AUTOSAR XML (schema 4-3-0)
package /CAN1/ISignalGroup
  18 x i signal group:
    CAN1_SG_ABM1: i-signal=[CAN1_ABM_Passenger_ODS_Sta, CAN1_ABM_RearPassengerCTR_ODS_Sta, CAN1_ABM_RearPassengerLH_ODS_Sta, CAN1_ABM_RearPassengerRH_ODS_Sta, CAN1_AirBagFailCmd, CAN1_Checksum_ABM1, CAN1_CrashOutputSts, CAN1_DriverSeatBeltCmd, CAN1_LifeCount_ABM1, CAN1_PABSwitchCmd, CAN1_PsngrSeatBeltCmd, CAN1_RCenterSeatBeltCmd, CAN1_RDriverSeatBeltCmd, CAN1_RPsngrSeatBeltCmd, CAN1_TLHPsngrSeatBeltCmd, CAN1_TRHPsngrSeatBeltCmd], system-signal-group=CAN1_SG_ABM1
    CAN1_SG_EPB1: i-signal=[CAN1_DOA_Sta, CAN1_EPB1_CS, CAN1_EPB1_RC, CAN1_EPBCarWashMode, CAN1_EPBErrSta, CAN1_EPBExtApplyAvail, CAN1_EPBExtReleaseAvail, CAN1_EPBMsg, CAN1_EPBRLampSta, CAN1_EPBSta, CAN1_EPBStaL, CAN1_EPBStaR, CAN1_TakeOverReq], system-signal-group=CAN1_SG_EPB1
    CAN1_SG_EPS1: i-signal=[CAN1_DriIntend, CAN1_EPS_AOI_Control, CAN1_EPS_AOI_Dis_R, CAN1_EPS_CS, CAN1_EPS_DMSMode_Sta, CAN1_EPS_ESABoostOut_Trq, CAN1_EPS_ESAInpBoost_Sta, CAN1_EPS_LDW_Activation, CAN1_EPS_LDW_Unavailable, CAN1_EPS_Pwr_Consumpt, CAN1_EPS_Pwr_Consumpt_V, CAN1_EPS_Pwr_Limit, CAN1_EPS_Pwr_Limit_V, CAN1_EPS_RC, CAN1_EPS_TOI_Activation, CAN1_EPS_TOI_Dis_R, CAN1_EPS_TOI_Fault, CAN1_EPS_TOI_Unavailable, CAN1_EPS_Temp, CAN1_EPS_Temp_V, CAN1_EPS_VOL, CAN1_EPS_VOL_V, CAN1_EpasFailed, CAN1_SAS_Angle, CAN1_SAS_CAL, CAN1_SAS_Speed, CAN1_SAS_Speed_Valid, CAN1_SAS_V, CAN1_Steering_Torque, CAN1_Steering_Torque_V], system-signal-group=CAN1_SG_EPS1
    CAN1_SG_ESC1: i-signal=[CAN1_ABS_Active, CAN1_ABS_Failed, CAN1_ABS_WnlmpSta, CAN1_AVH_Active, CAN1_AVH_Failed, CAN1_Amber_WnlmpSta, CAN1_BTCS_Active, CAN1_EBD_Active, CAN1_EBD_Failed, CAN1_ESC1_CS, CAN1_ESC1_RC, CAN1_ESC_Active, CAN1_ESC_BeepReq, CAN1_ESC_EstVehSpd, CAN1_ESC_EstVehSpd_V, CAN1_ESC_Failed, CAN1_ESC_OFF_Status, CAN1_ESC_Off_lmpSta, CAN1_ESC_TSA_Active, CAN1_ESC_WnlmpSta, CAN1_ESS_Active, CAN1_Fr_PTCS_Active, CAN1_FrntAxlTrqReq_Drv, CAN1_GRADE, CAN1_HBB_Active, CAN1_HBB_Failed, CAN1_HDD_Active, CAN1_HDD_Failed, CAN1_HSA_Active, CAN1_HSA_Failed, CAN1_LF_PulseCount, CAN1_LF_PulseCount_V, CAN1_LF_RawWhlSpeed, CAN1_LF_RawWhlSpeed_V, CAN1_LF_WhlRotDir, CAN1_LR_PulseCount, CAN1_LR_PulseCount_V, CAN1_LR_RawWhlSpeed, CAN1_LR_RawWhlSpeed_V, CAN1_LR_WhlRotDir, CAN1_PBA_Active, CAN1_PBA_Failed, CAN1_RF_PulseCount, CAN1_RF_PulseCount_V, CAN1_RF_RawWhlSpeed, CAN1_RF_RawWhlSpeed_V, CAN1_RF_WhlRotDir, CAN1_RR_PulseCount, CAN1_RR_PulseCount_V, CAN1_RR_RawWhlSpeed, CAN1_RR_RawWhlSpeed_V, CAN1_RR_WhlRotDir, CAN1_RearAxlTrqReq_Drv, CAN1_Red_WnlmpSta, CAN1_Rr_PTCS_Active, CAN1_SystemVoltage, CAN1_TCS_Active, CAN1_TCS_Failed, CAN1_VehSpeed], system-signal-group=CAN1_SG_ESC1
    CAN1_SG_ESC5: i-signal=[CAN1_ACCAvail, CAN1_AEBAvail, CAN1_ActBrkLamp_Sta, CAN1_BrkDiscTempSta, CAN1_BrkPedalPos, CAN1_BrkPedalPos_Sta, CAN1_BrkSw_Sta, CAN1_BrkSw_V, CAN1_DecErrSta, CAN1_ESC5_CS, CAN1_ESC5_RC, CAN1_ESC_ADAS_Sta, CAN1_ESC_APS_Sta, CAN1_ESC_DriverBrkOverride, CAN1_ESC_Standstill, CAN1_Fr_RBC_Active, CAN1_FrntAxlTrqReq_Brk, CAN1_LatAccel, CAN1_LatAccel_V, CAN1_LongAccel, CAN1_LongAccel_V, CAN1_MCPressure, CAN1_MCPressure_V, CAN1_Meter_Ind_VehSpeed, CAN1_RDC_Active, CAN1_RearAxlTrqReq_Brk, CAN1_Rr_RBC_Active, CAN1_YawRate, CAN1_YawRate_V], system-signal-group=CAN1_SG_ESC5
    CAN1_SG_FD1_APS2: i-signal=[CAN1_APS_D_FLL, CAN1_APS_D_FLR, CAN1_APS_D_RLL, CAN1_APS_D_RLR, CAN1_APS_ExitCondition, CAN1_APS_HW_Ver, CAN1_APS_Progress_PCT, CAN1_APS_RQ_Display, CAN1_APS_SW_Ver, CAN1_PAS_A_FCL, CAN1_PAS_A_FCR, CAN1_PAS_A_FML, CAN1_PAS_A_FMR, CAN1_PAS_A_RCL, CAN1_PAS_A_RCR, CAN1_PAS_A_RML, CAN1_PAS_A_RMR, CAN1_PAS_Chime, CAN1_PAS_D_FCL, CAN1_PAS_D_FCR, CAN1_PAS_D_FML, CAN1_PAS_D_FMR, CAN1_PAS_D_RCL, CAN1_PAS_D_RCR, CAN1_PAS_D_RML, CAN1_PAS_D_RMR, CAN1_PAS_Mod_Operation, CAN1_PAS_SNSR_Layout, CAN1_PAS_Sta_F_Sys, CAN1_USS_Sta_FCL, CAN1_USS_Sta_FCR, CAN1_USS_Sta_FLL, CAN1_USS_Sta_FLR, CAN1_USS_Sta_FML, CAN1_USS_Sta_FMR, CAN1_USS_Sta_RCL, CAN1_USS_Sta_RCR, CAN1_USS_Sta_RLL, CAN1_USS_Sta_RLR, CAN1_USS_Sta_RML, CAN1_USS_Sta_RMR], system-signal-group=CAN1_SG_FD1_APS2
    CAN1_SG_FD1_APS3: i-signal=[CAN1_APS3_LifeCount, CAN1_APS3_checksum, CAN1_APSOpenPTG, CAN1_APS_DecReq, CAN1_APS_DecReq_A, CAN1_APS_Req, CAN1_APS_Sta_System, CAN1_CAAS_Sta, CAN1_FDC_APS_Active_Sta, CAN1_FDC_APS_CaasActive_Sta, CAN1_FDC_APS_CaasCtrlAvail_Sta, CAN1_FDC_APS_CaasVMCReqA_Cmd, CAN1_FDC_APS_CtrlAvail_Sta, CAN1_FDC_APS_ShftPosnReq_Cmd, CAN1_FDC_APS_SpeedReq_Cmd, CAN1_FDC_APS_VMCReqA_Cmd, CAN1_FDC_RAPS_BCMLamp_Cmd, CAN1_FDC_RAPS_BCMLockReq_Cmd, CAN1_FDC_RAPS_ErrLv1_Flg, CAN1_FDC_RAPS_PwrReqAvail_Sta, CAN1_FDC_RAPS_PwrReq_Cmd, CAN1_FDC_VCU_RAPSErrLv2_Flg, CAN1_FDC_VCU_RAPSErrLv3_Flg, CAN1_FDC_VMC_APS_Angle_Target, CAN1_FDC_VMC_APS_Rq_EPS_Ctrl, CAN1_FDC_VMC_APS_V_Rq_EPS_Ctrl, CAN1_SPTGDet, CAN1_SPTG_Sta], system-signal-group=CAN1_SG_FD1_APS3
    CAN1_SG_FD1_BCM1: i-signal=[CAN1_AllDoorSW, CAN1_AntiTheftSeatFold, CAN1_AntitheftSta, CAN1_BCM_Buzzer_Req, CAN1_BCM_DoorLock_Sta, CAN1_BrakeLamp, CAN1_CTDCtrl, CAN1_CTDLockSW, CAN1_CTDUnlockSW, CAN1_CrashDetd, CAN1_Dimmer, CAN1_DimmerEN, CAN1_DoorLockIND, CAN1_DrDoorSW, CAN1_Fr_ChargingDoorCtrl, CAN1_Fr_FogLamp, CAN1_Fr_Wiper_H, CAN1_Fr_Wiper_L, CAN1_H_Beam, CAN1_HazardSW, CAN1_HoodSW, CAN1_HornCtrl, CAN1_LBSD, CAN1_LDRL, CAN1_LTurnLP, CAN1_L_APM_WdwEnable, CAN1_L_Beam, CAN1_LockSetting, CAN1_MirrorCtrl, CAN1_MirrorDefog, CAN1_PosLamp, CAN1_PsDoorSW, CAN1_RBSD, CAN1_RDRL, CAN1_RLDoorSW, CAN1_RRDoorSW, CAN1_RTurnLP, CAN1_ReverseLamp, CAN1_RoomLampH, CAN1_RoomLampL, CAN1_Rr_ChargingDoorCtrl, CAN1_Rr_Defog, CAN1_Rr_FogLamp, CAN1_Rr_Wiper, CAN1_TailgateHDSW, CAN1_TailgateRemote, CAN1_Tailgate_SW, CAN1_TrunkRel, CAN1_WasherCtrl, CAN1_WiperFixMode], system-signal-group=CAN1_SG_FD1_BCM1
    CAN1_SG_FD1_THCM1: i-signal=[CAN1_BatteryMode, CAN1_CCU_ACLampSts, CAN1_CCU_ACMaxLampSts, CAN1_CCU_AutoLampSts, CAN1_CCU_AutoMidLampSts, CAN1_CCU_Dispaly_Request, CAN1_CCU_EcoSts, CAN1_CCU_FrtOnOffLampSts, CAN1_CCU_HEATMaxLampSts, CAN1_CCU_RrOnOffLampSts, CAN1_CCU_SyncLampSts, CAN1_CabinMode, CAN1_EDriveMode, CAN1_FD_AGS_Cmd, CAN1_FD_RecyAuto_Cmd, CAN1_Fr_Coolantflow, CAN1_Fr_Coolanttemp, CAN1_HPThermalRecoveryReq, CAN1_Rr_Coolantflow, CAN1_Rr_Coolanttemp, CAN1_sigAirIntenZon1St, CAN1_sigAirIntenZon3St, CAN1_sigAmbAirT, CAN1_sigCbnAirT, CAN1_sigCbnPTCPwrAct, CAN1_sigCbnSolarLeft, CAN1_sigCbnSolarRight, CAN1_sigClmtCmprPwrAct, CAN1_sigClntTHvBattOut, CAN1_sigDfrstSt, CAN1_sigHvacSt, CAN1_sigRecircSt, CAN1_sigSetTempZon1St, CAN1_sigSetTempZon2St, CAN1_sigSetTempZon3St, CAN1_sigWindDirZon1St, CAN1_sigWindDirZon3St], system-signal-group=CAN1_SG_FD1_THCM1
    CAN1_SG_FD1_VCU1: i-signal=[CAN1_CC_Crl_Sta, CAN1_Eng_AGSCloseSta, CAN1_Eng_ActvDmpDisabSta, CAN1_Eng_CoastDwSta, CAN1_Eng_PwrLockSta, CAN1_HVPwrSta, CAN1_LVPwrSta, CAN1_MSA_Crl_Sta, CAN1_P_Button_Sta, CAN1_PrkReq, CAN1_PrkReqValid, CAN1_PwrSta, CAN1_ShiftGearPosn, CAN1_VehMalfunLevel, CAN1_XWDMode], system-signal-group=CAN1_SG_FD1_VCU1
    CAN1_SG_FD1_VCU2: i-signal=[CAN1_ACC_CtrlAvail, CAN1_AccPedal_Override, CAN1_ActAPSPosn, CAN1_CS_VCU2_CAN1, CAN1_DriverTq, CAN1_Fr_DriverTq, CAN1_RC_VCU2_CAN1, CAN1_Rr_DriverTq, CAN1_VehActPwr], system-signal-group=CAN1_SG_FD1_VCU2
    CAN1_SG_FD1_VCU3: i-signal=[CAN1_CS_VCU3_CAN1, CAN1_EquivAccPedalSWSta, CAN1_Fr_EDUAvailBrkRgnTq, CAN1_Fr_EDUAvailBrkRgnTqValid, CAN1_Fr_EDURealARgnTq, CAN1_Fr_EDURealDrvOrBRgnTq, CAN1_Fr_EDUSpd, CAN1_Fr_EDUSpdValid, CAN1_Fr_RgnDecrSta, CAN1_Fr_RgnPermSta, CAN1_PTCS_PermSta, CAN1_RC_VCU3_CAN1, CAN1_RgnAbnorSta, CAN1_Rr_EDUAvailBrkRgnTq, CAN1_Rr_EDUAvailBrkRgnTqValid, CAN1_Rr_EDURealARgnTq, CAN1_Rr_EDURealDrvOrBRgnTq, CAN1_Rr_EDUSpd, CAN1_Rr_EDUSpdValid, CAN1_Rr_RgnDecrSta, CAN1_Rr_RgnPermSta], system-signal-group=CAN1_SG_FD1_VCU3
    CAN1_SG_FD1_VMC1: i-signal=[CAN1_AccCalcuPID, CAN1_CCMSA_SpdWar, CAN1_DISCReqAcc, CAN1_DISC_ButtSta, CAN1_DISC_DISCTargetSpd, CAN1_DISC_DISCTurn, CAN1_DISC_Sta, CAN1_FeatArbitrFinal, CAN1_FeatArbitrSta, CAN1_FeatReqSpd, CAN1_FeatSetSpdFinal_raw32, CAN1_FrontRearSlipRatioCtrl, CAN1_JerkPCT, CAN1_LatAccCtrl, CAN1_LateralCtrl, CAN1_LimitPCT, CAN1_MeterIndSpeed_raw32, CAN1_RearWhlSlipRatioCtrl, CAN1_SPD2ACCAct, CAN1_SafetyCtrl, CAN1_SingleWhlSlipRatioCtrl, CAN1_TimeGapCalcu, CAN1_VMC_ACCCtrlAvail, CAN1_VMC_AEBCtrlAvail, CAN1_VMC_CCCtrlAvail, CAN1_VMC_MSACtrlAvail, CAN1_VMC_VCU_ACC_CtrlAvail, CAN1_VMC_VCU_APSCtrlAvail_flg, CAN1_VMC_VCU_AccPedal_Override, CAN1_VMC_VCU_CC_Crl_Sta, CAN1_VMC_VCU_MSA_Crl_Sta, CAN1_VehicleSpeed_kph, CAN1_VehicleSpeed_mph], system-signal-group=CAN1_SG_FD1_VMC1
    CAN1_SG_FD1_VMC2: i-signal=[CAN1_FDC_VMC_RWS_Actv_Sta, CAN1_FDC_VMC_RWS_Dfctv_Sta, CAN1_FDC_VMC_RWS_PositionReq_Cmd, CAN1_FDC_VMC_SteerFaultReq_Cmd], system-signal-group=CAN1_SG_FD1_VMC2
    CAN1_SG_GW1_CE100_0: i-signal=[CAN1_BMS_READY, CAN1_Fr_TMSpd, CAN1_Rr_TMSpd], system-signal-group=CAN1_SG_GW1_CE100_0
    CAN1_SG_GW1_CE200_0: i-signal=[CAN1_ESC_SW_Cmd, CAN1_Roll_Eng_Mode, CAN1_Roll_Mode_SW_Cmd, CAN1_TCS_SW_Cmd], system-signal-group=CAN1_SG_GW1_CE200_0
    CAN1_SG_VMC_FCM1: i-signal=[CAN1_FDC_VMC_AngCtrlTqWtGn, CAN1_FDC_VMC_DMSMode_Cmd, CAN1_FDC_VMC_DrInpTqBstAct, CAN1_FDC_VMC_DrInpTqBstGn, CAN1_FDC_VMC_MaxAngCtrlOutTqLim, CAN1_VMC_ACC_ComfortBandLower, CAN1_VMC_ACC_ComfortBandUpper, CAN1_VMC_ACC_JerkLowerLInit, CAN1_VMC_ACC_JerkUpperLInit, CAN1_VMC_ACC_RequiredAccel, CAN1_VMC_ACC_VehHoldReq, CAN1_VMC_ADAS_ACC_Sta, CAN1_VMC_ADAS_AEBReq, CAN1_VMC_ADAS_AEB_Sta, CAN1_VMC_ADAS_DBSReq, CAN1_VMC_ADAS_FaultSta, CAN1_VMC_AEB_VehHoldReq, CAN1_VMC_FCM1_Checksum, CAN1_VMC_FCM1_LifeCount, CAN1_VMC_FCM_LDW_Fault, CAN1_VMC_FCM_LDW_Request, CAN1_VMC_FCM_LKA_StrToqReq, CAN1_VMC_FCM_LKA_TOIAct, CAN1_VMC_FCM_LKA_TOIFault], system-signal-group=CAN1_SG_VMC_FCM1
    CAN1_SG_eBST1: i-signal=[CAN1_LowBrakeFluid_Sta, CAN1_eBST_AmberWnlmpSta, CAN1_eBST_BeepReq, CAN1_eBST_RedWnlmpSta], system-signal-group=CAN1_SG_eBST1
package /CAN1/Cluster
  can cluster CAN1: baudrate=500, can-fd-baudrate=2000
    can physical channel CAN1: comm-connectors=ConnCAN1
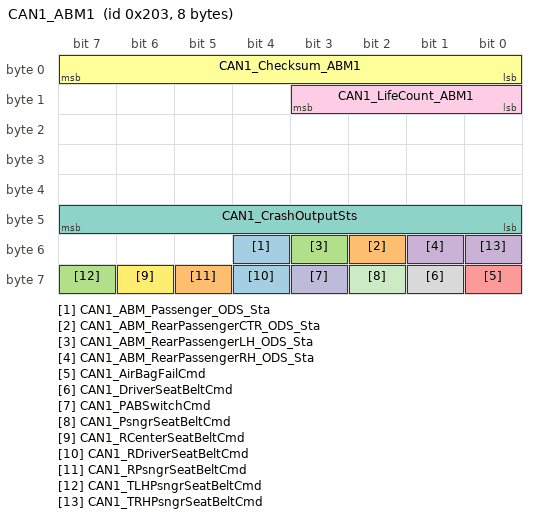
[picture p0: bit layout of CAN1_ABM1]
      frame CAN1_ABM1: id 0x203, frame-length=8, can-addressing-mode=STANDARD, can-fd-frame-support=true, can-frame-rx-behavior=CAN-FD, can-frame-tx-behavior=CAN-FD
        pdu CAN1_ABM1: length=8, minimum-delay=0.0, transmission-mode-true-timing={cyclic-timing=time-period=0.5, event-controlled-timing={number-of-repetitions=0, repetition-period=0}}, unused-bit-pattern=0
          mapping CAN1_SG_ABM1: i-signal-group=CAN1_SG_ABM1, start-position=0, transfer-property=TRIGGERED-ON-CHANGE
          signal CAN1_ABM_Passenger_ODS_Sta: start 52, 1 bit, big-endian, i-signal-type=PRIMITIVE, init-value=constant-reference=Init_CAN1_ABM_Passenger_ODS_Sta, base-type=uint8, implementation-data-type=uint8, transfer-property=TRIGGERED-ON-CHANGE
          signal CAN1_ABM_RearPassengerCTR_ODS_Sta: start 50, 1 bit, big-endian, i-signal-type=PRIMITIVE, init-value=constant-reference=Init_CAN1_ABM_RearPassengerCTR_ODS_Sta, base-type=uint8, implementation-data-type=uint8, transfer-property=TRIGGERED-ON-CHANGE
          signal CAN1_ABM_RearPassengerLH_ODS_Sta: start 51, 1 bit, big-endian, i-signal-type=PRIMITIVE, init-value=constant-reference=Init_CAN1_ABM_RearPassengerLH_ODS_Sta, base-type=uint8, implementation-data-type=uint8, transfer-property=TRIGGERED-ON-CHANGE
          signal CAN1_ABM_RearPassengerRH_ODS_Sta: start 49, 1 bit, big-endian, i-signal-type=PRIMITIVE, init-value=constant-reference=Init_CAN1_ABM_RearPassengerRH_ODS_Sta, base-type=uint8, implementation-data-type=uint8, transfer-property=TRIGGERED-ON-CHANGE
          signal CAN1_AirBagFailCmd: start 56, 1 bit, big-endian, i-signal-type=PRIMITIVE, init-value=constant-reference=Init_CAN1_AirBagFailCmd, base-type=uint8, implementation-data-type=uint8, transfer-property=TRIGGERED-ON-CHANGE
          signal CAN1_Checksum_ABM1: start 7, 8 bit, big-endian, i-signal-type=PRIMITIVE, init-value=constant-reference=Init_CAN1_Checksum_ABM1, base-type=uint8, implementation-data-type=uint8, transfer-property=TRIGGERED-ON-CHANGE
          signal CAN1_CrashOutputSts: start 47, 8 bit, big-endian, i-signal-type=PRIMITIVE, init-value=constant-reference=Init_CAN1_CrashOutputSts, base-type=uint8, implementation-data-type=uint8, transfer-property=TRIGGERED-ON-CHANGE
          signal CAN1_DriverSeatBeltCmd: start 57, 1 bit, big-endian, i-signal-type=PRIMITIVE, init-value=constant-reference=Init_CAN1_DriverSeatBeltCmd, base-type=uint8, implementation-data-type=uint8, transfer-property=TRIGGERED-ON-CHANGE
          signal CAN1_LifeCount_ABM1: start 11, 4 bit, big-endian, i-signal-type=PRIMITIVE, init-value=constant-reference=Init_CAN1_LifeCount_ABM1, base-type=uint8, implementation-data-type=uint8, transfer-property=TRIGGERED-ON-CHANGE
          signal CAN1_PABSwitchCmd: start 59, 1 bit, big-endian, i-signal-type=PRIMITIVE, init-value=constant-reference=Init_CAN1_PABSwitchCmd, base-type=uint8, implementation-data-type=uint8, transfer-property=TRIGGERED-ON-CHANGE
          signal CAN1_PsngrSeatBeltCmd: start 58, 1 bit, big-endian, i-signal-type=PRIMITIVE, init-value=constant-reference=Init_CAN1_PsngrSeatBeltCmd, base-type=uint8, implementation-data-type=uint8, transfer-property=TRIGGERED-ON-CHANGE
          signal CAN1_RCenterSeatBeltCmd: start 62, 1 bit, big-endian, i-signal-type=PRIMITIVE, init-value=constant-reference=Init_CAN1_RCenterSeatBeltCmd, base-type=uint8, implementation-data-type=uint8, transfer-property=TRIGGERED-ON-CHANGE
          signal CAN1_RDriverSeatBeltCmd: start 60, 1 bit, big-endian, i-signal-type=PRIMITIVE, init-value=constant-reference=Init_CAN1_RDriverSeatBeltCmd, base-type=uint8, implementation-data-type=uint8, transfer-property=TRIGGERED-ON-CHANGE
          signal CAN1_RPsngrSeatBeltCmd: start 61, 1 bit, big-endian, i-signal-type=PRIMITIVE, init-value=constant-reference=Init_CAN1_RPsngrSeatBeltCmd, base-type=uint8, implementation-data-type=uint8, transfer-property=TRIGGERED-ON-CHANGE
          signal CAN1_TLHPsngrSeatBeltCmd: start 63, 1 bit, big-endian, i-signal-type=PRIMITIVE, init-value=constant-reference=Init_CAN1_TLHPsngrSeatBeltCmd, base-type=uint8, implementation-data-type=uint8, transfer-property=TRIGGERED-ON-CHANGE
          signal CAN1_TRHPsngrSeatBeltCmd: start 48, 1 bit, big-endian, i-signal-type=PRIMITIVE, init-value=constant-reference=Init_CAN1_TRHPsngrSeatBeltCmd, base-type=uint8, implementation-data-type=uint8, transfer-property=TRIGGERED-ON-CHANGE
      frame CAN1_DiagFuncReqFT: id 0x7D0, frame-length=8, can-addressing-mode=STANDARD, can-fd-frame-support=false, can-frame-rx-behavior=CAN-20, can-frame-tx-behavior=CAN-20
        n pdu CAN1_DiagFuncReqFT: length=8
      frame CAN1_DiagFuncReqOBD: id 0x7DF, frame-length=8, can-addressing-mode=STANDARD, can-fd-frame-support=true, can-frame-rx-behavior=CAN-FD, can-frame-tx-behavior=CAN-FD
        n pdu CAN1_DiagFuncReqOBD: length=8
      frame CAN1_DiagPhysReqToABM: id 0x6B1, frame-length=8, can-addressing-mode=STANDARD, can-fd-frame-support=true, can-frame-rx-behavior=CAN-FD, can-frame-tx-behavior=CAN-FD
        n pdu CAN1_DiagPhysReqToABM: length=8
      frame CAN1_DiagPhysReqToEPS: id 0x6A1, frame-length=8, can-addressing-mode=STANDARD, can-fd-frame-support=true, can-frame-rx-behavior=CAN-FD, can-frame-tx-behavior=CAN-FD
        n pdu CAN1_DiagPhysReqToEPS: length=8
      frame CAN1_DiagPhysReqToESC: id 0x681, frame-length=8, can-addressing-mode=STANDARD, can-fd-frame-support=false, can-frame-rx-behavior=CAN-20, can-frame-tx-behavior=CAN-20
        n pdu CAN1_DiagPhysReqToESC: length=8
      frame CAN1_DiagPhysReqToOCS: id 0x6A2, frame-length=64, can-addressing-mode=STANDARD, can-fd-frame-support=true, can-frame-rx-behavior=CAN-FD, can-frame-tx-behavior=CAN-FD
        n pdu CAN1_DiagPhysReqToOCS: length=8
      frame CAN1_DiagPhysReqToScrap: id 0x7F1, frame-length=8, can-addressing-mode=STANDARD, can-fd-frame-support=true, can-frame-rx-behavior=CAN-FD, can-frame-tx-behavior=CAN-FD
        n pdu CAN1_DiagPhysReqToScrap: length=8
      frame CAN1_DiagPhysReqToeBST: id 0x691, frame-length=8, can-addressing-mode=STANDARD, can-fd-frame-support=false, can-frame-rx-behavior=CAN-20, can-frame-tx-behavior=CAN-20
        n pdu CAN1_DiagPhysReqToeBST: length=8
      frame CAN1_DiagRespFromABM: id 0x631, frame-length=8, can-addressing-mode=STANDARD, can-fd-frame-support=true, can-frame-rx-behavior=CAN-FD, can-frame-tx-behavior=CAN-FD
        n pdu CAN1_DiagRespFromABM: length=8
      frame CAN1_DiagRespFromEPS: id 0x621, frame-length=8, can-addressing-mode=STANDARD, can-fd-frame-support=true, can-frame-rx-behavior=CAN-FD, can-frame-tx-behavior=CAN-FD
        n pdu CAN1_DiagRespFromEPS: length=8
      frame CAN1_DiagRespFromESC: id 0x601, frame-length=8, can-addressing-mode=STANDARD, can-fd-frame-support=false, can-frame-rx-behavior=CAN-20, can-frame-tx-behavior=CAN-20
        n pdu CAN1_DiagRespFromESC: length=8
      frame CAN1_DiagRespFromOCS: id 0x622, frame-length=64, can-addressing-mode=STANDARD, can-fd-frame-support=true, can-frame-rx-behavior=CAN-FD, can-frame-tx-behavior=CAN-FD
        n pdu CAN1_DiagRespFromOCS: length=8
      frame CAN1_DiagRespFromScrap: id 0x7F9, frame-length=8, can-addressing-mode=STANDARD, can-fd-frame-support=true, can-frame-rx-behavior=CAN-FD, can-frame-tx-behavior=CAN-FD
        n pdu CAN1_DiagRespFromScrap: length=8
      frame CAN1_DiagRespFromeBST: id 0x611, frame-length=8, can-addressing-mode=STANDARD, can-fd-frame-support=false, can-frame-rx-behavior=CAN-20, can-frame-tx-behavior=CAN-20
        n pdu CAN1_DiagRespFromeBST: length=8
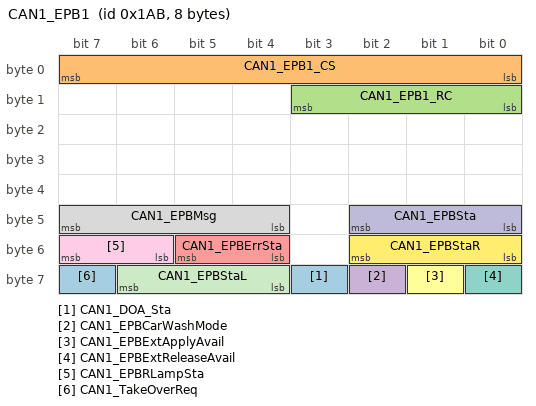
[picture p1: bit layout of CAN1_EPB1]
      frame CAN1_EPB1: id 0x1AB, frame-length=8, can-addressing-mode=STANDARD, can-fd-frame-support=true, can-frame-rx-behavior=CAN-FD, can-frame-tx-behavior=CAN-FD
        pdu CAN1_EPB1: length=8, minimum-delay=0.0, transmission-mode-true-timing=cyclic-timing=time-period=0.04, unused-bit-pattern=0
          mapping CAN1_SG_EPB1: i-signal-group=CAN1_SG_EPB1, start-position=0, transfer-property=PENDING
          signal CAN1_DOA_Sta: start 59, 1 bit, big-endian, i-signal-type=PRIMITIVE, init-value=constant-reference=Init_CAN1_DOA_Sta, base-type=uint8, implementation-data-type=uint8, transfer-property=PENDING
          signal CAN1_EPB1_CS: start 7, 8 bit, big-endian, i-signal-type=PRIMITIVE, init-value=constant-reference=Init_CAN1_EPB1_CS, base-type=uint8, implementation-data-type=uint8, transfer-property=PENDING
          signal CAN1_EPB1_RC: start 11, 4 bit, big-endian, i-signal-type=PRIMITIVE, init-value=constant-reference=Init_CAN1_EPB1_RC, base-type=uint8, implementation-data-type=uint8, transfer-property=PENDING
          signal CAN1_EPBCarWashMode: start 58, 1 bit, big-endian, i-signal-type=PRIMITIVE, init-value=constant-reference=Init_CAN1_EPBCarWashMode, base-type=uint8, implementation-data-type=uint8, transfer-property=PENDING
          signal CAN1_EPBErrSta: start 53, 2 bit, big-endian, i-signal-type=PRIMITIVE, init-value=constant-reference=Init_CAN1_EPBErrSta, base-type=uint8, implementation-data-type=uint8, transfer-property=PENDING
          signal CAN1_EPBExtApplyAvail: start 57, 1 bit, big-endian, i-signal-type=PRIMITIVE, init-value=constant-reference=Init_CAN1_EPBExtApplyAvail, base-type=uint8, implementation-data-type=uint8, transfer-property=PENDING
          signal CAN1_EPBExtReleaseAvail: start 56, 1 bit, big-endian, i-signal-type=PRIMITIVE, init-value=constant-reference=Init_CAN1_EPBExtReleaseAvail, base-type=uint8, implementation-data-type=uint8, transfer-property=PENDING
          signal CAN1_EPBMsg: start 47, 4 bit, big-endian, i-signal-type=PRIMITIVE, init-value=constant-reference=Init_CAN1_EPBMsg, base-type=uint8, implementation-data-type=uint8, transfer-property=PENDING
          signal CAN1_EPBRLampSta: start 55, 2 bit, big-endian, i-signal-type=PRIMITIVE, init-value=constant-reference=Init_CAN1_EPBRLampSta, base-type=uint8, implementation-data-type=uint8, transfer-property=PENDING
          signal CAN1_EPBSta: start 42, 3 bit, big-endian, i-signal-type=PRIMITIVE, init-value=constant-reference=Init_CAN1_EPBSta, base-type=uint8, implementation-data-type=uint8, transfer-property=PENDING
          signal CAN1_EPBStaL: start 62, 3 bit, big-endian, i-signal-type=PRIMITIVE, init-value=constant-reference=Init_CAN1_EPBStaL, base-type=uint8, implementation-data-type=uint8, transfer-property=PENDING
          signal CAN1_EPBStaR: start 50, 3 bit, big-endian, i-signal-type=PRIMITIVE, init-value=constant-reference=Init_CAN1_EPBStaR, base-type=uint8, implementation-data-type=uint8, transfer-property=PENDING
          signal CAN1_TakeOverReq: start 63, 1 bit, big-endian, i-signal-type=PRIMITIVE, init-value=constant-reference=Init_CAN1_TakeOverReq, base-type=uint8, implementation-data-type=uint8, transfer-property=PENDING
      frame CAN1_EPS1: id 0x187, frame-length=16, can-addressing-mode=STANDARD, can-fd-frame-support=true, can-frame-rx-behavior=CAN-FD, can-frame-tx-behavior=CAN-FD
        pdu CAN1_EPS1: length=16, minimum-delay=0.0, transmission-mode-true-timing=cyclic-timing=time-period=0.01, unused-bit-pattern=0
          mapping CAN1_SG_EPS1: i-signal-group=CAN1_SG_EPS1, start-position=0, transfer-property=PENDING
          signal CAN1_DriIntend: start 18, 2 bit, big-endian, i-signal-type=PRIMITIVE, init-value=constant-reference=Init_CAN1_DriIntend, base-type=uint8, implementation-data-type=uint8, transfer-property=PENDING
          signal CAN1_EPS_AOI_Control: start 20, 2 bit, big-endian, i-signal-type=PRIMITIVE, init-value=constant-reference=Init_CAN1_EPS_AOI_Control, base-type=uint8, implementation-data-type=uint8, transfer-property=PENDING
          signal CAN1_EPS_AOI_Dis_R: start 28, 4 bit, big-endian, i-signal-type=PRIMITIVE, init-value=constant-reference=Init_CAN1_EPS_AOI_Dis_R, base-type=uint8, implementation-data-type=uint8, transfer-property=PENDING
          signal CAN1_EPS_CS: start 7, 8 bit, big-endian, i-signal-type=PRIMITIVE, init-value=constant-reference=Init_CAN1_EPS_CS, base-type=uint8, implementation-data-type=uint8, transfer-property=PENDING
          signal CAN1_EPS_DMSMode_Sta: start 123, 4 bit, big-endian, i-signal-type=PRIMITIVE, init-value=constant-reference=Init_CAN1_EPS_DMSMode_Sta, base-type=uint8, implementation-data-type=uint8, transfer-property=PENDING
          signal CAN1_EPS_ESABoostOut_Trq: start 111, 6 bit, big-endian, i-signal-type=PRIMITIVE, init-value=constant-reference=Init_CAN1_EPS_ESABoostOut_Trq, base-type=uint8, implementation-data-type=uint8, transfer-property=PENDING
          signal CAN1_EPS_ESAInpBoost_Sta: start 105, 1 bit, big-endian, i-signal-type=PRIMITIVE, init-value=constant-reference=Init_CAN1_EPS_ESAInpBoost_Sta, base-type=uint8, implementation-data-type=uint8, transfer-property=PENDING
          signal CAN1_EPS_LDW_Activation: start 90, 2 bit, big-endian, i-signal-type=PRIMITIVE, init-value=constant-reference=Init_CAN1_EPS_LDW_Activation, base-type=uint8, implementation-data-type=uint8, transfer-property=PENDING
          signal CAN1_EPS_LDW_Unavailable: start 91, 1 bit, big-endian, i-signal-type=PRIMITIVE, init-value=constant-reference=Init_CAN1_EPS_LDW_Unavailable, base-type=uint8, implementation-data-type=uint8, transfer-property=PENDING
          signal CAN1_EPS_Pwr_Consumpt: start 104, 9 bit, big-endian, i-signal-type=PRIMITIVE, init-value=constant-reference=Init_CAN1_EPS_Pwr_Consumpt, base-type=uint16, implementation-data-type=uint16, transfer-property=PENDING
          signal CAN1_EPS_Pwr_Consumpt_V: start 61, 1 bit, big-endian, i-signal-type=PRIMITIVE, init-value=constant-reference=Init_CAN1_EPS_Pwr_Consumpt_V, base-type=uint8, implementation-data-type=uint8, transfer-property=PENDING
          signal CAN1_EPS_Pwr_Limit: start 88, 9 bit, big-endian, i-signal-type=PRIMITIVE, init-value=constant-reference=Init_CAN1_EPS_Pwr_Limit, base-type=uint16, implementation-data-type=uint16, transfer-property=PENDING
          signal CAN1_EPS_Pwr_Limit_V: start 59, 1 bit, big-endian, i-signal-type=PRIMITIVE, init-value=constant-reference=Init_CAN1_EPS_Pwr_Limit_V, base-type=uint8, implementation-data-type=uint8, transfer-property=PENDING
          signal CAN1_EPS_RC: start 11, 4 bit, big-endian, i-signal-type=PRIMITIVE, init-value=constant-reference=Init_CAN1_EPS_RC, base-type=uint8, implementation-data-type=uint8, transfer-property=PENDING
          signal CAN1_EPS_TOI_Activation: start 21, 1 bit, big-endian, i-signal-type=PRIMITIVE, init-value=constant-reference=Init_CAN1_EPS_TOI_Activation, base-type=uint8, implementation-data-type=uint8, transfer-property=PENDING
          signal CAN1_EPS_TOI_Dis_R: start 16, 4 bit, big-endian, i-signal-type=PRIMITIVE, init-value=constant-reference=Init_CAN1_EPS_TOI_Dis_R, base-type=uint8, implementation-data-type=uint8, transfer-property=PENDING
          signal CAN1_EPS_TOI_Fault: start 23, 1 bit, big-endian, i-signal-type=PRIMITIVE, init-value=constant-reference=Init_CAN1_EPS_TOI_Fault, base-type=uint8, implementation-data-type=uint8, transfer-property=PENDING
          signal CAN1_EPS_TOI_Unavailable: start 22, 1 bit, big-endian, i-signal-type=PRIMITIVE, init-value=constant-reference=Init_CAN1_EPS_TOI_Unavailable, base-type=uint8, implementation-data-type=uint8, transfer-property=PENDING
          signal CAN1_EPS_Temp: start 87, 8 bit, big-endian, i-signal-type=PRIMITIVE, init-value=constant-reference=Init_CAN1_EPS_Temp, base-type=uint8, implementation-data-type=uint8, transfer-property=PENDING
          signal CAN1_EPS_Temp_V: start 93, 1 bit, big-endian, i-signal-type=PRIMITIVE, init-value=constant-reference=Init_CAN1_EPS_Temp_V, base-type=uint8, implementation-data-type=uint8, transfer-property=PENDING
          signal CAN1_EPS_VOL: start 79, 8 bit, big-endian, i-signal-type=PRIMITIVE, init-value=constant-reference=Init_CAN1_EPS_VOL, base-type=uint8, implementation-data-type=uint8, transfer-property=PENDING
          signal CAN1_EPS_VOL_V: start 92, 1 bit, big-endian, i-signal-type=PRIMITIVE, init-value=constant-reference=Init_CAN1_EPS_VOL_V, base-type=uint8, implementation-data-type=uint8, transfer-property=PENDING
          signal CAN1_EpasFailed: start 95, 2 bit, big-endian, i-signal-type=PRIMITIVE, init-value=constant-reference=Init_CAN1_EpasFailed, base-type=uint8, implementation-data-type=uint8, transfer-property=PENDING
          signal CAN1_SAS_Angle: start 47, 16 bit, big-endian, i-signal-type=PRIMITIVE, init-value=constant-reference=Init_CAN1_SAS_Angle, base-type=uint16, implementation-data-type=uint16, transfer-property=PENDING
          signal CAN1_SAS_CAL: start 63, 1 bit, big-endian, i-signal-type=PRIMITIVE, init-value=constant-reference=Init_CAN1_SAS_CAL, base-type=uint8, implementation-data-type=uint8, transfer-property=PENDING
          signal CAN1_SAS_Speed: start 39, 8 bit, big-endian, i-signal-type=PRIMITIVE, init-value=constant-reference=Init_CAN1_SAS_Speed, base-type=uint8, implementation-data-type=uint8, transfer-property=PENDING
          signal CAN1_SAS_Speed_Valid: start 62, 1 bit, big-endian, i-signal-type=PRIMITIVE, init-value=constant-reference=Init_CAN1_SAS_Speed_Valid, base-type=uint8, implementation-data-type=uint8, transfer-property=PENDING
          signal CAN1_SAS_V: start 24, 1 bit, big-endian, i-signal-type=PRIMITIVE, init-value=constant-reference=Init_CAN1_SAS_V, base-type=uint8, implementation-data-type=uint8, transfer-property=PENDING
          signal CAN1_Steering_Torque: start 58, 11 bit, big-endian, i-signal-type=PRIMITIVE, init-value=constant-reference=Init_CAN1_Steering_Torque, base-type=uint16, implementation-data-type=uint16, transfer-property=PENDING
          signal CAN1_Steering_Torque_V: start 60, 1 bit, big-endian, i-signal-type=PRIMITIVE, init-value=constant-reference=Init_CAN1_Steering_Torque_V, base-type=uint8, implementation-data-type=uint8, transfer-property=PENDING
      frame CAN1_ESC1: id 0x152, frame-length=32, can-addressing-mode=STANDARD, can-fd-frame-support=true, can-frame-rx-behavior=CAN-FD, can-frame-tx-behavior=CAN-FD
        pdu CAN1_ESC1: length=32, minimum-delay=0.0, transmission-mode-true-timing=cyclic-timing=time-period=0.01, unused-bit-pattern=0
          mapping CAN1_SG_ESC1: i-signal-group=CAN1_SG_ESC1, start-position=0, transfer-property=PENDING
          signal CAN1_ABS_Active: start 187, 1 bit, big-endian, i-signal-type=PRIMITIVE, init-value=constant-reference=Init_CAN1_ABS_Active, base-type=uint8, implementation-data-type=uint8, transfer-property=PENDING
          signal CAN1_ABS_Failed: start 183, 1 bit, big-endian, i-signal-type=PRIMITIVE, init-value=constant-reference=Init_CAN1_ABS_Failed, base-type=uint8, implementation-data-type=uint8, transfer-property=PENDING
          signal CAN1_ABS_WnlmpSta: start 206, 1 bit, big-endian, i-signal-type=PRIMITIVE, init-value=constant-reference=Init_CAN1_ABS_WnlmpSta, base-type=uint8, implementation-data-type=uint8, transfer-property=PENDING
          signal CAN1_AVH_Active: start 177, 1 bit, big-endian, i-signal-type=PRIMITIVE, init-value=constant-reference=Init_CAN1_AVH_Active, base-type=uint8, implementation-data-type=uint8, transfer-property=PENDING
          signal CAN1_AVH_Failed: start 173, 1 bit, big-endian, i-signal-type=PRIMITIVE, init-value=constant-reference=Init_CAN1_AVH_Failed, base-type=uint8, implementation-data-type=uint8, transfer-property=PENDING
          signal CAN1_Amber_WnlmpSta: start 178, 1 bit, big-endian, i-signal-type=PRIMITIVE, init-value=constant-reference=Init_CAN1_Amber_WnlmpSta, base-type=uint8, implementation-data-type=uint8, transfer-property=PENDING
          signal CAN1_BTCS_Active: start 179, 1 bit, big-endian, i-signal-type=PRIMITIVE, init-value=constant-reference=Init_CAN1_BTCS_Active, base-type=uint8, implementation-data-type=uint8, transfer-property=PENDING
          signal CAN1_EBD_Active: start 186, 1 bit, big-endian, i-signal-type=PRIMITIVE, init-value=constant-reference=Init_CAN1_EBD_Active, base-type=uint8, implementation-data-type=uint8, transfer-property=PENDING
          signal CAN1_EBD_Failed: start 182, 1 bit, big-endian, i-signal-type=PRIMITIVE, init-value=constant-reference=Init_CAN1_EBD_Failed, base-type=uint8, implementation-data-type=uint8, transfer-property=PENDING
          signal CAN1_ESC1_CS: start 7, 8 bit, big-endian, i-signal-type=PRIMITIVE, init-value=constant-reference=Init_CAN1_ESC1_CS, base-type=uint8, implementation-data-type=uint8, transfer-property=PENDING
          signal CAN1_ESC1_RC: start 11, 4 bit, big-endian, i-signal-type=PRIMITIVE, init-value=constant-reference=Init_CAN1_ESC1_RC, base-type=uint8, implementation-data-type=uint8, transfer-property=PENDING
          signal CAN1_ESC_Active: start 189, 1 bit, big-endian, i-signal-type=PRIMITIVE, init-value=constant-reference=Init_CAN1_ESC_Active, base-type=uint8, implementation-data-type=uint8, transfer-property=PENDING
          signal CAN1_ESC_BeepReq: start 150, 1 bit, big-endian, i-signal-type=PRIMITIVE, init-value=constant-reference=Init_CAN1_ESC_BeepReq, base-type=uint8, implementation-data-type=uint8, transfer-property=PENDING
          signal CAN1_ESC_EstVehSpd: start 203, 12 bit, big-endian, i-signal-type=PRIMITIVE, init-value=constant-reference=Init_CAN1_ESC_EstVehSpd, base-type=uint16, implementation-data-type=uint16, transfer-property=PENDING
          signal CAN1_ESC_EstVehSpd_V: start 204, 1 bit, big-endian, i-signal-type=PRIMITIVE, init-value=constant-reference=Init_CAN1_ESC_EstVehSpd_V, base-type=uint8, implementation-data-type=uint8, transfer-property=PENDING
          signal CAN1_ESC_Failed: start 169, 1 bit, big-endian, i-signal-type=PRIMITIVE, init-value=constant-reference=Init_CAN1_ESC_Failed, base-type=uint8, implementation-data-type=uint8, transfer-property=PENDING
          signal CAN1_ESC_OFF_Status: start 149, 2 bit, big-endian, i-signal-type=PRIMITIVE, init-value=constant-reference=Init_CAN1_ESC_OFF_Status, base-type=uint8, implementation-data-type=uint8, transfer-property=PENDING
          signal CAN1_ESC_Off_lmpSta: start 207, 1 bit, big-endian, i-signal-type=PRIMITIVE, init-value=constant-reference=Init_CAN1_ESC_Off_lmpSta, base-type=uint8, implementation-data-type=uint8, transfer-property=PENDING
          signal CAN1_ESC_TSA_Active: start 223, 1 bit, big-endian, i-signal-type=PRIMITIVE, init-value=constant-reference=Init_CAN1_ESC_TSA_Active, base-type=uint8, implementation-data-type=uint8, transfer-property=PENDING
          signal CAN1_ESC_WnlmpSta: start 185, 2 bit, big-endian, i-signal-type=PRIMITIVE, init-value=constant-reference=Init_CAN1_ESC_WnlmpSta, base-type=uint8, implementation-data-type=uint8, transfer-property=PENDING
          signal CAN1_ESS_Active: start 180, 1 bit, big-endian, i-signal-type=PRIMITIVE, init-value=constant-reference=Init_CAN1_ESS_Active, base-type=uint8, implementation-data-type=uint8, transfer-property=PENDING
          signal CAN1_Fr_PTCS_Active: start 27, 1 bit, big-endian, i-signal-type=PRIMITIVE, init-value=constant-reference=Init_CAN1_Fr_PTCS_Active, base-type=uint8, implementation-data-type=uint8, transfer-property=PENDING
          signal CAN1_FrntAxlTrqReq_Drv: start 39, 16 bit, big-endian, i-signal-type=PRIMITIVE, init-value=constant-reference=Init_CAN1_FrntAxlTrqReq_Drv, base-type=uint16, implementation-data-type=uint16, transfer-property=PENDING
          signal CAN1_GRADE: start 199, 8 bit, big-endian, i-signal-type=PRIMITIVE, init-value=constant-reference=Init_CAN1_GRADE, base-type=uint8, implementation-data-type=uint8, transfer-property=PENDING
          signal CAN1_HBB_Active: start 190, 1 bit, big-endian, i-signal-type=PRIMITIVE, init-value=constant-reference=Init_CAN1_HBB_Active, base-type=uint8, implementation-data-type=uint8, transfer-property=PENDING
          signal CAN1_HBB_Failed: start 170, 1 bit, big-endian, i-signal-type=PRIMITIVE, init-value=constant-reference=Init_CAN1_HBB_Failed, base-type=uint8, implementation-data-type=uint8, transfer-property=PENDING
          signal CAN1_HDD_Active: start 181, 1 bit, big-endian, i-signal-type=PRIMITIVE, init-value=constant-reference=Init_CAN1_HDD_Active, base-type=uint8, implementation-data-type=uint8, transfer-property=PENDING
          signal CAN1_HDD_Failed: start 174, 1 bit, big-endian, i-signal-type=PRIMITIVE, init-value=constant-reference=Init_CAN1_HDD_Failed, base-type=uint8, implementation-data-type=uint8, transfer-property=PENDING
          signal CAN1_HSA_Active: start 176, 1 bit, big-endian, i-signal-type=PRIMITIVE, init-value=constant-reference=Init_CAN1_HSA_Active, base-type=uint8, implementation-data-type=uint8, transfer-property=PENDING
          signal CAN1_HSA_Failed: start 172, 1 bit, big-endian, i-signal-type=PRIMITIVE, init-value=constant-reference=Init_CAN1_HSA_Failed, base-type=uint8, implementation-data-type=uint8, transfer-property=PENDING
          signal CAN1_LF_PulseCount: start 95, 8 bit, big-endian, i-signal-type=PRIMITIVE, init-value=constant-reference=Init_CAN1_LF_PulseCount, base-type=uint8, implementation-data-type=uint8, transfer-property=PENDING
          signal CAN1_LF_PulseCount_V: start 82, 1 bit, big-endian, i-signal-type=PRIMITIVE, init-value=constant-reference=Init_CAN1_LF_PulseCount_V, base-type=uint8, implementation-data-type=uint8, transfer-property=PENDING
          signal CAN1_LF_RawWhlSpeed: start 103, 12 bit, big-endian, i-signal-type=PRIMITIVE, init-value=constant-reference=Init_CAN1_LF_RawWhlSpeed, base-type=uint16, implementation-data-type=uint16, transfer-property=PENDING
          signal CAN1_LF_RawWhlSpeed_V: start 106, 1 bit, big-endian, i-signal-type=PRIMITIVE, init-value=constant-reference=Init_CAN1_LF_RawWhlSpeed_V, base-type=uint8, implementation-data-type=uint8, transfer-property=PENDING
          signal CAN1_LF_WhlRotDir: start 81, 2 bit, big-endian, i-signal-type=PRIMITIVE, init-value=constant-reference=Init_CAN1_LF_WhlRotDir, base-type=uint8, implementation-data-type=uint8, transfer-property=PENDING
          signal CAN1_LR_PulseCount: start 143, 8 bit, big-endian, i-signal-type=PRIMITIVE, init-value=constant-reference=Init_CAN1_LR_PulseCount, base-type=uint8, implementation-data-type=uint8, transfer-property=PENDING
          signal CAN1_LR_PulseCount_V: start 127, 1 bit, big-endian, i-signal-type=PRIMITIVE, init-value=constant-reference=Init_CAN1_LR_PulseCount_V, base-type=uint8, implementation-data-type=uint8, transfer-property=PENDING
          signal CAN1_LR_RawWhlSpeed: start 147, 12 bit, big-endian, i-signal-type=PRIMITIVE, init-value=constant-reference=Init_CAN1_LR_RawWhlSpeed, base-type=uint16, implementation-data-type=uint16, transfer-property=PENDING
          signal CAN1_LR_RawWhlSpeed_V: start 151, 1 bit, big-endian, i-signal-type=PRIMITIVE, init-value=constant-reference=Init_CAN1_LR_RawWhlSpeed_V, base-type=uint8, implementation-data-type=uint8, transfer-property=PENDING
          signal CAN1_LR_WhlRotDir: start 125, 2 bit, big-endian, i-signal-type=PRIMITIVE, init-value=constant-reference=Init_CAN1_LR_WhlRotDir, base-type=uint8, implementation-data-type=uint8, transfer-property=PENDING
          signal CAN1_PBA_Active: start 191, 1 bit, big-endian, i-signal-type=PRIMITIVE, init-value=constant-reference=Init_CAN1_PBA_Active, base-type=uint8, implementation-data-type=uint8, transfer-property=PENDING
          signal CAN1_PBA_Failed: start 171, 1 bit, big-endian, i-signal-type=PRIMITIVE, init-value=constant-reference=Init_CAN1_PBA_Failed, base-type=uint8, implementation-data-type=uint8, transfer-property=PENDING
          signal CAN1_RF_PulseCount: start 71, 8 bit, big-endian, i-signal-type=PRIMITIVE, init-value=constant-reference=Init_CAN1_RF_PulseCount, base-type=uint8, implementation-data-type=uint8, transfer-property=PENDING
          signal CAN1_RF_PulseCount_V: start 26, 1 bit, big-endian, i-signal-type=PRIMITIVE, init-value=constant-reference=Init_CAN1_RF_PulseCount_V, base-type=uint8, implementation-data-type=uint8, transfer-property=PENDING
          signal CAN1_RF_RawWhlSpeed: start 79, 12 bit, big-endian, i-signal-type=PRIMITIVE, init-value=constant-reference=Init_CAN1_RF_RawWhlSpeed, base-type=uint16, implementation-data-type=uint16, transfer-property=PENDING
          signal CAN1_RF_RawWhlSpeed_V: start 83, 1 bit, big-endian, i-signal-type=PRIMITIVE, init-value=constant-reference=Init_CAN1_RF_RawWhlSpeed_V, base-type=uint8, implementation-data-type=uint8, transfer-property=PENDING
          signal CAN1_RF_WhlRotDir: start 25, 2 bit, big-endian, i-signal-type=PRIMITIVE, init-value=constant-reference=Init_CAN1_RF_WhlRotDir, base-type=uint8, implementation-data-type=uint8, transfer-property=PENDING
          signal CAN1_RR_PulseCount: start 119, 8 bit, big-endian, i-signal-type=PRIMITIVE, init-value=constant-reference=Init_CAN1_RR_PulseCount, base-type=uint8, implementation-data-type=uint8, transfer-property=PENDING
          signal CAN1_RR_PulseCount_V: start 107, 1 bit, big-endian, i-signal-type=PRIMITIVE, init-value=constant-reference=Init_CAN1_RR_PulseCount_V, base-type=uint8, implementation-data-type=uint8, transfer-property=PENDING
          signal CAN1_RR_RawWhlSpeed: start 123, 12 bit, big-endian, i-signal-type=PRIMITIVE, init-value=constant-reference=Init_CAN1_RR_RawWhlSpeed, base-type=uint16, implementation-data-type=uint16, transfer-property=PENDING
          signal CAN1_RR_RawWhlSpeed_V: start 126, 1 bit, big-endian, i-signal-type=PRIMITIVE, init-value=constant-reference=Init_CAN1_RR_RawWhlSpeed_V, base-type=uint8, implementation-data-type=uint8, transfer-property=PENDING
          signal CAN1_RR_WhlRotDir: start 105, 2 bit, big-endian, i-signal-type=PRIMITIVE, init-value=constant-reference=Init_CAN1_RR_WhlRotDir, base-type=uint8, implementation-data-type=uint8, transfer-property=PENDING
          signal CAN1_RearAxlTrqReq_Drv: start 55, 16 bit, big-endian, i-signal-type=PRIMITIVE, init-value=constant-reference=Init_CAN1_RearAxlTrqReq_Drv, base-type=uint16, implementation-data-type=uint16, transfer-property=PENDING
          signal CAN1_Red_WnlmpSta: start 205, 1 bit, big-endian, i-signal-type=PRIMITIVE, init-value=constant-reference=Init_CAN1_Red_WnlmpSta, base-type=uint8, implementation-data-type=uint8, transfer-property=PENDING
          signal CAN1_Rr_PTCS_Active: start 175, 1 bit, big-endian, i-signal-type=PRIMITIVE, init-value=constant-reference=Init_CAN1_Rr_PTCS_Active, base-type=uint8, implementation-data-type=uint8, transfer-property=PENDING
          signal CAN1_SystemVoltage: start 167, 8 bit, big-endian, i-signal-type=PRIMITIVE, init-value=constant-reference=Init_CAN1_SystemVoltage, base-type=uint8, implementation-data-type=uint8, transfer-property=PENDING
          signal CAN1_TCS_Active: start 188, 1 bit, big-endian, i-signal-type=PRIMITIVE, init-value=constant-reference=Init_CAN1_TCS_Active, base-type=uint8, implementation-data-type=uint8, transfer-property=PENDING
          signal CAN1_TCS_Failed: start 168, 1 bit, big-endian, i-signal-type=PRIMITIVE, init-value=constant-reference=Init_CAN1_TCS_Failed, base-type=uint8, implementation-data-type=uint8, transfer-property=PENDING
          signal CAN1_VehSpeed: start 23, 12 bit, big-endian, i-signal-type=PRIMITIVE, init-value=constant-reference=Init_CAN1_VehSpeed, base-type=uint16, implementation-data-type=uint16, transfer-property=PENDING
      frame CAN1_ESC5: id 0x1A5, frame-length=20, can-addressing-mode=STANDARD, can-fd-frame-support=true, can-frame-rx-behavior=CAN-FD, can-frame-tx-behavior=CAN-FD
        pdu CAN1_ESC5: length=20, minimum-delay=0.0, transmission-mode-true-timing=cyclic-timing=time-period=0.01, unused-bit-pattern=0
          mapping CAN1_SG_ESC5: i-signal-group=CAN1_SG_ESC5, start-position=0, transfer-property=PENDING
          signal CAN1_ACCAvail: start 17, 1 bit, big-endian, i-signal-type=PRIMITIVE, init-value=constant-reference=Init_CAN1_ACCAvail, base-type=uint8, implementation-data-type=uint8, transfer-property=PENDING
          signal CAN1_AEBAvail: start 75, 1 bit, big-endian, i-signal-type=PRIMITIVE, init-value=constant-reference=Init_CAN1_AEBAvail, base-type=uint8, implementation-data-type=uint8, transfer-property=PENDING
          signal CAN1_ActBrkLamp_Sta: start 74, 1 bit, big-endian, i-signal-type=PRIMITIVE, init-value=constant-reference=Init_CAN1_ActBrkLamp_Sta, base-type=uint8, implementation-data-type=uint8, transfer-property=PENDING
          signal CAN1_BrkDiscTempSta: start 16, 1 bit, big-endian, i-signal-type=PRIMITIVE, init-value=constant-reference=Init_CAN1_BrkDiscTempSta, base-type=uint8, implementation-data-type=uint8, transfer-property=PENDING
          signal CAN1_BrkPedalPos: start 103, 8 bit, big-endian, i-signal-type=PRIMITIVE, init-value=constant-reference=Init_CAN1_BrkPedalPos, base-type=uint8, implementation-data-type=uint8, transfer-property=PENDING
          signal CAN1_BrkPedalPos_Sta: start 76, 1 bit, big-endian, i-signal-type=PRIMITIVE, init-value=constant-reference=Init_CAN1_BrkPedalPos_Sta, base-type=uint8, implementation-data-type=uint8, transfer-property=PENDING
          signal CAN1_BrkSw_Sta: start 22, 1 bit, big-endian, i-signal-type=PRIMITIVE, init-value=constant-reference=Init_CAN1_BrkSw_Sta, base-type=uint8, implementation-data-type=uint8, transfer-property=PENDING
          signal CAN1_BrkSw_V: start 23, 1 bit, big-endian, i-signal-type=PRIMITIVE, init-value=constant-reference=Init_CAN1_BrkSw_V, base-type=uint8, implementation-data-type=uint8, transfer-property=PENDING
          signal CAN1_DecErrSta: start 73, 1 bit, big-endian, i-signal-type=PRIMITIVE, init-value=constant-reference=Init_CAN1_DecErrSta, base-type=uint8, implementation-data-type=uint8, transfer-property=PENDING
          signal CAN1_ESC5_CS: start 7, 8 bit, big-endian, i-signal-type=PRIMITIVE, init-value=constant-reference=Init_CAN1_ESC5_CS, base-type=uint8, implementation-data-type=uint8, transfer-property=PENDING
          signal CAN1_ESC5_RC: start 11, 4 bit, big-endian, i-signal-type=PRIMITIVE, init-value=constant-reference=Init_CAN1_ESC5_RC, base-type=uint8, implementation-data-type=uint8, transfer-property=PENDING
          signal CAN1_ESC_ADAS_Sta: start 30, 3 bit, big-endian, i-signal-type=PRIMITIVE, init-value=constant-reference=Init_CAN1_ESC_ADAS_Sta, base-type=uint8, implementation-data-type=uint8, transfer-property=PENDING
          signal CAN1_ESC_APS_Sta: start 79, 3 bit, big-endian, i-signal-type=PRIMITIVE, init-value=constant-reference=Init_CAN1_ESC_APS_Sta, base-type=uint8, implementation-data-type=uint8, transfer-property=PENDING
          signal CAN1_ESC_DriverBrkOverride: start 31, 1 bit, big-endian, i-signal-type=PRIMITIVE, init-value=constant-reference=Init_CAN1_ESC_DriverBrkOverride, base-type=uint8, implementation-data-type=uint8, transfer-property=PENDING
          signal CAN1_ESC_Standstill: start 72, 1 bit, big-endian, i-signal-type=PRIMITIVE, init-value=constant-reference=Init_CAN1_ESC_Standstill, base-type=uint8, implementation-data-type=uint8, transfer-property=PENDING
          signal CAN1_Fr_RBC_Active: start 88, 1 bit, big-endian, i-signal-type=PRIMITIVE, init-value=constant-reference=Init_CAN1_Fr_RBC_Active, base-type=uint8, implementation-data-type=uint8, transfer-property=PENDING
          signal CAN1_FrntAxlTrqReq_Brk: start 127, 16 bit, big-endian, i-signal-type=PRIMITIVE, init-value=constant-reference=Init_CAN1_FrntAxlTrqReq_Brk, base-type=uint16, implementation-data-type=uint16, transfer-property=PENDING
          signal CAN1_LatAccel: start 55, 8 bit, big-endian, i-signal-type=PRIMITIVE, init-value=constant-reference=Init_CAN1_LatAccel, base-type=uint8, implementation-data-type=uint8, transfer-property=PENDING
          signal CAN1_LatAccel_V: start 19, 1 bit, big-endian, i-signal-type=PRIMITIVE, init-value=constant-reference=Init_CAN1_LatAccel_V, base-type=uint8, implementation-data-type=uint8, transfer-property=PENDING
          signal CAN1_LongAccel: start 47, 8 bit, big-endian, i-signal-type=PRIMITIVE, init-value=constant-reference=Init_CAN1_LongAccel, base-type=uint8, implementation-data-type=uint8, transfer-property=PENDING
          signal CAN1_LongAccel_V: start 20, 1 bit, big-endian, i-signal-type=PRIMITIVE, init-value=constant-reference=Init_CAN1_LongAccel_V, base-type=uint8, implementation-data-type=uint8, transfer-property=PENDING
          signal CAN1_MCPressure: start 27, 12 bit, big-endian, i-signal-type=PRIMITIVE, init-value=constant-reference=Init_CAN1_MCPressure, base-type=uint16, implementation-data-type=uint16, transfer-property=PENDING
          signal CAN1_MCPressure_V: start 21, 1 bit, big-endian, i-signal-type=PRIMITIVE, init-value=constant-reference=Init_CAN1_MCPressure_V, base-type=uint8, implementation-data-type=uint8, transfer-property=PENDING
          signal CAN1_Meter_Ind_VehSpeed: start 87, 12 bit, big-endian, i-signal-type=PRIMITIVE, init-value=constant-reference=Init_CAN1_Meter_Ind_VehSpeed, base-type=uint16, implementation-data-type=uint16, transfer-property=PENDING
          signal CAN1_RDC_Active: start 91, 2 bit, big-endian, i-signal-type=PRIMITIVE, init-value=constant-reference=Init_CAN1_RDC_Active, base-type=uint8, implementation-data-type=uint8, transfer-property=PENDING
          signal CAN1_RearAxlTrqReq_Brk: start 111, 16 bit, big-endian, i-signal-type=PRIMITIVE, init-value=constant-reference=Init_CAN1_RearAxlTrqReq_Brk, base-type=uint16, implementation-data-type=uint16, transfer-property=PENDING
          signal CAN1_Rr_RBC_Active: start 89, 1 bit, big-endian, i-signal-type=PRIMITIVE, init-value=constant-reference=Init_CAN1_Rr_RBC_Active, base-type=uint8, implementation-data-type=uint8, transfer-property=PENDING
          signal CAN1_YawRate: start 63, 16 bit, big-endian, i-signal-type=PRIMITIVE, init-value=constant-reference=Init_CAN1_YawRate, base-type=uint16, implementation-data-type=uint16, transfer-property=PENDING
          signal CAN1_YawRate_V: start 18, 1 bit, big-endian, i-signal-type=PRIMITIVE, init-value=constant-reference=Init_CAN1_YawRate_V, base-type=uint8, implementation-data-type=uint8, transfer-property=PENDING
      frame CAN1_FD1_APS2: id 0x210, frame-length=32, can-addressing-mode=STANDARD, can-fd-frame-support=true, can-frame-rx-behavior=CAN-FD, can-frame-tx-behavior=CAN-FD
        pdu CAN1_FD1_APS2: length=32, minimum-delay=0.0, transmission-mode-true-timing=cyclic-timing=time-period=0.02, unused-bit-pattern=0
          mapping CAN1_SG_FD1_APS2: i-signal-group=CAN1_SG_FD1_APS2, start-position=0, transfer-property=PENDING
          signal CAN1_APS_D_FLL: start 49, 10 bit, big-endian, i-signal-type=PRIMITIVE, init-value=constant-reference=Init_CAN1_APS_D_FLL, base-type=uint16, implementation-data-type=uint16, transfer-property=PENDING
          signal CAN1_APS_D_FLR: start 65, 10 bit, big-endian, i-signal-type=PRIMITIVE, init-value=constant-reference=Init_CAN1_APS_D_FLR, base-type=uint16, implementation-data-type=uint16, transfer-property=PENDING
          signal CAN1_APS_D_RLL: start 81, 10 bit, big-endian, i-signal-type=PRIMITIVE, init-value=constant-reference=Init_CAN1_APS_D_RLL, base-type=uint16, implementation-data-type=uint16, transfer-property=PENDING
          signal CAN1_APS_D_RLR: start 97, 10 bit, big-endian, i-signal-type=PRIMITIVE, init-value=constant-reference=Init_CAN1_APS_D_RLR, base-type=uint16, implementation-data-type=uint16, transfer-property=PENDING
          signal CAN1_APS_ExitCondition: start 151, 8 bit, big-endian, i-signal-type=PRIMITIVE, init-value=constant-reference=Init_CAN1_APS_ExitCondition, base-type=uint8, implementation-data-type=uint8, transfer-property=PENDING
          signal CAN1_APS_HW_Ver: start 159, 8 bit, big-endian, i-signal-type=PRIMITIVE, init-value=constant-reference=Init_CAN1_APS_HW_Ver, base-type=uint8, implementation-data-type=uint8, transfer-property=PENDING
          signal CAN1_APS_Progress_PCT: start 215, 8 bit, big-endian, i-signal-type=PRIMITIVE, init-value=constant-reference=Init_CAN1_APS_Progress_PCT, base-type=uint8, implementation-data-type=uint8, transfer-property=PENDING
          signal CAN1_APS_RQ_Display: start 207, 8 bit, big-endian, i-signal-type=PRIMITIVE, init-value=constant-reference=Init_CAN1_APS_RQ_Display, base-type=uint8, implementation-data-type=uint8, transfer-property=PENDING
          signal CAN1_APS_SW_Ver: start 167, 8 bit, big-endian, i-signal-type=PRIMITIVE, init-value=constant-reference=Init_CAN1_APS_SW_Ver, base-type=uint8, implementation-data-type=uint8, transfer-property=PENDING
          signal CAN1_PAS_A_FCL: start 219, 4 bit, big-endian, i-signal-type=PRIMITIVE, init-value=constant-reference=Init_CAN1_PAS_A_FCL, base-type=uint8, implementation-data-type=uint8, transfer-property=PENDING
          signal CAN1_PAS_A_FCR: start 23, 4 bit, big-endian, i-signal-type=PRIMITIVE, init-value=constant-reference=Init_CAN1_PAS_A_FCR, base-type=uint8, implementation-data-type=uint8, transfer-property=PENDING
          signal CAN1_PAS_A_FML: start 19, 4 bit, big-endian, i-signal-type=PRIMITIVE, init-value=constant-reference=Init_CAN1_PAS_A_FML, base-type=uint8, implementation-data-type=uint8, transfer-property=PENDING
          signal CAN1_PAS_A_FMR: start 31, 4 bit, big-endian, i-signal-type=PRIMITIVE, init-value=constant-reference=Init_CAN1_PAS_A_FMR, base-type=uint8, implementation-data-type=uint8, transfer-property=PENDING
          signal CAN1_PAS_A_RCL: start 27, 4 bit, big-endian, i-signal-type=PRIMITIVE, init-value=constant-reference=Init_CAN1_PAS_A_RCL, base-type=uint8, implementation-data-type=uint8, transfer-property=PENDING
          signal CAN1_PAS_A_RCR: start 39, 4 bit, big-endian, i-signal-type=PRIMITIVE, init-value=constant-reference=Init_CAN1_PAS_A_RCR, base-type=uint8, implementation-data-type=uint8, transfer-property=PENDING
          signal CAN1_PAS_A_RML: start 35, 4 bit, big-endian, i-signal-type=PRIMITIVE, init-value=constant-reference=Init_CAN1_PAS_A_RML, base-type=uint8, implementation-data-type=uint8, transfer-property=PENDING
          signal CAN1_PAS_A_RMR: start 47, 4 bit, big-endian, i-signal-type=PRIMITIVE, init-value=constant-reference=Init_CAN1_PAS_A_RMR, base-type=uint8, implementation-data-type=uint8, transfer-property=PENDING
          signal CAN1_PAS_Chime: start 223, 4 bit, big-endian, i-signal-type=PRIMITIVE, init-value=constant-reference=Init_CAN1_PAS_Chime, base-type=uint8, implementation-data-type=uint8, transfer-property=PENDING
          signal CAN1_PAS_D_FCL: start 119, 8 bit, big-endian, i-signal-type=PRIMITIVE, init-value=constant-reference=Init_CAN1_PAS_D_FCL, base-type=uint8, implementation-data-type=uint8, transfer-property=PENDING
          signal CAN1_PAS_D_FCR: start 127, 8 bit, big-endian, i-signal-type=PRIMITIVE, init-value=constant-reference=Init_CAN1_PAS_D_FCR, base-type=uint8, implementation-data-type=uint8, transfer-property=PENDING
          signal CAN1_PAS_D_FML: start 135, 8 bit, big-endian, i-signal-type=PRIMITIVE, init-value=constant-reference=Init_CAN1_PAS_D_FML, base-type=uint8, implementation-data-type=uint8, transfer-property=PENDING
          signal CAN1_PAS_D_FMR: start 143, 8 bit, big-endian, i-signal-type=PRIMITIVE, init-value=constant-reference=Init_CAN1_PAS_D_FMR, base-type=uint8, implementation-data-type=uint8, transfer-property=PENDING
          signal CAN1_PAS_D_RCL: start 175, 8 bit, big-endian, i-signal-type=PRIMITIVE, init-value=constant-reference=Init_CAN1_PAS_D_RCL, base-type=uint8, implementation-data-type=uint8, transfer-property=PENDING
          signal CAN1_PAS_D_RCR: start 183, 8 bit, big-endian, i-signal-type=PRIMITIVE, init-value=constant-reference=Init_CAN1_PAS_D_RCR, base-type=uint8, implementation-data-type=uint8, transfer-property=PENDING
          signal CAN1_PAS_D_RML: start 191, 8 bit, big-endian, i-signal-type=PRIMITIVE, init-value=constant-reference=Init_CAN1_PAS_D_RML, base-type=uint8, implementation-data-type=uint8, transfer-property=PENDING
          signal CAN1_PAS_D_RMR: start 199, 8 bit, big-endian, i-signal-type=PRIMITIVE, init-value=constant-reference=Init_CAN1_PAS_D_RMR, base-type=uint8, implementation-data-type=uint8, transfer-property=PENDING
          signal CAN1_PAS_Mod_Operation: start 11, 2 bit, big-endian, i-signal-type=PRIMITIVE, init-value=constant-reference=Init_CAN1_PAS_Mod_Operation, base-type=uint8, implementation-data-type=uint8, transfer-property=PENDING
          signal CAN1_PAS_SNSR_Layout: start 43, 4 bit, big-endian, i-signal-type=PRIMITIVE, init-value=constant-reference=Init_CAN1_PAS_SNSR_Layout, base-type=uint8, implementation-data-type=uint8, transfer-property=PENDING
          signal CAN1_PAS_Sta_F_Sys: start 9, 1 bit, big-endian, i-signal-type=PRIMITIVE, init-value=constant-reference=Init_CAN1_PAS_Sta_F_Sys, base-type=uint8, implementation-data-type=uint8, transfer-property=PENDING
          signal CAN1_USS_Sta_FCL: start 7, 1 bit, big-endian, i-signal-type=PRIMITIVE, init-value=constant-reference=Init_CAN1_USS_Sta_FCL, base-type=uint8, implementation-data-type=uint8, transfer-property=PENDING
          signal CAN1_USS_Sta_FCR: start 6, 1 bit, big-endian, i-signal-type=PRIMITIVE, init-value=constant-reference=Init_CAN1_USS_Sta_FCR, base-type=uint8, implementation-data-type=uint8, transfer-property=PENDING
          signal CAN1_USS_Sta_FLL: start 5, 1 bit, big-endian, i-signal-type=PRIMITIVE, init-value=constant-reference=Init_CAN1_USS_Sta_FLL, base-type=uint8, implementation-data-type=uint8, transfer-property=PENDING
          signal CAN1_USS_Sta_FLR: start 4, 1 bit, big-endian, i-signal-type=PRIMITIVE, init-value=constant-reference=Init_CAN1_USS_Sta_FLR, base-type=uint8, implementation-data-type=uint8, transfer-property=PENDING
          signal CAN1_USS_Sta_FML: start 3, 1 bit, big-endian, i-signal-type=PRIMITIVE, init-value=constant-reference=Init_CAN1_USS_Sta_FML, base-type=uint8, implementation-data-type=uint8, transfer-property=PENDING
          signal CAN1_USS_Sta_FMR: start 2, 1 bit, big-endian, i-signal-type=PRIMITIVE, init-value=constant-reference=Init_CAN1_USS_Sta_FMR, base-type=uint8, implementation-data-type=uint8, transfer-property=PENDING
          signal CAN1_USS_Sta_RCL: start 1, 1 bit, big-endian, i-signal-type=PRIMITIVE, init-value=constant-reference=Init_CAN1_USS_Sta_RCL, base-type=uint8, implementation-data-type=uint8, transfer-property=PENDING
          signal CAN1_USS_Sta_RCR: start 0, 1 bit, big-endian, i-signal-type=PRIMITIVE, init-value=constant-reference=Init_CAN1_USS_Sta_RCR, base-type=uint8, implementation-data-type=uint8, transfer-property=PENDING
          signal CAN1_USS_Sta_RLL: start 15, 1 bit, big-endian, i-signal-type=PRIMITIVE, init-value=constant-reference=Init_CAN1_USS_Sta_RLL, base-type=uint8, implementation-data-type=uint8, transfer-property=PENDING
          signal CAN1_USS_Sta_RLR: start 14, 1 bit, big-endian, i-signal-type=PRIMITIVE, init-value=constant-reference=Init_CAN1_USS_Sta_RLR, base-type=uint8, implementation-data-type=uint8, transfer-property=PENDING
          signal CAN1_USS_Sta_RML: start 13, 1 bit, big-endian, i-signal-type=PRIMITIVE, init-value=constant-reference=Init_CAN1_USS_Sta_RML, base-type=uint8, implementation-data-type=uint8, transfer-property=PENDING
          signal CAN1_USS_Sta_RMR: start 12, 1 bit, big-endian, i-signal-type=PRIMITIVE, init-value=constant-reference=Init_CAN1_USS_Sta_RMR, base-type=uint8, implementation-data-type=uint8, transfer-property=PENDING
      frame CAN1_FD1_APS3: id 0x238, frame-length=16, can-addressing-mode=STANDARD, can-fd-frame-support=true, can-frame-rx-behavior=CAN-FD, can-frame-tx-behavior=CAN-FD
        pdu CAN1_FD1_APS3: length=16, minimum-delay=0.0, transmission-mode-true-timing=cyclic-timing=time-period=0.01, unused-bit-pattern=0
          mapping CAN1_SG_FD1_APS3: i-signal-group=CAN1_SG_FD1_APS3, start-position=0, transfer-property=PENDING
          signal CAN1_APS3_LifeCount: start 11, 4 bit, big-endian, i-signal-type=PRIMITIVE, init-value=constant-reference=Init_CAN1_APS3_LifeCount, base-type=uint8, implementation-data-type=uint8, transfer-property=PENDING
          signal CAN1_APS3_checksum: start 7, 8 bit, big-endian, i-signal-type=PRIMITIVE, init-value=constant-reference=Init_CAN1_APS3_checksum, base-type=uint8, implementation-data-type=uint8, transfer-property=PENDING
          signal CAN1_APSOpenPTG: start 16, 1 bit, big-endian, i-signal-type=PRIMITIVE, init-value=constant-reference=Init_CAN1_APSOpenPTG, base-type=uint8, implementation-data-type=uint8, transfer-property=PENDING
          signal CAN1_APS_DecReq: start 31, 8 bit, big-endian, i-signal-type=PRIMITIVE, init-value=constant-reference=Init_CAN1_APS_DecReq, base-type=uint8, implementation-data-type=uint8, transfer-property=PENDING
          signal CAN1_APS_DecReq_A: start 23, 1 bit, big-endian, i-signal-type=PRIMITIVE, init-value=constant-reference=Init_CAN1_APS_DecReq_A, base-type=uint8, implementation-data-type=uint8, transfer-property=PENDING
          signal CAN1_APS_Req: start 22, 3 bit, big-endian, i-signal-type=PRIMITIVE, init-value=constant-reference=Init_CAN1_APS_Req, base-type=uint8, implementation-data-type=uint8, transfer-property=PENDING
          signal CAN1_APS_Sta_System: start 50, 3 bit, big-endian, i-signal-type=PRIMITIVE, init-value=constant-reference=Init_CAN1_APS_Sta_System, base-type=uint8, implementation-data-type=uint8, transfer-property=PENDING
          signal CAN1_CAAS_Sta: start 19, 3 bit, big-endian, i-signal-type=PRIMITIVE, init-value=constant-reference=Init_CAN1_CAAS_Sta, base-type=uint8, implementation-data-type=uint8, transfer-property=PENDING
          signal CAN1_FDC_APS_Active_Sta: start 76, 1 bit, big-endian, i-signal-type=PRIMITIVE, init-value=constant-reference=Init_CAN1_FDC_APS_Active_Sta, base-type=uint8, implementation-data-type=uint8, transfer-property=PENDING
          signal CAN1_FDC_APS_CaasActive_Sta: start 57, 1 bit, big-endian, i-signal-type=PRIMITIVE, init-value=constant-reference=Init_CAN1_FDC_APS_CaasActive_Sta, base-type=uint8, implementation-data-type=uint8, transfer-property=PENDING
          signal CAN1_FDC_APS_CaasCtrlAvail_Sta: start 59, 1 bit, big-endian, i-signal-type=PRIMITIVE, init-value=constant-reference=Init_CAN1_FDC_APS_CaasCtrlAvail_Sta, base-type=uint8, implementation-data-type=uint8, transfer-property=PENDING
          signal CAN1_FDC_APS_CaasVMCReqA_Cmd: start 58, 1 bit, big-endian, i-signal-type=PRIMITIVE, init-value=constant-reference=Init_CAN1_FDC_APS_CaasVMCReqA_Cmd, base-type=uint8, implementation-data-type=uint8, transfer-property=PENDING
          signal CAN1_FDC_APS_CtrlAvail_Sta: start 63, 1 bit, big-endian, i-signal-type=PRIMITIVE, init-value=constant-reference=Init_CAN1_FDC_APS_CtrlAvail_Sta, base-type=uint8, implementation-data-type=uint8, transfer-property=PENDING
          signal CAN1_FDC_APS_ShftPosnReq_Cmd: start 62, 3 bit, big-endian, i-signal-type=PRIMITIVE, init-value=constant-reference=Init_CAN1_FDC_APS_ShftPosnReq_Cmd, base-type=uint8, implementation-data-type=uint8, transfer-property=PENDING
          signal CAN1_FDC_APS_SpeedReq_Cmd: start 75, 12 bit, big-endian, i-signal-type=PRIMITIVE, init-value=constant-reference=Init_CAN1_FDC_APS_SpeedReq_Cmd, base-type=uint16, implementation-data-type=uint16, transfer-property=PENDING
          signal CAN1_FDC_APS_VMCReqA_Cmd: start 77, 1 bit, big-endian, i-signal-type=PRIMITIVE, init-value=constant-reference=Init_CAN1_FDC_APS_VMCReqA_Cmd, base-type=uint8, implementation-data-type=uint8, transfer-property=PENDING
          signal CAN1_FDC_RAPS_BCMLamp_Cmd: start 66, 3 bit, big-endian, i-signal-type=PRIMITIVE, init-value=constant-reference=Init_CAN1_FDC_RAPS_BCMLamp_Cmd, base-type=uint8, implementation-data-type=uint8, transfer-property=PENDING
          signal CAN1_FDC_RAPS_BCMLockReq_Cmd: start 67, 1 bit, big-endian, i-signal-type=PRIMITIVE, init-value=constant-reference=Init_CAN1_FDC_RAPS_BCMLockReq_Cmd, base-type=uint8, implementation-data-type=uint8, transfer-property=PENDING
          signal CAN1_FDC_RAPS_ErrLv1_Flg: start 78, 1 bit, big-endian, i-signal-type=PRIMITIVE, init-value=constant-reference=Init_CAN1_FDC_RAPS_ErrLv1_Flg, base-type=uint8, implementation-data-type=uint8, transfer-property=PENDING
          signal CAN1_FDC_RAPS_PwrReqAvail_Sta: start 71, 1 bit, big-endian, i-signal-type=PRIMITIVE, init-value=constant-reference=Init_CAN1_FDC_RAPS_PwrReqAvail_Sta, base-type=uint8, implementation-data-type=uint8, transfer-property=PENDING
          signal CAN1_FDC_RAPS_PwrReq_Cmd: start 70, 3 bit, big-endian, i-signal-type=PRIMITIVE, init-value=constant-reference=Init_CAN1_FDC_RAPS_PwrReq_Cmd, base-type=uint8, implementation-data-type=uint8, transfer-property=PENDING
          signal CAN1_FDC_VCU_RAPSErrLv2_Flg: start 79, 1 bit, big-endian, i-signal-type=PRIMITIVE, init-value=constant-reference=Init_CAN1_FDC_VCU_RAPSErrLv2_Flg, base-type=uint8, implementation-data-type=uint8, transfer-property=PENDING
          signal CAN1_FDC_VCU_RAPSErrLv3_Flg: start 95, 1 bit, big-endian, i-signal-type=PRIMITIVE, init-value=constant-reference=Init_CAN1_FDC_VCU_RAPSErrLv3_Flg, base-type=uint8, implementation-data-type=uint8, transfer-property=PENDING
          signal CAN1_FDC_VMC_APS_Angle_Target: start 39, 16 bit, big-endian, i-signal-type=PRIMITIVE, init-value=constant-reference=Init_CAN1_FDC_VMC_APS_Angle_Target, base-type=uint16, implementation-data-type=uint16, transfer-property=PENDING
          signal CAN1_FDC_VMC_APS_Rq_EPS_Ctrl: start 56, 1 bit, big-endian, i-signal-type=PRIMITIVE, init-value=constant-reference=Init_CAN1_FDC_VMC_APS_Rq_EPS_Ctrl, base-type=uint8, implementation-data-type=uint8, transfer-property=PENDING
          signal CAN1_FDC_VMC_APS_V_Rq_EPS_Ctrl: start 51, 1 bit, big-endian, i-signal-type=PRIMITIVE, init-value=constant-reference=Init_CAN1_FDC_VMC_APS_V_Rq_EPS_Ctrl, base-type=uint8, implementation-data-type=uint8, transfer-property=PENDING
          signal CAN1_SPTGDet: start 55, 1 bit, big-endian, i-signal-type=PRIMITIVE, init-value=constant-reference=Init_CAN1_SPTGDet, base-type=uint8, implementation-data-type=uint8, transfer-property=PENDING
          signal CAN1_SPTG_Sta: start 54, 3 bit, big-endian, i-signal-type=PRIMITIVE, init-value=constant-reference=Init_CAN1_SPTG_Sta, base-type=uint8, implementation-data-type=uint8, transfer-property=PENDING
      frame CAN1_FD1_BCM1: id 0x216, frame-length=16, can-addressing-mode=STANDARD, can-fd-frame-support=true, can-frame-rx-behavior=CAN-FD, can-frame-tx-behavior=CAN-FD
        pdu CAN1_FD1_BCM1: length=16, minimum-delay=0.0, transmission-mode-true-timing={cyclic-timing=time-period=0.2, event-controlled-timing={number-of-repetitions=0, repetition-period=0}}, unused-bit-pattern=0
          mapping CAN1_SG_FD1_BCM1: i-signal-group=CAN1_SG_FD1_BCM1, start-position=0, transfer-property=TRIGGERED-ON-CHANGE
          signal CAN1_AllDoorSW: start 124, 1 bit, big-endian, i-signal-type=PRIMITIVE, init-value=constant-reference=Init_CAN1_AllDoorSW, base-type=uint8, implementation-data-type=uint8, transfer-property=TRIGGERED-ON-CHANGE
          signal CAN1_AntiTheftSeatFold: start 84, 1 bit, big-endian, i-signal-type=PRIMITIVE, init-value=constant-reference=Init_CAN1_AntiTheftSeatFold, base-type=uint8, implementation-data-type=uint8, transfer-property=TRIGGERED-ON-CHANGE
          signal CAN1_AntitheftSta: start 83, 2 bit, big-endian, i-signal-type=PRIMITIVE, init-value=constant-reference=Init_CAN1_AntitheftSta, base-type=uint8, implementation-data-type=uint8, transfer-property=TRIGGERED-ON-CHANGE
          signal CAN1_BCM_Buzzer_Req: start 64, 1 bit, big-endian, i-signal-type=PRIMITIVE, init-value=constant-reference=Init_CAN1_BCM_Buzzer_Req, base-type=uint8, implementation-data-type=uint8, transfer-property=TRIGGERED-ON-CHANGE
          signal CAN1_BCM_DoorLock_Sta: start 70, 1 bit, big-endian, i-signal-type=PRIMITIVE, init-value=constant-reference=Init_CAN1_BCM_DoorLock_Sta, base-type=uint8, implementation-data-type=uint8, transfer-property=TRIGGERED-ON-CHANGE
          signal CAN1_BrakeLamp: start 90, 1 bit, big-endian, i-signal-type=PRIMITIVE, init-value=constant-reference=Init_CAN1_BrakeLamp, base-type=uint8, implementation-data-type=uint8, transfer-property=TRIGGERED-ON-CHANGE
          signal CAN1_CTDCtrl: start 113, 2 bit, big-endian, i-signal-type=PRIMITIVE, init-value=constant-reference=Init_CAN1_CTDCtrl, base-type=uint8, implementation-data-type=uint8, transfer-property=TRIGGERED-ON-CHANGE
          signal CAN1_CTDLockSW: start 118, 1 bit, big-endian, i-signal-type=PRIMITIVE, init-value=constant-reference=Init_CAN1_CTDLockSW, base-type=uint8, implementation-data-type=uint8, transfer-property=TRIGGERED-ON-CHANGE
          signal CAN1_CTDUnlockSW: start 119, 1 bit, big-endian, i-signal-type=PRIMITIVE, init-value=constant-reference=Init_CAN1_CTDUnlockSW, base-type=uint8, implementation-data-type=uint8, transfer-property=TRIGGERED-ON-CHANGE
          signal CAN1_CrashDetd: start 85, 1 bit, big-endian, i-signal-type=PRIMITIVE, init-value=constant-reference=Init_CAN1_CrashDetd, base-type=uint8, implementation-data-type=uint8, transfer-property=TRIGGERED-ON-CHANGE
          signal CAN1_Dimmer: start 78, 7 bit, big-endian, i-signal-type=PRIMITIVE, init-value=constant-reference=Init_CAN1_Dimmer, base-type=uint8, implementation-data-type=uint8, transfer-property=TRIGGERED-ON-CHANGE
          signal CAN1_DimmerEN: start 69, 1 bit, big-endian, i-signal-type=PRIMITIVE, init-value=constant-reference=Init_CAN1_DimmerEN, base-type=uint8, implementation-data-type=uint8, transfer-property=TRIGGERED-ON-CHANGE
          signal CAN1_DoorLockIND: start 125, 1 bit, big-endian, i-signal-type=PRIMITIVE, init-value=constant-reference=Init_CAN1_DoorLockIND, base-type=uint8, implementation-data-type=uint8, transfer-property=TRIGGERED-ON-CHANGE
          signal CAN1_DrDoorSW: start 120, 1 bit, big-endian, i-signal-type=PRIMITIVE, init-value=constant-reference=Init_CAN1_DrDoorSW, base-type=uint8, implementation-data-type=uint8, transfer-property=TRIGGERED-ON-CHANGE
          signal CAN1_Fr_ChargingDoorCtrl: start 115, 2 bit, big-endian, i-signal-type=PRIMITIVE, init-value=constant-reference=Init_CAN1_Fr_ChargingDoorCtrl, base-type=uint8, implementation-data-type=uint8, transfer-property=TRIGGERED-ON-CHANGE
          signal CAN1_Fr_FogLamp: start 93, 1 bit, big-endian, i-signal-type=PRIMITIVE, init-value=constant-reference=Init_CAN1_Fr_FogLamp, base-type=uint8, implementation-data-type=uint8, transfer-property=TRIGGERED-ON-CHANGE
          signal CAN1_Fr_Wiper_H: start 110, 1 bit, big-endian, i-signal-type=PRIMITIVE, init-value=constant-reference=Init_CAN1_Fr_Wiper_H, base-type=uint8, implementation-data-type=uint8, transfer-property=TRIGGERED-ON-CHANGE
          signal CAN1_Fr_Wiper_L: start 111, 1 bit, big-endian, i-signal-type=PRIMITIVE, init-value=constant-reference=Init_CAN1_Fr_Wiper_L, base-type=uint8, implementation-data-type=uint8, transfer-property=TRIGGERED-ON-CHANGE
          signal CAN1_H_Beam: start 101, 1 bit, big-endian, i-signal-type=PRIMITIVE, init-value=constant-reference=Init_CAN1_H_Beam, base-type=uint8, implementation-data-type=uint8, transfer-property=TRIGGERED-ON-CHANGE
          signal CAN1_HazardSW: start 95, 1 bit, big-endian, i-signal-type=PRIMITIVE, init-value=constant-reference=Init_CAN1_HazardSW, base-type=uint8, implementation-data-type=uint8, transfer-property=TRIGGERED-ON-CHANGE
          signal CAN1_HoodSW: start 126, 1 bit, big-endian, i-signal-type=PRIMITIVE, init-value=constant-reference=Init_CAN1_HoodSW, base-type=uint8, implementation-data-type=uint8, transfer-property=TRIGGERED-ON-CHANGE
          signal CAN1_HornCtrl: start 71, 1 bit, big-endian, i-signal-type=PRIMITIVE, init-value=constant-reference=Init_CAN1_HornCtrl, base-type=uint8, implementation-data-type=uint8, transfer-property=TRIGGERED-ON-CHANGE
          signal CAN1_LBSD: start 91, 1 bit, big-endian, i-signal-type=PRIMITIVE, init-value=constant-reference=Init_CAN1_LBSD, base-type=uint8, implementation-data-type=uint8, transfer-property=TRIGGERED-ON-CHANGE
          signal CAN1_LDRL: start 103, 1 bit, big-endian, i-signal-type=PRIMITIVE, init-value=constant-reference=Init_CAN1_LDRL, base-type=uint8, implementation-data-type=uint8, transfer-property=TRIGGERED-ON-CHANGE
          signal CAN1_LTurnLP: start 80, 1 bit, big-endian, i-signal-type=PRIMITIVE, init-value=constant-reference=Init_CAN1_LTurnLP, base-type=uint8, implementation-data-type=uint8, transfer-property=TRIGGERED-ON-CHANGE
          signal CAN1_L_APM_WdwEnable: start 87, 1 bit, big-endian, i-signal-type=PRIMITIVE, init-value=constant-reference=Init_CAN1_L_APM_WdwEnable, base-type=uint8, implementation-data-type=uint8, transfer-property=TRIGGERED-ON-CHANGE
          signal CAN1_L_Beam: start 100, 1 bit, big-endian, i-signal-type=PRIMITIVE, init-value=constant-reference=Init_CAN1_L_Beam, base-type=uint8, implementation-data-type=uint8, transfer-property=TRIGGERED-ON-CHANGE
          signal CAN1_LockSetting: start 79, 1 bit, big-endian, i-signal-type=PRIMITIVE, init-value=constant-reference=Init_CAN1_LockSetting, base-type=uint8, implementation-data-type=uint8, transfer-property=TRIGGERED-ON-CHANGE
          signal CAN1_MirrorCtrl: start 109, 2 bit, big-endian, i-signal-type=PRIMITIVE, init-value=constant-reference=Init_CAN1_MirrorCtrl, base-type=uint8, implementation-data-type=uint8, transfer-property=TRIGGERED-ON-CHANGE
          signal CAN1_MirrorDefog: start 104, 1 bit, big-endian, i-signal-type=PRIMITIVE, init-value=constant-reference=Init_CAN1_MirrorDefog, base-type=uint8, implementation-data-type=uint8, transfer-property=TRIGGERED-ON-CHANGE
          signal CAN1_PosLamp: start 102, 1 bit, big-endian, i-signal-type=PRIMITIVE, init-value=constant-reference=Init_CAN1_PosLamp, base-type=uint8, implementation-data-type=uint8, transfer-property=TRIGGERED-ON-CHANGE
          signal CAN1_PsDoorSW: start 121, 1 bit, big-endian, i-signal-type=PRIMITIVE, init-value=constant-reference=Init_CAN1_PsDoorSW, base-type=uint8, implementation-data-type=uint8, transfer-property=TRIGGERED-ON-CHANGE
          signal CAN1_RBSD: start 92, 1 bit, big-endian, i-signal-type=PRIMITIVE, init-value=constant-reference=Init_CAN1_RBSD, base-type=uint8, implementation-data-type=uint8, transfer-property=TRIGGERED-ON-CHANGE
          signal CAN1_RDRL: start 88, 1 bit, big-endian, i-signal-type=PRIMITIVE, init-value=constant-reference=Init_CAN1_RDRL, base-type=uint8, implementation-data-type=uint8, transfer-property=TRIGGERED-ON-CHANGE
          signal CAN1_RLDoorSW: start 122, 1 bit, big-endian, i-signal-type=PRIMITIVE, init-value=constant-reference=Init_CAN1_RLDoorSW, base-type=uint8, implementation-data-type=uint8, transfer-property=TRIGGERED-ON-CHANGE
          signal CAN1_RRDoorSW: start 123, 1 bit, big-endian, i-signal-type=PRIMITIVE, init-value=constant-reference=Init_CAN1_RRDoorSW, base-type=uint8, implementation-data-type=uint8, transfer-property=TRIGGERED-ON-CHANGE
          signal CAN1_RTurnLP: start 81, 1 bit, big-endian, i-signal-type=PRIMITIVE, init-value=constant-reference=Init_CAN1_RTurnLP, base-type=uint8, implementation-data-type=uint8, transfer-property=TRIGGERED-ON-CHANGE
          signal CAN1_ReverseLamp: start 89, 1 bit, big-endian, i-signal-type=PRIMITIVE, init-value=constant-reference=Init_CAN1_ReverseLamp, base-type=uint8, implementation-data-type=uint8, transfer-property=TRIGGERED-ON-CHANGE
          signal CAN1_RoomLampH: start 68, 1 bit, big-endian, i-signal-type=PRIMITIVE, init-value=constant-reference=Init_CAN1_RoomLampH, base-type=uint8, implementation-data-type=uint8, transfer-property=TRIGGERED-ON-CHANGE
          signal CAN1_RoomLampL: start 67, 1 bit, big-endian, i-signal-type=PRIMITIVE, init-value=constant-reference=Init_CAN1_RoomLampL, base-type=uint8, implementation-data-type=uint8, transfer-property=TRIGGERED-ON-CHANGE
          signal CAN1_Rr_ChargingDoorCtrl: start 117, 2 bit, big-endian, i-signal-type=PRIMITIVE, init-value=constant-reference=Init_CAN1_Rr_ChargingDoorCtrl, base-type=uint8, implementation-data-type=uint8, transfer-property=TRIGGERED-ON-CHANGE
          signal CAN1_Rr_Defog: start 105, 1 bit, big-endian, i-signal-type=PRIMITIVE, init-value=constant-reference=Init_CAN1_Rr_Defog, base-type=uint8, implementation-data-type=uint8, transfer-property=TRIGGERED-ON-CHANGE
          signal CAN1_Rr_FogLamp: start 94, 1 bit, big-endian, i-signal-type=PRIMITIVE, init-value=constant-reference=Init_CAN1_Rr_FogLamp, base-type=uint8, implementation-data-type=uint8, transfer-property=TRIGGERED-ON-CHANGE
          signal CAN1_Rr_Wiper: start 96, 1 bit, big-endian, i-signal-type=PRIMITIVE, init-value=constant-reference=Init_CAN1_Rr_Wiper, base-type=uint8, implementation-data-type=uint8, transfer-property=TRIGGERED-ON-CHANGE
          signal CAN1_TailgateHDSW: start 107, 1 bit, big-endian, i-signal-type=PRIMITIVE, init-value=constant-reference=Init_CAN1_TailgateHDSW, base-type=uint8, implementation-data-type=uint8, transfer-property=TRIGGERED-ON-CHANGE
          signal CAN1_TailgateRemote: start 66, 2 bit, big-endian, i-signal-type=PRIMITIVE, init-value=constant-reference=Init_CAN1_TailgateRemote, base-type=uint8, implementation-data-type=uint8, transfer-property=TRIGGERED-ON-CHANGE
          signal CAN1_Tailgate_SW: start 127, 1 bit, big-endian, i-signal-type=PRIMITIVE, init-value=constant-reference=Init_CAN1_Tailgate_SW, base-type=uint8, implementation-data-type=uint8, transfer-property=TRIGGERED-ON-CHANGE
          signal CAN1_TrunkRel: start 106, 1 bit, big-endian, i-signal-type=PRIMITIVE, init-value=constant-reference=Init_CAN1_TrunkRel, base-type=uint8, implementation-data-type=uint8, transfer-property=TRIGGERED-ON-CHANGE
          signal CAN1_WasherCtrl: start 99, 2 bit, big-endian, i-signal-type=PRIMITIVE, init-value=constant-reference=Init_CAN1_WasherCtrl, base-type=uint8, implementation-data-type=uint8, transfer-property=TRIGGERED-ON-CHANGE
          signal CAN1_WiperFixMode: start 97, 1 bit, big-endian, i-signal-type=PRIMITIVE, init-value=constant-reference=Init_CAN1_WiperFixMode, base-type=uint8, implementation-data-type=uint8, transfer-property=TRIGGERED-ON-CHANGE
      frame CAN1_FD1_THCM1: id 0x182, frame-length=20, can-addressing-mode=STANDARD, can-fd-frame-support=true, can-frame-rx-behavior=CAN-FD, can-frame-tx-behavior=CAN-FD
        pdu CAN1_FD1_THCM1: length=20, minimum-delay=0.0, transmission-mode-true-timing=cyclic-timing=time-period=0.1, unused-bit-pattern=0
          mapping CAN1_SG_FD1_THCM1: i-signal-group=CAN1_SG_FD1_THCM1, start-position=0, transfer-property=PENDING
          signal CAN1_BatteryMode: start 118, 3 bit, big-endian, i-signal-type=PRIMITIVE, init-value=constant-reference=Init_CAN1_BatteryMode, base-type=uint8, implementation-data-type=uint8, transfer-property=PENDING
          signal CAN1_CCU_ACLampSts: start 6, 1 bit, big-endian, i-signal-type=PRIMITIVE, init-value=constant-reference=Init_CAN1_CCU_ACLampSts, base-type=uint8, implementation-data-type=uint8, transfer-property=PENDING
          signal CAN1_CCU_ACMaxLampSts: start 1, 1 bit, big-endian, i-signal-type=PRIMITIVE, init-value=constant-reference=Init_CAN1_CCU_ACMaxLampSts, base-type=uint8, implementation-data-type=uint8, transfer-property=PENDING
          signal CAN1_CCU_AutoLampSts: start 2, 1 bit, big-endian, i-signal-type=PRIMITIVE, init-value=constant-reference=Init_CAN1_CCU_AutoLampSts, base-type=uint8, implementation-data-type=uint8, transfer-property=PENDING
          signal CAN1_CCU_AutoMidLampSts: start 3, 1 bit, big-endian, i-signal-type=PRIMITIVE, init-value=constant-reference=Init_CAN1_CCU_AutoMidLampSts, base-type=uint8, implementation-data-type=uint8, transfer-property=PENDING
          signal CAN1_CCU_Dispaly_Request: start 5, 1 bit, big-endian, i-signal-type=PRIMITIVE, init-value=constant-reference=Init_CAN1_CCU_Dispaly_Request, base-type=uint8, implementation-data-type=uint8, transfer-property=PENDING
          signal CAN1_CCU_EcoSts: start 4, 1 bit, big-endian, i-signal-type=PRIMITIVE, init-value=constant-reference=Init_CAN1_CCU_EcoSts, base-type=uint8, implementation-data-type=uint8, transfer-property=PENDING
          signal CAN1_CCU_FrtOnOffLampSts: start 19, 1 bit, big-endian, i-signal-type=PRIMITIVE, init-value=constant-reference=Init_CAN1_CCU_FrtOnOffLampSts, base-type=uint8, implementation-data-type=uint8, transfer-property=PENDING
          signal CAN1_CCU_HEATMaxLampSts: start 7, 1 bit, big-endian, i-signal-type=PRIMITIVE, init-value=constant-reference=Init_CAN1_CCU_HEATMaxLampSts, base-type=uint8, implementation-data-type=uint8, transfer-property=PENDING
          signal CAN1_CCU_RrOnOffLampSts: start 23, 1 bit, big-endian, i-signal-type=PRIMITIVE, init-value=constant-reference=Init_CAN1_CCU_RrOnOffLampSts, base-type=uint8, implementation-data-type=uint8, transfer-property=PENDING
          signal CAN1_CCU_SyncLampSts: start 39, 1 bit, big-endian, i-signal-type=PRIMITIVE, init-value=constant-reference=Init_CAN1_CCU_SyncLampSts, base-type=uint8, implementation-data-type=uint8, transfer-property=PENDING
          signal CAN1_CabinMode: start 115, 4 bit, big-endian, i-signal-type=PRIMITIVE, init-value=constant-reference=Init_CAN1_CabinMode, base-type=uint8, implementation-data-type=uint8, transfer-property=PENDING
          signal CAN1_EDriveMode: start 63, 2 bit, big-endian, i-signal-type=PRIMITIVE, init-value=constant-reference=Init_CAN1_EDriveMode, base-type=uint8, implementation-data-type=uint8, transfer-property=PENDING
          signal CAN1_FD_AGS_Cmd: start 143, 8 bit, big-endian, i-signal-type=PRIMITIVE, init-value=constant-reference=Init_CAN1_FD_AGS_Cmd, base-type=uint8, implementation-data-type=uint8, transfer-property=PENDING
          signal CAN1_FD_RecyAuto_Cmd: start 111, 3 bit, big-endian, i-signal-type=PRIMITIVE, init-value=constant-reference=Init_CAN1_FD_RecyAuto_Cmd, base-type=uint8, implementation-data-type=uint8, transfer-property=PENDING
          signal CAN1_Fr_Coolantflow: start 61, 6 bit, big-endian, i-signal-type=PRIMITIVE, init-value=constant-reference=Init_CAN1_Fr_Coolantflow, base-type=uint8, implementation-data-type=uint8, transfer-property=PENDING
          signal CAN1_Fr_Coolanttemp: start 0, 9 bit, big-endian, i-signal-type=PRIMITIVE, init-value=constant-reference=Init_CAN1_Fr_Coolanttemp, base-type=uint16, implementation-data-type=uint16, transfer-property=PENDING
          signal CAN1_HPThermalRecoveryReq: start 55, 2 bit, big-endian, i-signal-type=PRIMITIVE, init-value=constant-reference=Init_CAN1_HPThermalRecoveryReq, base-type=uint8, implementation-data-type=uint8, transfer-property=PENDING
          signal CAN1_Rr_Coolantflow: start 150, 6 bit, big-endian, i-signal-type=PRIMITIVE, init-value=constant-reference=Init_CAN1_Rr_Coolantflow, base-type=uint8, implementation-data-type=uint8, transfer-property=PENDING
          signal CAN1_Rr_Coolanttemp: start 144, 9 bit, big-endian, i-signal-type=PRIMITIVE, init-value=constant-reference=Init_CAN1_Rr_Coolanttemp, base-type=uint16, implementation-data-type=uint16, transfer-property=PENDING
          signal CAN1_sigAirIntenZon1St: start 31, 4 bit, big-endian, i-signal-type=PRIMITIVE, init-value=constant-reference=Init_CAN1_sigAirIntenZon1St, base-type=uint8, implementation-data-type=uint8, transfer-property=PENDING
          signal CAN1_sigAirIntenZon3St: start 27, 4 bit, big-endian, i-signal-type=PRIMITIVE, init-value=constant-reference=Init_CAN1_sigAirIntenZon3St, base-type=uint8, implementation-data-type=uint8, transfer-property=PENDING
          signal CAN1_sigAmbAirT: start 95, 8 bit, big-endian, i-signal-type=PRIMITIVE, init-value=constant-reference=Init_CAN1_sigAmbAirT, base-type=uint8, implementation-data-type=uint8, transfer-property=PENDING
          signal CAN1_sigCbnAirT: start 87, 8 bit, big-endian, i-signal-type=PRIMITIVE, init-value=constant-reference=Init_CAN1_sigCbnAirT, base-type=uint8, implementation-data-type=uint8, transfer-property=PENDING
          signal CAN1_sigCbnPTCPwrAct: start 79, 8 bit, big-endian, i-signal-type=PRIMITIVE, init-value=constant-reference=Init_CAN1_sigCbnPTCPwrAct, base-type=uint8, implementation-data-type=uint8, transfer-property=PENDING
          signal CAN1_sigCbnSolarLeft: start 127, 8 bit, big-endian, i-signal-type=PRIMITIVE, init-value=constant-reference=Init_CAN1_sigCbnSolarLeft, base-type=uint8, implementation-data-type=uint8, transfer-property=PENDING
          signal CAN1_sigCbnSolarRight: start 103, 8 bit, big-endian, i-signal-type=PRIMITIVE, init-value=constant-reference=Init_CAN1_sigCbnSolarRight, base-type=uint8, implementation-data-type=uint8, transfer-property=PENDING
          signal CAN1_sigClmtCmprPwrAct: start 71, 8 bit, big-endian, i-signal-type=PRIMITIVE, init-value=constant-reference=Init_CAN1_sigClmtCmprPwrAct, base-type=uint8, implementation-data-type=uint8, transfer-property=PENDING
          signal CAN1_sigClntTHvBattOut: start 135, 8 bit, big-endian, i-signal-type=PRIMITIVE, init-value=constant-reference=Init_CAN1_sigClntTHvBattOut, base-type=uint8, implementation-data-type=uint8, transfer-property=PENDING
          signal CAN1_sigDfrstSt: start 38, 1 bit, big-endian, i-signal-type=PRIMITIVE, init-value=constant-reference=Init_CAN1_sigDfrstSt, base-type=uint8, implementation-data-type=uint8, transfer-property=PENDING
          signal CAN1_sigHvacSt: start 46, 1 bit, big-endian, i-signal-type=PRIMITIVE, init-value=constant-reference=Init_CAN1_sigHvacSt, base-type=uint8, implementation-data-type=uint8, transfer-property=PENDING
          signal CAN1_sigRecircSt: start 47, 1 bit, big-endian, i-signal-type=PRIMITIVE, init-value=constant-reference=Init_CAN1_sigRecircSt, base-type=uint8, implementation-data-type=uint8, transfer-property=PENDING
          signal CAN1_sigSetTempZon1St: start 53, 6 bit, big-endian, i-signal-type=PRIMITIVE, init-value=constant-reference=Init_CAN1_sigSetTempZon1St, base-type=uint8, implementation-data-type=uint8, transfer-property=PENDING
          signal CAN1_sigSetTempZon2St: start 45, 6 bit, big-endian, i-signal-type=PRIMITIVE, init-value=constant-reference=Init_CAN1_sigSetTempZon2St, base-type=uint8, implementation-data-type=uint8, transfer-property=PENDING
          signal CAN1_sigSetTempZon3St: start 37, 6 bit, big-endian, i-signal-type=PRIMITIVE, init-value=constant-reference=Init_CAN1_sigSetTempZon3St, base-type=uint8, implementation-data-type=uint8, transfer-property=PENDING
          signal CAN1_sigWindDirZon1St: start 22, 3 bit, big-endian, i-signal-type=PRIMITIVE, init-value=constant-reference=Init_CAN1_sigWindDirZon1St, base-type=uint8, implementation-data-type=uint8, transfer-property=PENDING
          signal CAN1_sigWindDirZon3St: start 18, 3 bit, big-endian, i-signal-type=PRIMITIVE, init-value=constant-reference=Init_CAN1_sigWindDirZon3St, base-type=uint8, implementation-data-type=uint8, transfer-property=PENDING
      frame CAN1_FD1_VCU1: id 0x116, frame-length=12, can-addressing-mode=STANDARD, can-fd-frame-support=true, can-frame-rx-behavior=CAN-FD, can-frame-tx-behavior=CAN-FD
        pdu CAN1_FD1_VCU1: length=12, minimum-delay=0.0, transmission-mode-true-timing={cyclic-timing=time-period=0.1, event-controlled-timing={number-of-repetitions=0, repetition-period=0}}, unused-bit-pattern=0
          mapping CAN1_SG_FD1_VCU1: i-signal-group=CAN1_SG_FD1_VCU1, start-position=0, transfer-property=TRIGGERED-ON-CHANGE
          signal CAN1_CC_Crl_Sta: start 28, 3 bit, big-endian, i-signal-type=PRIMITIVE, init-value=constant-reference=Init_CAN1_CC_Crl_Sta, base-type=uint8, implementation-data-type=uint8, transfer-property=TRIGGERED-ON-CHANGE
          signal CAN1_Eng_AGSCloseSta: start 65, 1 bit, big-endian, i-signal-type=PRIMITIVE, init-value=constant-reference=Init_CAN1_Eng_AGSCloseSta, base-type=uint8, implementation-data-type=uint8, transfer-property=TRIGGERED-ON-CHANGE
          signal CAN1_Eng_ActvDmpDisabSta: start 71, 2 bit, big-endian, i-signal-type=PRIMITIVE, init-value=constant-reference=Init_CAN1_Eng_ActvDmpDisabSta, base-type=uint8, implementation-data-type=uint8, transfer-property=TRIGGERED-ON-CHANGE
          signal CAN1_Eng_CoastDwSta: start 69, 2 bit, big-endian, i-signal-type=PRIMITIVE, init-value=constant-reference=Init_CAN1_Eng_CoastDwSta, base-type=uint8, implementation-data-type=uint8, transfer-property=TRIGGERED-ON-CHANGE
          signal CAN1_Eng_PwrLockSta: start 67, 2 bit, big-endian, i-signal-type=PRIMITIVE, init-value=constant-reference=Init_CAN1_Eng_PwrLockSta, base-type=uint8, implementation-data-type=uint8, transfer-property=TRIGGERED-ON-CHANGE
          signal CAN1_HVPwrSta: start 59, 1 bit, big-endian, i-signal-type=PRIMITIVE, init-value=constant-reference=Init_CAN1_HVPwrSta, base-type=uint8, implementation-data-type=uint8, transfer-property=TRIGGERED-ON-CHANGE
          signal CAN1_LVPwrSta: start 58, 1 bit, big-endian, i-signal-type=PRIMITIVE, init-value=constant-reference=Init_CAN1_LVPwrSta, base-type=uint8, implementation-data-type=uint8, transfer-property=TRIGGERED-ON-CHANGE
          signal CAN1_MSA_Crl_Sta: start 31, 3 bit, big-endian, i-signal-type=PRIMITIVE, init-value=constant-reference=Init_CAN1_MSA_Crl_Sta, base-type=uint8, implementation-data-type=uint8, transfer-property=TRIGGERED-ON-CHANGE
          signal CAN1_P_Button_Sta: start 7, 2 bit, big-endian, i-signal-type=PRIMITIVE, init-value=constant-reference=Init_CAN1_P_Button_Sta, base-type=uint8, implementation-data-type=uint8, transfer-property=TRIGGERED-ON-CHANGE
          signal CAN1_PrkReq: start 45, 1 bit, big-endian, i-signal-type=PRIMITIVE, init-value=constant-reference=Init_CAN1_PrkReq, base-type=uint8, implementation-data-type=uint8, transfer-property=TRIGGERED-ON-CHANGE
          signal CAN1_PrkReqValid: start 4, 1 bit, big-endian, i-signal-type=PRIMITIVE, init-value=constant-reference=Init_CAN1_PrkReqValid, base-type=uint8, implementation-data-type=uint8, transfer-property=TRIGGERED-ON-CHANGE
          signal CAN1_PwrSta: start 63, 3 bit, big-endian, i-signal-type=PRIMITIVE, init-value=constant-reference=Init_CAN1_PwrSta, base-type=uint8, implementation-data-type=uint8, transfer-property=TRIGGERED-ON-CHANGE
          signal CAN1_ShiftGearPosn: start 38, 3 bit, big-endian, i-signal-type=PRIMITIVE, init-value=constant-reference=Init_CAN1_ShiftGearPosn, base-type=uint8, implementation-data-type=uint8, transfer-property=TRIGGERED-ON-CHANGE
          signal CAN1_VehMalfunLevel: start 74, 3 bit, big-endian, i-signal-type=PRIMITIVE, init-value=constant-reference=Init_CAN1_VehMalfunLevel, base-type=uint8, implementation-data-type=uint8, transfer-property=TRIGGERED-ON-CHANGE
          signal CAN1_XWDMode: start 57, 2 bit, big-endian, i-signal-type=PRIMITIVE, init-value=constant-reference=Init_CAN1_XWDMode, base-type=uint8, implementation-data-type=uint8, transfer-property=TRIGGERED-ON-CHANGE
      frame CAN1_FD1_VCU2: id 0x154, frame-length=16, can-addressing-mode=STANDARD, can-fd-frame-support=true, can-frame-rx-behavior=CAN-FD, can-frame-tx-behavior=CAN-FD
        pdu CAN1_FD1_VCU2: length=16, minimum-delay=0.0, transmission-mode-true-timing=cyclic-timing=time-period=0.01, unused-bit-pattern=0
          mapping CAN1_SG_FD1_VCU2: i-signal-group=CAN1_SG_FD1_VCU2, start-position=0, transfer-property=PENDING
          signal CAN1_ACC_CtrlAvail: start 55, 1 bit, big-endian, i-signal-type=PRIMITIVE, init-value=constant-reference=Init_CAN1_ACC_CtrlAvail, base-type=uint8, implementation-data-type=uint8, transfer-property=PENDING
          signal CAN1_AccPedal_Override: start 54, 1 bit, big-endian, i-signal-type=PRIMITIVE, init-value=constant-reference=Init_CAN1_AccPedal_Override, base-type=uint8, implementation-data-type=uint8, transfer-property=PENDING
          signal CAN1_ActAPSPosn: start 127, 8 bit, big-endian, i-signal-type=PRIMITIVE, init-value=constant-reference=Init_CAN1_ActAPSPosn, base-type=uint8, implementation-data-type=uint8, transfer-property=PENDING
          signal CAN1_CS_VCU2_CAN1: start 7, 8 bit, big-endian, i-signal-type=PRIMITIVE, init-value=constant-reference=Init_CAN1_CS_VCU2_CAN1, base-type=uint8, implementation-data-type=uint8, transfer-property=PENDING
          signal CAN1_DriverTq: start 111, 16 bit, big-endian, i-signal-type=PRIMITIVE, init-value=constant-reference=Init_CAN1_DriverTq, base-type=uint16, implementation-data-type=uint16, transfer-property=PENDING
          signal CAN1_Fr_DriverTq: start 23, 16 bit, big-endian, i-signal-type=PRIMITIVE, init-value=constant-reference=Init_CAN1_Fr_DriverTq, base-type=uint16, implementation-data-type=uint16, transfer-property=PENDING
          signal CAN1_RC_VCU2_CAN1: start 11, 4 bit, big-endian, i-signal-type=PRIMITIVE, init-value=constant-reference=Init_CAN1_RC_VCU2_CAN1, base-type=uint8, implementation-data-type=uint8, transfer-property=PENDING
          signal CAN1_Rr_DriverTq: start 39, 16 bit, big-endian, i-signal-type=PRIMITIVE, init-value=constant-reference=Init_CAN1_Rr_DriverTq, base-type=uint16, implementation-data-type=uint16, transfer-property=PENDING
          signal CAN1_VehActPwr: start 87, 24 bit, big-endian, i-signal-type=PRIMITIVE, init-value=constant-reference=Init_CAN1_VehActPwr, base-type=uint32, implementation-data-type=uint32, transfer-property=PENDING
      frame CAN1_FD1_VCU3: id 0x159, frame-length=20, can-addressing-mode=STANDARD, can-fd-frame-support=true, can-frame-rx-behavior=CAN-FD, can-frame-tx-behavior=CAN-FD
        pdu CAN1_FD1_VCU3: length=20, minimum-delay=0.0, transmission-mode-true-timing=cyclic-timing=time-period=0.01, unused-bit-pattern=0
          mapping CAN1_SG_FD1_VCU3: i-signal-group=CAN1_SG_FD1_VCU3, start-position=0, transfer-property=PENDING
          signal CAN1_CS_VCU3_CAN1: start 7, 8 bit, big-endian, i-signal-type=PRIMITIVE, init-value=constant-reference=Init_CAN1_CS_VCU3_CAN1, base-type=uint8, implementation-data-type=uint8, transfer-property=PENDING
          signal CAN1_EquivAccPedalSWSta: start 38, 1 bit, big-endian, i-signal-type=PRIMITIVE, init-value=constant-reference=Init_CAN1_EquivAccPedalSWSta, base-type=uint8, implementation-data-type=uint8, transfer-property=PENDING
          signal CAN1_Fr_EDUAvailBrkRgnTq: start 135, 16 bit, big-endian, i-signal-type=PRIMITIVE, init-value=constant-reference=Init_CAN1_Fr_EDUAvailBrkRgnTq, base-type=uint16, implementation-data-type=uint16, transfer-property=PENDING
          signal CAN1_Fr_EDUAvailBrkRgnTqValid: start 102, 1 bit, big-endian, i-signal-type=PRIMITIVE, init-value=constant-reference=Init_CAN1_Fr_EDUAvailBrkRgnTqValid, base-type=uint8, implementation-data-type=uint8, transfer-property=PENDING
          signal CAN1_Fr_EDURealARgnTq: start 119, 16 bit, big-endian, i-signal-type=PRIMITIVE, init-value=constant-reference=Init_CAN1_Fr_EDURealARgnTq, base-type=uint16, implementation-data-type=uint16, transfer-property=PENDING
          signal CAN1_Fr_EDURealDrvOrBRgnTq: start 151, 16 bit, big-endian, i-signal-type=PRIMITIVE, init-value=constant-reference=Init_CAN1_Fr_EDURealDrvOrBRgnTq, base-type=uint16, implementation-data-type=uint16, transfer-property=PENDING
          signal CAN1_Fr_EDUSpd: start 99, 12 bit, big-endian, i-signal-type=PRIMITIVE, init-value=constant-reference=Init_CAN1_Fr_EDUSpd, base-type=uint16, implementation-data-type=uint16, transfer-property=PENDING
          signal CAN1_Fr_EDUSpdValid: start 30, 1 bit, big-endian, i-signal-type=PRIMITIVE, init-value=constant-reference=Init_CAN1_Fr_EDUSpdValid, base-type=uint8, implementation-data-type=uint8, transfer-property=PENDING
          signal CAN1_Fr_RgnDecrSta: start 27, 1 bit, big-endian, i-signal-type=PRIMITIVE, init-value=constant-reference=Init_CAN1_Fr_RgnDecrSta, base-type=uint8, implementation-data-type=uint8, transfer-property=PENDING
          signal CAN1_Fr_RgnPermSta: start 25, 1 bit, big-endian, i-signal-type=PRIMITIVE, init-value=constant-reference=Init_CAN1_Fr_RgnPermSta, base-type=uint8, implementation-data-type=uint8, transfer-property=PENDING
          signal CAN1_PTCS_PermSta: start 39, 1 bit, big-endian, i-signal-type=PRIMITIVE, init-value=constant-reference=Init_CAN1_PTCS_PermSta, base-type=uint8, implementation-data-type=uint8, transfer-property=PENDING
          signal CAN1_RC_VCU3_CAN1: start 11, 4 bit, big-endian, i-signal-type=PRIMITIVE, init-value=constant-reference=Init_CAN1_RC_VCU3_CAN1, base-type=uint8, implementation-data-type=uint8, transfer-property=PENDING
          signal CAN1_RgnAbnorSta: start 28, 1 bit, big-endian, i-signal-type=PRIMITIVE, init-value=constant-reference=Init_CAN1_RgnAbnorSta, base-type=uint8, implementation-data-type=uint8, transfer-property=PENDING
          signal CAN1_Rr_EDUAvailBrkRgnTq: start 71, 16 bit, big-endian, i-signal-type=PRIMITIVE, init-value=constant-reference=Init_CAN1_Rr_EDUAvailBrkRgnTq, base-type=uint16, implementation-data-type=uint16, transfer-property=PENDING
          signal CAN1_Rr_EDUAvailBrkRgnTqValid: start 103, 1 bit, big-endian, i-signal-type=PRIMITIVE, init-value=constant-reference=Init_CAN1_Rr_EDUAvailBrkRgnTqValid, base-type=uint8, implementation-data-type=uint8, transfer-property=PENDING
          signal CAN1_Rr_EDURealARgnTq: start 55, 16 bit, big-endian, i-signal-type=PRIMITIVE, init-value=constant-reference=Init_CAN1_Rr_EDURealARgnTq, base-type=uint16, implementation-data-type=uint16, transfer-property=PENDING
          signal CAN1_Rr_EDURealDrvOrBRgnTq: start 87, 16 bit, big-endian, i-signal-type=PRIMITIVE, init-value=constant-reference=Init_CAN1_Rr_EDURealDrvOrBRgnTq, base-type=uint16, implementation-data-type=uint16, transfer-property=PENDING
          signal CAN1_Rr_EDUSpd: start 35, 12 bit, big-endian, i-signal-type=PRIMITIVE, init-value=constant-reference=Init_CAN1_Rr_EDUSpd, base-type=uint16, implementation-data-type=uint16, transfer-property=PENDING
          signal CAN1_Rr_EDUSpdValid: start 29, 1 bit, big-endian, i-signal-type=PRIMITIVE, init-value=constant-reference=Init_CAN1_Rr_EDUSpdValid, base-type=uint8, implementation-data-type=uint8, transfer-property=PENDING
          signal CAN1_Rr_RgnDecrSta: start 26, 1 bit, big-endian, i-signal-type=PRIMITIVE, init-value=constant-reference=Init_CAN1_Rr_RgnDecrSta, base-type=uint8, implementation-data-type=uint8, transfer-property=PENDING
          signal CAN1_Rr_RgnPermSta: start 24, 1 bit, big-endian, i-signal-type=PRIMITIVE, init-value=constant-reference=Init_CAN1_Rr_RgnPermSta, base-type=uint8, implementation-data-type=uint8, transfer-property=PENDING
      frame CAN1_FD1_VMC1: id 0x17F, frame-length=24, can-addressing-mode=STANDARD, can-fd-frame-support=true, can-frame-rx-behavior=CAN-FD, can-frame-tx-behavior=CAN-FD
        pdu CAN1_FD1_VMC1: length=24, minimum-delay=0.0, transmission-mode-true-timing={cyclic-timing=time-period=0.01, event-controlled-timing={number-of-repetitions=0, repetition-period=0}}, unused-bit-pattern=0
          mapping CAN1_SG_FD1_VMC1: i-signal-group=CAN1_SG_FD1_VMC1, start-position=0, transfer-property=TRIGGERED-ON-CHANGE
          signal CAN1_AccCalcuPID: start 72, 9 bit, big-endian, i-signal-type=PRIMITIVE, init-value=constant-reference=Init_CAN1_AccCalcuPID, base-type=uint16, implementation-data-type=uint16, transfer-property=PENDING
          signal CAN1_CCMSA_SpdWar: start 133, 1 bit, big-endian, i-signal-type=PRIMITIVE, init-value=constant-reference=Init_CAN1_CCMSA_SpdWar, base-type=uint8, implementation-data-type=uint8, transfer-property=TRIGGERED-ON-CHANGE
          signal CAN1_DISCReqAcc: start 56, 9 bit, big-endian, i-signal-type=PRIMITIVE, init-value=constant-reference=Init_CAN1_DISCReqAcc, base-type=uint16, implementation-data-type=uint16, transfer-property=PENDING
          signal CAN1_DISC_ButtSta: start 60, 1 bit, big-endian, i-signal-type=PRIMITIVE, init-value=constant-reference=Init_CAN1_DISC_ButtSta, base-type=uint8, implementation-data-type=uint8, transfer-property=PENDING
          signal CAN1_DISC_DISCTargetSpd: start 91, 12 bit, big-endian, i-signal-type=PRIMITIVE, init-value=constant-reference=Init_CAN1_DISC_DISCTargetSpd, base-type=uint16, implementation-data-type=uint16, transfer-property=PENDING
          signal CAN1_DISC_DISCTurn: start 62, 1 bit, big-endian, i-signal-type=PRIMITIVE, init-value=constant-reference=Init_CAN1_DISC_DISCTurn, base-type=uint8, implementation-data-type=uint8, transfer-property=PENDING
          signal CAN1_DISC_Sta: start 132, 2 bit, big-endian, i-signal-type=PRIMITIVE, init-value=constant-reference=Init_CAN1_DISC_Sta, base-type=uint8, implementation-data-type=uint8, transfer-property=PENDING
          signal CAN1_FeatArbitrFinal: start 59, 3 bit, big-endian, i-signal-type=PRIMITIVE, init-value=constant-reference=Init_CAN1_FeatArbitrFinal, base-type=uint8, implementation-data-type=uint8, transfer-property=PENDING
          signal CAN1_FeatArbitrSta: start 130, 3 bit, big-endian, i-signal-type=PRIMITIVE, init-value=constant-reference=Init_CAN1_FeatArbitrSta, base-type=uint8, implementation-data-type=uint8, transfer-property=PENDING
          signal CAN1_FeatReqSpd: start 178, 11 bit, big-endian, i-signal-type=PRIMITIVE, init-value=constant-reference=Init_CAN1_FeatReqSpd, base-type=uint16, implementation-data-type=uint16, transfer-property=PENDING
          signal CAN1_FeatSetSpdFinal_raw32: start 47, 8 bit, big-endian, i-signal-type=PRIMITIVE, init-value=constant-reference=Init_CAN1_FeatSetSpdFinal_raw32, base-type=uint8, implementation-data-type=uint8, transfer-property=PENDING
          signal CAN1_FrontRearSlipRatioCtrl: start 159, 1 bit, big-endian, i-signal-type=PRIMITIVE, init-value=constant-reference=Init_CAN1_FrontRearSlipRatioCtrl, base-type=uint8, implementation-data-type=uint8, transfer-property=PENDING
          signal CAN1_JerkPCT: start 150, 7 bit, big-endian, i-signal-type=PRIMITIVE, init-value=constant-reference=Init_CAN1_JerkPCT, base-type=uint8, implementation-data-type=uint8, transfer-property=PENDING
          signal CAN1_LatAccCtrl: start 134, 1 bit, big-endian, i-signal-type=PRIMITIVE, init-value=constant-reference=Init_CAN1_LatAccCtrl, base-type=uint8, implementation-data-type=uint8, transfer-property=PENDING
          signal CAN1_LateralCtrl: start 135, 1 bit, big-endian, i-signal-type=PRIMITIVE, init-value=constant-reference=Init_CAN1_LateralCtrl, base-type=uint8, implementation-data-type=uint8, transfer-property=PENDING
          signal CAN1_LimitPCT: start 142, 7 bit, big-endian, i-signal-type=PRIMITIVE, init-value=constant-reference=Init_CAN1_LimitPCT, base-type=uint8, implementation-data-type=uint8, transfer-property=PENDING
          signal CAN1_MeterIndSpeed_raw32: start 55, 8 bit, big-endian, i-signal-type=PRIMITIVE, init-value=constant-reference=Init_CAN1_MeterIndSpeed_raw32, base-type=uint8, implementation-data-type=uint8, transfer-property=PENDING
          signal CAN1_RearWhlSlipRatioCtrl: start 158, 1 bit, big-endian, i-signal-type=PRIMITIVE, init-value=constant-reference=Init_CAN1_RearWhlSlipRatioCtrl, base-type=uint8, implementation-data-type=uint8, transfer-property=PENDING
          signal CAN1_SPD2ACCAct: start 61, 1 bit, big-endian, i-signal-type=PRIMITIVE, init-value=constant-reference=Init_CAN1_SPD2ACCAct, base-type=uint8, implementation-data-type=uint8, transfer-property=PENDING
          signal CAN1_SafetyCtrl: start 143, 1 bit, big-endian, i-signal-type=PRIMITIVE, init-value=constant-reference=Init_CAN1_SafetyCtrl, base-type=uint8, implementation-data-type=uint8, transfer-property=PENDING
          signal CAN1_SingleWhlSlipRatioCtrl: start 151, 1 bit, big-endian, i-signal-type=PRIMITIVE, init-value=constant-reference=Init_CAN1_SingleWhlSlipRatioCtrl, base-type=uint8, implementation-data-type=uint8, transfer-property=PENDING
          signal CAN1_TimeGapCalcu: start 175, 8 bit, big-endian, i-signal-type=PRIMITIVE, init-value=constant-reference=Init_CAN1_TimeGapCalcu, base-type=uint8, implementation-data-type=uint8, transfer-property=PENDING
          signal CAN1_VMC_ACCCtrlAvail: start 167, 1 bit, big-endian, i-signal-type=PRIMITIVE, init-value=constant-reference=Init_CAN1_VMC_ACCCtrlAvail, base-type=uint8, implementation-data-type=uint8, transfer-property=PENDING
          signal CAN1_VMC_AEBCtrlAvail: start 155, 1 bit, big-endian, i-signal-type=PRIMITIVE, init-value=constant-reference=Init_CAN1_VMC_AEBCtrlAvail, base-type=uint8, implementation-data-type=uint8, transfer-property=PENDING
          signal CAN1_VMC_CCCtrlAvail: start 156, 1 bit, big-endian, i-signal-type=PRIMITIVE, init-value=constant-reference=Init_CAN1_VMC_CCCtrlAvail, base-type=uint8, implementation-data-type=uint8, transfer-property=PENDING
          signal CAN1_VMC_MSACtrlAvail: start 157, 1 bit, big-endian, i-signal-type=PRIMITIVE, init-value=constant-reference=Init_CAN1_VMC_MSACtrlAvail, base-type=uint8, implementation-data-type=uint8, transfer-property=PENDING
          signal CAN1_VMC_VCU_ACC_CtrlAvail: start 160, 1 bit, big-endian, i-signal-type=PRIMITIVE, init-value=constant-reference=Init_CAN1_VMC_VCU_ACC_CtrlAvail, base-type=uint8, implementation-data-type=uint8, transfer-property=PENDING
          signal CAN1_VMC_VCU_APSCtrlAvail_flg: start 166, 1 bit, big-endian, i-signal-type=PRIMITIVE, init-value=constant-reference=Init_CAN1_VMC_VCU_APSCtrlAvail_flg, base-type=uint8, implementation-data-type=uint8, transfer-property=PENDING
          signal CAN1_VMC_VCU_AccPedal_Override: start 161, 1 bit, big-endian, i-signal-type=PRIMITIVE, init-value=constant-reference=Init_CAN1_VMC_VCU_AccPedal_Override, base-type=uint8, implementation-data-type=uint8, transfer-property=PENDING
          signal CAN1_VMC_VCU_CC_Crl_Sta: start 154, 3 bit, big-endian, i-signal-type=PRIMITIVE, init-value=constant-reference=Init_CAN1_VMC_VCU_CC_Crl_Sta, base-type=uint8, implementation-data-type=uint8, transfer-property=PENDING
          signal CAN1_VMC_VCU_MSA_Crl_Sta: start 165, 3 bit, big-endian, i-signal-type=PRIMITIVE, init-value=constant-reference=Init_CAN1_VMC_VCU_MSA_Crl_Sta, base-type=uint8, implementation-data-type=uint8, transfer-property=PENDING
          signal CAN1_VehicleSpeed_kph: start 111, 12 bit, big-endian, i-signal-type=PRIMITIVE, init-value=constant-reference=Init_CAN1_VehicleSpeed_kph, base-type=uint16, implementation-data-type=uint16, transfer-property=PENDING
          signal CAN1_VehicleSpeed_mph: start 115, 12 bit, big-endian, i-signal-type=PRIMITIVE, init-value=constant-reference=Init_CAN1_VehicleSpeed_mph, base-type=uint16, implementation-data-type=uint16, transfer-property=PENDING
      frame CAN1_FD1_VMC2: id 0x77, frame-length=32, can-addressing-mode=STANDARD, can-fd-frame-support=true, can-frame-rx-behavior=CAN-FD, can-frame-tx-behavior=CAN-FD
        pdu CAN1_FD1_VMC2: length=32, minimum-delay=0.0, transmission-mode-true-timing=cyclic-timing=time-period=0.5, unused-bit-pattern=0
          mapping CAN1_SG_FD1_VMC2: i-signal-group=CAN1_SG_FD1_VMC2, start-position=0, transfer-property=PENDING
          signal CAN1_FDC_VMC_RWS_Actv_Sta: start 138, 2 bit, little-endian, i-signal-type=PRIMITIVE, init-value=constant-reference=Init_CAN1_FDC_VMC_RWS_Actv_Sta, base-type=uint8, implementation-data-type=uint8, transfer-property=PENDING
          signal CAN1_FDC_VMC_RWS_Dfctv_Sta: start 140, 2 bit, little-endian, i-signal-type=PRIMITIVE, init-value=constant-reference=Init_CAN1_FDC_VMC_RWS_Dfctv_Sta, base-type=uint8, implementation-data-type=uint8, transfer-property=PENDING
          signal CAN1_FDC_VMC_RWS_PositionReq_Cmd: start 144, 16 bit, little-endian, i-signal-type=PRIMITIVE, init-value=constant-reference=Init_CAN1_FDC_VMC_RWS_PositionReq_Cmd, base-type=uint16, implementation-data-type=uint16, transfer-property=PENDING
          signal CAN1_FDC_VMC_SteerFaultReq_Cmd: start 83, 2 bit, little-endian, i-signal-type=PRIMITIVE, init-value=constant-reference=Init_CAN1_FDC_VMC_SteerFaultReq_Cmd, base-type=uint8, implementation-data-type=uint8, transfer-property=PENDING
      frame CAN1_GW1_CE100_0: id 0x23F, frame-length=32, can-addressing-mode=STANDARD, can-fd-frame-support=true, can-frame-rx-behavior=CAN-FD, can-frame-tx-behavior=CAN-FD
        pdu CAN1_GW1_CE100_0: length=32, minimum-delay=0.0, transmission-mode-true-timing={cyclic-timing=time-period=0.1, event-controlled-timing={number-of-repetitions=0, repetition-period=0}}, unused-bit-pattern=0
          mapping CAN1_SG_GW1_CE100_0: i-signal-group=CAN1_SG_GW1_CE100_0, start-position=0, transfer-property=TRIGGERED-ON-CHANGE
          signal CAN1_BMS_READY: start 7, 1 bit, big-endian, i-signal-type=PRIMITIVE, init-value=constant-reference=Init_CAN1_BMS_READY, base-type=uint8, implementation-data-type=uint8, transfer-property=TRIGGERED-ON-CHANGE
          signal CAN1_Fr_TMSpd: start 23, 16 bit, big-endian, i-signal-type=PRIMITIVE, init-value=constant-reference=Init_CAN1_Fr_TMSpd, base-type=uint16, implementation-data-type=uint16, transfer-property=PENDING
          signal CAN1_Rr_TMSpd: start 39, 16 bit, big-endian, i-signal-type=PRIMITIVE, init-value=constant-reference=Init_CAN1_Rr_TMSpd, base-type=uint16, implementation-data-type=uint16, transfer-property=PENDING
      frame CAN1_GW1_CE200_0: id 0x495, frame-length=64, can-addressing-mode=STANDARD, can-fd-frame-support=true, can-frame-rx-behavior=CAN-FD, can-frame-tx-behavior=CAN-FD
        pdu CAN1_GW1_CE200_0: length=64, minimum-delay=0.0, transmission-mode-true-timing={cyclic-timing=time-period=0.2, event-controlled-timing={number-of-repetitions=0, repetition-period=0}}, unused-bit-pattern=0
          mapping CAN1_SG_GW1_CE200_0: i-signal-group=CAN1_SG_GW1_CE200_0, start-position=0, transfer-property=TRIGGERED-ON-CHANGE
          signal CAN1_ESC_SW_Cmd: start 245, 2 bit, big-endian, i-signal-type=PRIMITIVE, init-value=constant-reference=Init_CAN1_ESC_SW_Cmd, base-type=uint8, implementation-data-type=uint8, transfer-property=TRIGGERED-ON-CHANGE
          signal CAN1_Roll_Eng_Mode: start 478, 1 bit, big-endian, i-signal-type=PRIMITIVE, init-value=constant-reference=Init_CAN1_Roll_Eng_Mode, base-type=uint8, implementation-data-type=uint8, transfer-property=TRIGGERED-ON-CHANGE
          signal CAN1_Roll_Mode_SW_Cmd: start 473, 2 bit, big-endian, i-signal-type=PRIMITIVE, init-value=constant-reference=Init_CAN1_Roll_Mode_SW_Cmd, base-type=uint8, implementation-data-type=uint8, transfer-property=TRIGGERED-ON-CHANGE
          signal CAN1_TCS_SW_Cmd: start 475, 2 bit, big-endian, i-signal-type=PRIMITIVE, init-value=constant-reference=Init_CAN1_TCS_SW_Cmd, base-type=uint8, implementation-data-type=uint8, transfer-property=TRIGGERED-ON-CHANGE
      frame CAN1_VMC_FCM1: id 0x172, frame-length=32, can-addressing-mode=STANDARD, can-fd-frame-support=true, can-frame-rx-behavior=CAN-FD, can-frame-tx-behavior=CAN-FD
        pdu CAN1_VMC_FCM1: length=32, minimum-delay=0.0, transmission-mode-true-timing=cyclic-timing=time-period=0.01, unused-bit-pattern=0
          mapping CAN1_SG_VMC_FCM1: i-signal-group=CAN1_SG_VMC_FCM1, start-position=0, transfer-property=PENDING
          signal CAN1_FDC_VMC_AngCtrlTqWtGn: start 111, 8 bit, big-endian, i-signal-type=PRIMITIVE, init-value=constant-reference=Init_CAN1_FDC_VMC_AngCtrlTqWtGn, base-type=uint8, implementation-data-type=uint8, transfer-property=PENDING
          signal CAN1_FDC_VMC_DMSMode_Cmd: start 123, 4 bit, big-endian, i-signal-type=PRIMITIVE, init-value=constant-reference=Init_CAN1_FDC_VMC_DMSMode_Cmd, base-type=uint8, implementation-data-type=uint8, transfer-property=PENDING
          signal CAN1_FDC_VMC_DrInpTqBstAct: start 89, 1 bit, big-endian, i-signal-type=PRIMITIVE, init-value=constant-reference=Init_CAN1_FDC_VMC_DrInpTqBstAct, base-type=uint8, implementation-data-type=uint8, transfer-property=PENDING
          signal CAN1_FDC_VMC_DrInpTqBstGn: start 119, 8 bit, big-endian, i-signal-type=PRIMITIVE, init-value=constant-reference=Init_CAN1_FDC_VMC_DrInpTqBstGn, base-type=uint8, implementation-data-type=uint8, transfer-property=PENDING
          signal CAN1_FDC_VMC_MaxAngCtrlOutTqLim: start 88, 9 bit, big-endian, i-signal-type=PRIMITIVE, init-value=constant-reference=Init_CAN1_FDC_VMC_MaxAngCtrlOutTqLim, base-type=uint16, implementation-data-type=uint16, transfer-property=PENDING
          signal CAN1_VMC_ACC_ComfortBandLower: start 72, 9 bit, big-endian, i-signal-type=PRIMITIVE, init-value=constant-reference=Init_CAN1_VMC_ACC_ComfortBandLower, base-type=uint16, implementation-data-type=uint16, transfer-property=PENDING
          signal CAN1_VMC_ACC_ComfortBandUpper: start 56, 9 bit, big-endian, i-signal-type=PRIMITIVE, init-value=constant-reference=Init_CAN1_VMC_ACC_ComfortBandUpper, base-type=uint16, implementation-data-type=uint16, transfer-property=PENDING
          signal CAN1_VMC_ACC_JerkLowerLInit: start 79, 7 bit, big-endian, i-signal-type=PRIMITIVE, init-value=constant-reference=Init_CAN1_VMC_ACC_JerkLowerLInit, base-type=uint8, implementation-data-type=uint8, transfer-property=PENDING
          signal CAN1_VMC_ACC_JerkUpperLInit: start 63, 7 bit, big-endian, i-signal-type=PRIMITIVE, init-value=constant-reference=Init_CAN1_VMC_ACC_JerkUpperLInit, base-type=uint8, implementation-data-type=uint8, transfer-property=PENDING
          signal CAN1_VMC_ACC_RequiredAccel: start 40, 9 bit, big-endian, i-signal-type=PRIMITIVE, init-value=constant-reference=Init_CAN1_VMC_ACC_RequiredAccel, base-type=uint16, implementation-data-type=uint16, transfer-property=PENDING
          signal CAN1_VMC_ACC_VehHoldReq: start 47, 1 bit, big-endian, i-signal-type=PRIMITIVE, init-value=constant-reference=Init_CAN1_VMC_ACC_VehHoldReq, base-type=uint8, implementation-data-type=uint8, transfer-property=PENDING
          signal CAN1_VMC_ADAS_ACC_Sta: start 95, 3 bit, big-endian, i-signal-type=PRIMITIVE, init-value=constant-reference=Init_CAN1_VMC_ADAS_ACC_Sta, base-type=uint8, implementation-data-type=uint8, transfer-property=PENDING
          signal CAN1_VMC_ADAS_AEBReq: start 43, 3 bit, big-endian, i-signal-type=PRIMITIVE, init-value=constant-reference=Init_CAN1_VMC_ADAS_AEBReq, base-type=uint8, implementation-data-type=uint8, transfer-property=PENDING
          signal CAN1_VMC_ADAS_AEB_Sta: start 92, 3 bit, big-endian, i-signal-type=PRIMITIVE, init-value=constant-reference=Init_CAN1_VMC_ADAS_AEB_Sta, base-type=uint8, implementation-data-type=uint8, transfer-property=PENDING
          signal CAN1_VMC_ADAS_DBSReq: start 46, 2 bit, big-endian, i-signal-type=PRIMITIVE, init-value=constant-reference=Init_CAN1_VMC_ADAS_DBSReq, base-type=uint8, implementation-data-type=uint8, transfer-property=PENDING
          signal CAN1_VMC_ADAS_FaultSta: start 44, 1 bit, big-endian, i-signal-type=PRIMITIVE, init-value=constant-reference=Init_CAN1_VMC_ADAS_FaultSta, base-type=uint8, implementation-data-type=uint8, transfer-property=PENDING
          signal CAN1_VMC_AEB_VehHoldReq: start 27, 1 bit, big-endian, i-signal-type=PRIMITIVE, init-value=constant-reference=Init_CAN1_VMC_AEB_VehHoldReq, base-type=uint8, implementation-data-type=uint8, transfer-property=PENDING
          signal CAN1_VMC_FCM1_Checksum: start 7, 8 bit, big-endian, i-signal-type=PRIMITIVE, init-value=constant-reference=Init_CAN1_VMC_FCM1_Checksum, base-type=uint8, implementation-data-type=uint8, transfer-property=PENDING
          signal CAN1_VMC_FCM1_LifeCount: start 11, 4 bit, big-endian, i-signal-type=PRIMITIVE, init-value=constant-reference=Init_CAN1_VMC_FCM1_LifeCount, base-type=uint8, implementation-data-type=uint8, transfer-property=PENDING
          signal CAN1_VMC_FCM_LDW_Fault: start 29, 1 bit, big-endian, i-signal-type=PRIMITIVE, init-value=constant-reference=Init_CAN1_VMC_FCM_LDW_Fault, base-type=uint8, implementation-data-type=uint8, transfer-property=PENDING
          signal CAN1_VMC_FCM_LDW_Request: start 31, 2 bit, big-endian, i-signal-type=PRIMITIVE, init-value=constant-reference=Init_CAN1_VMC_FCM_LDW_Request, base-type=uint8, implementation-data-type=uint8, transfer-property=PENDING
          signal CAN1_VMC_FCM_LKA_StrToqReq: start 26, 11 bit, big-endian, i-signal-type=PRIMITIVE, init-value=constant-reference=Init_CAN1_VMC_FCM_LKA_StrToqReq, base-type=uint16, implementation-data-type=uint16, transfer-property=PENDING
          signal CAN1_VMC_FCM_LKA_TOIAct: start 23, 8 bit, big-endian, i-signal-type=PRIMITIVE, init-value=constant-reference=Init_CAN1_VMC_FCM_LKA_TOIAct, base-type=uint8, implementation-data-type=uint8, transfer-property=PENDING
          signal CAN1_VMC_FCM_LKA_TOIFault: start 28, 1 bit, big-endian, i-signal-type=PRIMITIVE, init-value=constant-reference=Init_CAN1_VMC_FCM_LKA_TOIFault, base-type=uint8, implementation-data-type=uint8, transfer-property=PENDING
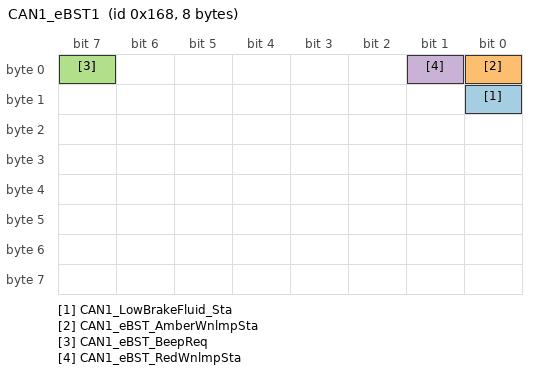
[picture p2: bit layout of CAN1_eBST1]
      frame CAN1_eBST1: id 0x168, frame-length=8, can-addressing-mode=STANDARD, can-fd-frame-support=true, can-frame-rx-behavior=CAN-FD, can-frame-tx-behavior=CAN-FD
        pdu CAN1_eBST1: length=8, minimum-delay=0.0, transmission-mode-true-timing=cyclic-timing=time-period=0.01, unused-bit-pattern=0
          mapping CAN1_SG_eBST1: i-signal-group=CAN1_SG_eBST1, start-position=0, transfer-property=PENDING
          signal CAN1_LowBrakeFluid_Sta: start 8, 1 bit, big-endian, i-signal-type=PRIMITIVE, init-value=constant-reference=Init_CAN1_LowBrakeFluid_Sta, base-type=uint8, implementation-data-type=uint8, transfer-property=PENDING
          signal CAN1_eBST_AmberWnlmpSta: start 0, 1 bit, big-endian, i-signal-type=PRIMITIVE, init-value=constant-reference=Init_CAN1_eBST_AmberWnlmpSta, base-type=uint8, implementation-data-type=uint8, transfer-property=PENDING
          signal CAN1_eBST_BeepReq: start 7, 1 bit, big-endian, i-signal-type=PRIMITIVE, init-value=constant-reference=Init_CAN1_eBST_BeepReq, base-type=uint8, implementation-data-type=uint8, transfer-property=PENDING
          signal CAN1_eBST_RedWnlmpSta: start 1, 1 bit, big-endian, i-signal-type=PRIMITIVE, init-value=constant-reference=Init_CAN1_eBST_RedWnlmpSta, base-type=uint8, implementation-data-type=uint8, transfer-property=PENDING
      frame CAN1_NMm_FUSION_TX: id 0x500, frame-length=8, can-addressing-mode=STANDARD, can-fd-frame-support=false, can-frame-rx-behavior=CAN-20, can-frame-tx-behavior=CAN-20
        nm pdu CAN1_NMm_FUSION_TX: length=8, unused-bit-pattern=0
      frame CAN1_NMm_FUSION_RX: id 0x500, frame-length=8, can-addressing-mode=STANDARD, can-fd-frame-support=false, can-frame-rx-behavior=CAN-20, can-frame-tx-behavior=CAN-20
        nm pdu CAN1_NMm_FUSION_RX: length=8, unused-bit-pattern=0
package /CAN1/ConstantSpecification
  438 x constant specification:
    Init_CAN1_ABM_Passenger_ODS_Sta: value-spec=0
    Init_CAN1_ABM_RearPassengerCTR_ODS_Sta: value-spec=0
    Init_CAN1_ABM_RearPassengerLH_ODS_Sta: value-spec=0
    Init_CAN1_ABM_RearPassengerRH_ODS_Sta: value-spec=0
    Init_CAN1_AirBagFailCmd: value-spec=0
    Init_CAN1_Checksum_ABM1: value-spec=0
    Init_CAN1_CrashOutputSts: value-spec=0
    Init_CAN1_DriverSeatBeltCmd: value-spec=0
    Init_CAN1_LifeCount_ABM1: value-spec=0
    Init_CAN1_PABSwitchCmd: value-spec=0
    Init_CAN1_PsngrSeatBeltCmd: value-spec=0
    Init_CAN1_RCenterSeatBeltCmd: value-spec=0
    Init_CAN1_RDriverSeatBeltCmd: value-spec=0
    Init_CAN1_RPsngrSeatBeltCmd: value-spec=0
    Init_CAN1_TLHPsngrSeatBeltCmd: value-spec=0
    Init_CAN1_TRHPsngrSeatBeltCmd: value-spec=0
    Init_CAN1_DOA_Sta: value-spec=0
    Init_CAN1_EPB1_CS: value-spec=0
    Init_CAN1_EPB1_RC: value-spec=0
    Init_CAN1_EPBCarWashMode: value-spec=0
    Init_CAN1_EPBErrSta: value-spec=0
    Init_CAN1_EPBExtApplyAvail: value-spec=0
    Init_CAN1_EPBExtReleaseAvail: value-spec=0
    Init_CAN1_EPBMsg: value-spec=0
    Init_CAN1_EPBRLampSta: value-spec=0
    Init_CAN1_EPBSta: value-spec=0
    Init_CAN1_EPBStaL: value-spec=0
    Init_CAN1_EPBStaR: value-spec=0
    Init_CAN1_TakeOverReq: value-spec=0
    Init_CAN1_DriIntend: value-spec=0
    Init_CAN1_EPS_AOI_Control: value-spec=0
    Init_CAN1_EPS_AOI_Dis_R: value-spec=0
    Init_CAN1_EPS_CS: value-spec=0
    Init_CAN1_EPS_DMSMode_Sta: value-spec=0
    Init_CAN1_EPS_ESABoostOut_Trq: value-spec=30
    Init_CAN1_EPS_ESAInpBoost_Sta: value-spec=0
    Init_CAN1_EPS_LDW_Activation: value-spec=0
    Init_CAN1_EPS_LDW_Unavailable: value-spec=0
    Init_CAN1_EPS_Pwr_Consumpt: value-spec=0
    Init_CAN1_EPS_Pwr_Consumpt_V: value-spec=1
    Init_CAN1_EPS_Pwr_Limit: value-spec=0
    Init_CAN1_EPS_Pwr_Limit_V: value-spec=1
    Init_CAN1_EPS_RC: value-spec=0
    Init_CAN1_EPS_TOI_Activation: value-spec=0
    Init_CAN1_EPS_TOI_Dis_R: value-spec=0
    Init_CAN1_EPS_TOI_Fault: value-spec=0
    Init_CAN1_EPS_TOI_Unavailable: value-spec=0
    Init_CAN1_EPS_Temp: value-spec=100
    Init_CAN1_EPS_Temp_V: value-spec=1
    Init_CAN1_EPS_VOL: value-spec=0
    Init_CAN1_EPS_VOL_V: value-spec=1
    Init_CAN1_EpasFailed: value-spec=0
    Init_CAN1_SAS_Angle: value-spec=9000
    Init_CAN1_SAS_CAL: value-spec=0
    Init_CAN1_SAS_Speed: value-spec=0
    Init_CAN1_SAS_Speed_Valid: value-spec=0
    Init_CAN1_SAS_V: value-spec=0
    Init_CAN1_Steering_Torque: value-spec=0
    Init_CAN1_Steering_Torque_V: value-spec=1
    Init_CAN1_ABS_Active: value-spec=0
    Init_CAN1_ABS_Failed: value-spec=0
    Init_CAN1_ABS_WnlmpSta: value-spec=0
    Init_CAN1_AVH_Active: value-spec=0
    Init_CAN1_AVH_Failed: value-spec=0
    Init_CAN1_Amber_WnlmpSta: value-spec=0
    Init_CAN1_BTCS_Active: value-spec=0
    Init_CAN1_EBD_Active: value-spec=0
    Init_CAN1_EBD_Failed: value-spec=0
    Init_CAN1_ESC1_CS: value-spec=0
    Init_CAN1_ESC1_RC: value-spec=0
    Init_CAN1_ESC_Active: value-spec=0
    Init_CAN1_ESC_BeepReq: value-spec=0
    Init_CAN1_ESC_EstVehSpd: value-spec=0
    Init_CAN1_ESC_EstVehSpd_V: value-spec=0
    Init_CAN1_ESC_Failed: value-spec=0
    Init_CAN1_ESC_OFF_Status: value-spec=0
    Init_CAN1_ESC_Off_lmpSta: value-spec=0
    Init_CAN1_ESC_TSA_Active: value-spec=0
    Init_CAN1_ESC_WnlmpSta: value-spec=0
    Init_CAN1_ESS_Active: value-spec=0
    Init_CAN1_Fr_PTCS_Active: value-spec=0
    Init_CAN1_FrntAxlTrqReq_Drv: value-spec=10600
    Init_CAN1_GRADE: value-spec=127
    Init_CAN1_HBB_Active: value-spec=0
    Init_CAN1_HBB_Failed: value-spec=0
    Init_CAN1_HDD_Active: value-spec=0
    Init_CAN1_HDD_Failed: value-spec=0
    Init_CAN1_HSA_Active: value-spec=0
    Init_CAN1_HSA_Failed: value-spec=0
    Init_CAN1_LF_PulseCount: value-spec=0
    Init_CAN1_LF_PulseCount_V: value-spec=0
    Init_CAN1_LF_RawWhlSpeed: value-spec=0
    Init_CAN1_LF_RawWhlSpeed_V: value-spec=0
    Init_CAN1_LF_WhlRotDir: value-spec=0
    Init_CAN1_LR_PulseCount: value-spec=0
    Init_CAN1_LR_PulseCount_V: value-spec=0
    Init_CAN1_LR_RawWhlSpeed: value-spec=0
    Init_CAN1_LR_RawWhlSpeed_V: value-spec=0
    Init_CAN1_LR_WhlRotDir: value-spec=0
    Init_CAN1_PBA_Active: value-spec=0
    Init_CAN1_PBA_Failed: value-spec=0
    Init_CAN1_RF_PulseCount: value-spec=0
    Init_CAN1_RF_PulseCount_V: value-spec=0
    Init_CAN1_RF_RawWhlSpeed: value-spec=0
    Init_CAN1_RF_RawWhlSpeed_V: value-spec=0
    Init_CAN1_RF_WhlRotDir: value-spec=0
    Init_CAN1_RR_PulseCount: value-spec=0
    Init_CAN1_RR_PulseCount_V: value-spec=0
    Init_CAN1_RR_RawWhlSpeed: value-spec=0
    Init_CAN1_RR_RawWhlSpeed_V: value-spec=0
    Init_CAN1_RR_WhlRotDir: value-spec=0
    Init_CAN1_RearAxlTrqReq_Drv: value-spec=10600
    Init_CAN1_Red_WnlmpSta: value-spec=0
    Init_CAN1_Rr_PTCS_Active: value-spec=0
    Init_CAN1_SystemVoltage: value-spec=0
    Init_CAN1_TCS_Active: value-spec=0
    Init_CAN1_TCS_Failed: value-spec=0
    Init_CAN1_VehSpeed: value-spec=0
    Init_CAN1_ACCAvail: value-spec=0
    Init_CAN1_AEBAvail: value-spec=0
    Init_CAN1_ActBrkLamp_Sta: value-spec=0
    Init_CAN1_BrkDiscTempSta: value-spec=0
    Init_CAN1_BrkPedalPos: value-spec=0
    Init_CAN1_BrkPedalPos_Sta: value-spec=0
    Init_CAN1_BrkSw_Sta: value-spec=0
    Init_CAN1_BrkSw_V: value-spec=0
    Init_CAN1_DecErrSta: value-spec=0
    Init_CAN1_ESC5_CS: value-spec=0
    Init_CAN1_ESC5_RC: value-spec=0
    Init_CAN1_ESC_ADAS_Sta: value-spec=0
    Init_CAN1_ESC_APS_Sta: value-spec=0
    Init_CAN1_ESC_DriverBrkOverride: value-spec=0
    Init_CAN1_ESC_Standstill: value-spec=0
    Init_CAN1_Fr_RBC_Active: value-spec=0
    Init_CAN1_FrntAxlTrqReq_Brk: value-spec=10600
    Init_CAN1_LatAccel: value-spec=127
    Init_CAN1_LatAccel_V: value-spec=0
    Init_CAN1_LongAccel: value-spec=127
    Init_CAN1_LongAccel_V: value-spec=0
    Init_CAN1_MCPressure: value-spec=97
    Init_CAN1_MCPressure_V: value-spec=0
    Init_CAN1_Meter_Ind_VehSpeed: value-spec=0
    Init_CAN1_RDC_Active: value-spec=0
    Init_CAN1_RearAxlTrqReq_Brk: value-spec=10600
    Init_CAN1_Rr_RBC_Active: value-spec=0
    Init_CAN1_YawRate: value-spec=1000
    Init_CAN1_YawRate_V: value-spec=0
    Init_CAN1_APS_D_FLL: value-spec=0
    Init_CAN1_APS_D_FLR: value-spec=0
    Init_CAN1_APS_D_RLL: value-spec=0
    Init_CAN1_APS_D_RLR: value-spec=0
    Init_CAN1_APS_ExitCondition: value-spec=0
    Init_CAN1_APS_HW_Ver: value-spec=0
    Init_CAN1_APS_Progress_PCT: value-spec=0
    Init_CAN1_APS_RQ_Display: value-spec=0
    Init_CAN1_APS_SW_Ver: value-spec=0
    Init_CAN1_PAS_A_FCL: value-spec=0
    Init_CAN1_PAS_A_FCR: value-spec=0
    Init_CAN1_PAS_A_FML: value-spec=0
    Init_CAN1_PAS_A_FMR: value-spec=0
    Init_CAN1_PAS_A_RCL: value-spec=0
    Init_CAN1_PAS_A_RCR: value-spec=0
    Init_CAN1_PAS_A_RML: value-spec=0
    Init_CAN1_PAS_A_RMR: value-spec=0
    Init_CAN1_PAS_Chime: value-spec=0
    Init_CAN1_PAS_D_FCL: value-spec=0
    Init_CAN1_PAS_D_FCR: value-spec=0
    Init_CAN1_PAS_D_FML: value-spec=0
    Init_CAN1_PAS_D_FMR: value-spec=0
    Init_CAN1_PAS_D_RCL: value-spec=0
    Init_CAN1_PAS_D_RCR: value-spec=0
    Init_CAN1_PAS_D_RML: value-spec=0
    Init_CAN1_PAS_D_RMR: value-spec=0
    Init_CAN1_PAS_Mod_Operation: value-spec=0
    Init_CAN1_PAS_SNSR_Layout: value-spec=0
    Init_CAN1_PAS_Sta_F_Sys: value-spec=0
    Init_CAN1_USS_Sta_FCL: value-spec=0
    Init_CAN1_USS_Sta_FCR: value-spec=0
    Init_CAN1_USS_Sta_FLL: value-spec=0
    Init_CAN1_USS_Sta_FLR: value-spec=0
    Init_CAN1_USS_Sta_FML: value-spec=0
    Init_CAN1_USS_Sta_FMR: value-spec=0
    Init_CAN1_USS_Sta_RCL: value-spec=0
    Init_CAN1_USS_Sta_RCR: value-spec=0
    Init_CAN1_USS_Sta_RLL: value-spec=0
    Init_CAN1_USS_Sta_RLR: value-spec=0
    Init_CAN1_USS_Sta_RML: value-spec=0
    Init_CAN1_USS_Sta_RMR: value-spec=0
    Init_CAN1_APS3_LifeCount: value-spec=0
    Init_CAN1_APS3_checksum: value-spec=0
    Init_CAN1_APSOpenPTG: value-spec=0
    Init_CAN1_APS_DecReq: value-spec=0
    Init_CAN1_APS_DecReq_A: value-spec=0
    Init_CAN1_APS_Req: value-spec=0
    Init_CAN1_APS_Sta_System: value-spec=0
    Init_CAN1_CAAS_Sta: value-spec=0
    Init_CAN1_FDC_APS_Active_Sta: value-spec=0
    Init_CAN1_FDC_APS_CaasActive_Sta: value-spec=0
    Init_CAN1_FDC_APS_CaasCtrlAvail_Sta: value-spec=0
    Init_CAN1_FDC_APS_CaasVMCReqA_Cmd: value-spec=0
    Init_CAN1_FDC_APS_CtrlAvail_Sta: value-spec=0
    Init_CAN1_FDC_APS_ShftPosnReq_Cmd: value-spec=0
    Init_CAN1_FDC_APS_SpeedReq_Cmd: value-spec=0
    Init_CAN1_FDC_APS_VMCReqA_Cmd: value-spec=0
    Init_CAN1_FDC_RAPS_BCMLamp_Cmd: value-spec=0
    Init_CAN1_FDC_RAPS_BCMLockReq_Cmd: value-spec=0
    Init_CAN1_FDC_RAPS_ErrLv1_Flg: value-spec=0
    Init_CAN1_FDC_RAPS_PwrReqAvail_Sta: value-spec=0
    Init_CAN1_FDC_RAPS_PwrReq_Cmd: value-spec=0
    Init_CAN1_FDC_VCU_RAPSErrLv2_Flg: value-spec=0
    Init_CAN1_FDC_VCU_RAPSErrLv3_Flg: value-spec=0
    Init_CAN1_FDC_VMC_APS_Angle_Target: value-spec=0
    Init_CAN1_FDC_VMC_APS_Rq_EPS_Ctrl: value-spec=0
    Init_CAN1_FDC_VMC_APS_V_Rq_EPS_Ctrl: value-spec=0
    Init_CAN1_SPTGDet: value-spec=0
    Init_CAN1_SPTG_Sta: value-spec=0
    Init_CAN1_AllDoorSW: value-spec=0
    Init_CAN1_AntiTheftSeatFold: value-spec=0
    Init_CAN1_AntitheftSta: value-spec=0
    Init_CAN1_BCM_Buzzer_Req: value-spec=0
    Init_CAN1_BCM_DoorLock_Sta: value-spec=0
    Init_CAN1_BrakeLamp: value-spec=0
    Init_CAN1_CTDCtrl: value-spec=0
    Init_CAN1_CTDLockSW: value-spec=0
    Init_CAN1_CTDUnlockSW: value-spec=0
    Init_CAN1_CrashDetd: value-spec=0
    Init_CAN1_Dimmer: value-spec=0
    Init_CAN1_DimmerEN: value-spec=0
    Init_CAN1_DoorLockIND: value-spec=0
    Init_CAN1_DrDoorSW: value-spec=0
    Init_CAN1_Fr_ChargingDoorCtrl: value-spec=0
    Init_CAN1_Fr_FogLamp: value-spec=0
    Init_CAN1_Fr_Wiper_H: value-spec=0
    Init_CAN1_Fr_Wiper_L: value-spec=0
    Init_CAN1_H_Beam: value-spec=0
    Init_CAN1_HazardSW: value-spec=0
    Init_CAN1_HoodSW: value-spec=0
    Init_CAN1_HornCtrl: value-spec=0
    Init_CAN1_LBSD: value-spec=0
    Init_CAN1_LDRL: value-spec=0
    Init_CAN1_LTurnLP: value-spec=0
    Init_CAN1_L_APM_WdwEnable: value-spec=0
    Init_CAN1_L_Beam: value-spec=0
    Init_CAN1_LockSetting: value-spec=0
    Init_CAN1_MirrorCtrl: value-spec=0
    Init_CAN1_MirrorDefog: value-spec=0
    Init_CAN1_PosLamp: value-spec=0
    Init_CAN1_PsDoorSW: value-spec=0
    Init_CAN1_RBSD: value-spec=0
    Init_CAN1_RDRL: value-spec=0
    Init_CAN1_RLDoorSW: value-spec=0
    Init_CAN1_RRDoorSW: value-spec=0
    Init_CAN1_RTurnLP: value-spec=0
    Init_CAN1_ReverseLamp: value-spec=0
    Init_CAN1_RoomLampH: value-spec=0
    Init_CAN1_RoomLampL: value-spec=0
    Init_CAN1_Rr_ChargingDoorCtrl: value-spec=0
    Init_CAN1_Rr_Defog: value-spec=0
    Init_CAN1_Rr_FogLamp: value-spec=0
    Init_CAN1_Rr_Wiper: value-spec=0
    Init_CAN1_TailgateHDSW: value-spec=0
    Init_CAN1_TailgateRemote: value-spec=0
    Init_CAN1_Tailgate_SW: value-spec=0
    Init_CAN1_TrunkRel: value-spec=0
    Init_CAN1_WasherCtrl: value-spec=0
    Init_CAN1_WiperFixMode: value-spec=0
    Init_CAN1_BatteryMode: value-spec=0
    Init_CAN1_CCU_ACLampSts: value-spec=0
    Init_CAN1_CCU_ACMaxLampSts: value-spec=0
    Init_CAN1_CCU_AutoLampSts: value-spec=0
    Init_CAN1_CCU_AutoMidLampSts: value-spec=0
    Init_CAN1_CCU_Dispaly_Request: value-spec=0
    Init_CAN1_CCU_EcoSts: value-spec=0
    Init_CAN1_CCU_FrtOnOffLampSts: value-spec=0
    Init_CAN1_CCU_HEATMaxLampSts: value-spec=0
    Init_CAN1_CCU_RrOnOffLampSts: value-spec=0
    Init_CAN1_CCU_SyncLampSts: value-spec=0
    Init_CAN1_CabinMode: value-spec=15
    Init_CAN1_EDriveMode: value-spec=0
    Init_CAN1_FD_AGS_Cmd: value-spec=0
    Init_CAN1_FD_RecyAuto_Cmd: value-spec=7
    Init_CAN1_Fr_Coolantflow: value-spec=0
    Init_CAN1_Fr_Coolanttemp: value-spec=40
    Init_CAN1_HPThermalRecoveryReq: value-spec=0
    Init_CAN1_Rr_Coolantflow: value-spec=0
    Init_CAN1_Rr_Coolanttemp: value-spec=40
    Init_CAN1_sigAirIntenZon1St: value-spec=0
    Init_CAN1_sigAirIntenZon3St: value-spec=0
    Init_CAN1_sigAmbAirT: value-spec=0
    Init_CAN1_sigCbnAirT: value-spec=0
    Init_CAN1_sigCbnPTCPwrAct: value-spec=0
    Init_CAN1_sigCbnSolarLeft: value-spec=253
    Init_CAN1_sigCbnSolarRight: value-spec=253
    Init_CAN1_sigClmtCmprPwrAct: value-spec=0
    Init_CAN1_sigClntTHvBattOut: value-spec=120
    Init_CAN1_sigDfrstSt: value-spec=0
    Init_CAN1_sigHvacSt: value-spec=0
    Init_CAN1_sigRecircSt: value-spec=0
    Init_CAN1_sigSetTempZon{1..3}St: value-spec=0
    Init_CAN1_sigWindDirZon1St: value-spec=7
    Init_CAN1_sigWindDirZon3St: value-spec=7
    Init_CAN1_CC_Crl_Sta: value-spec=0
    Init_CAN1_Eng_AGSCloseSta: value-spec=0
    Init_CAN1_Eng_ActvDmpDisabSta: value-spec=0
    Init_CAN1_Eng_CoastDwSta: value-spec=0
    Init_CAN1_Eng_PwrLockSta: value-spec=0
    Init_CAN1_HVPwrSta: value-spec=0
    Init_CAN1_LVPwrSta: value-spec=0
    Init_CAN1_MSA_Crl_Sta: value-spec=0
    Init_CAN1_P_Button_Sta: value-spec=0
    Init_CAN1_PrkReq: value-spec=0
    Init_CAN1_PrkReqValid: value-spec=0
    Init_CAN1_PwrSta: value-spec=7
    Init_CAN1_ShiftGearPosn: value-spec=1
    Init_CAN1_VehMalfunLevel: value-spec=0
    Init_CAN1_XWDMode: value-spec=0
    Init_CAN1_ACC_CtrlAvail: value-spec=0
    Init_CAN1_AccPedal_Override: value-spec=0
    Init_CAN1_ActAPSPosn: value-spec=0
    Init_CAN1_CS_VCU2_CAN1: value-spec=0
    Init_CAN1_DriverTq: value-spec=4300
    Init_CAN1_Fr_DriverTq: value-spec=10600
    Init_CAN1_RC_VCU2_CAN1: value-spec=0
    Init_CAN1_Rr_DriverTq: value-spec=10600
    Init_CAN1_VehActPwr: value-spec=600000
    Init_CAN1_CS_VCU3_CAN1: value-spec=0
    Init_CAN1_EquivAccPedalSWSta: value-spec=0
    Init_CAN1_Fr_EDUAvailBrkRgnTq: value-spec=10600
    Init_CAN1_Fr_EDUAvailBrkRgnTqValid: value-spec=0
    Init_CAN1_Fr_EDURealARgnTq: value-spec=5300
    Init_CAN1_Fr_EDURealDrvOrBRgnTq: value-spec=10600
    Init_CAN1_Fr_EDUSpd: value-spec=2000
    Init_CAN1_Fr_EDUSpdValid: value-spec=0
    Init_CAN1_Fr_RgnDecrSta: value-spec=0
    Init_CAN1_Fr_RgnPermSta: value-spec=0
    Init_CAN1_PTCS_PermSta: value-spec=0
    Init_CAN1_RC_VCU3_CAN1: value-spec=0
    Init_CAN1_RgnAbnorSta: value-spec=0
    Init_CAN1_Rr_EDUAvailBrkRgnTq: value-spec=10600
    Init_CAN1_Rr_EDUAvailBrkRgnTqValid: value-spec=0
    Init_CAN1_Rr_EDURealARgnTq: value-spec=5300
    Init_CAN1_Rr_EDURealDrvOrBRgnTq: value-spec=10600
    Init_CAN1_Rr_EDUSpd: value-spec=2000
    Init_CAN1_Rr_EDUSpdValid: value-spec=0
    Init_CAN1_Rr_RgnDecrSta: value-spec=0
    Init_CAN1_Rr_RgnPermSta: value-spec=0
    Init_CAN1_AccCalcuPID: value-spec=0
    Init_CAN1_CCMSA_SpdWar: value-spec=0
    Init_CAN1_DISCReqAcc: value-spec=0
    Init_CAN1_DISC_ButtSta: value-spec=0
    Init_CAN1_DISC_DISCTargetSpd: value-spec=0
    Init_CAN1_DISC_DISCTurn: value-spec=0
    Init_CAN1_DISC_Sta: value-spec=0
    Init_CAN1_FeatArbitrFinal: value-spec=0
    Init_CAN1_FeatArbitrSta: value-spec=0
    Init_CAN1_FeatReqSpd: value-spec=0
    Init_CAN1_FeatSetSpdFinal_raw32: value-spec=0
    Init_CAN1_FrontRearSlipRatioCtrl: value-spec=0
    Init_CAN1_JerkPCT: value-spec=0
    Init_CAN1_LatAccCtrl: value-spec=0
    Init_CAN1_LateralCtrl: value-spec=0
    Init_CAN1_LimitPCT: value-spec=0
    Init_CAN1_MeterIndSpeed_raw32: value-spec=0
    Init_CAN1_RearWhlSlipRatioCtrl: value-spec=0
    Init_CAN1_SPD2ACCAct: value-spec=0
    Init_CAN1_SafetyCtrl: value-spec=0
    Init_CAN1_SingleWhlSlipRatioCtrl: value-spec=0
    Init_CAN1_TimeGapCalcu: value-spec=0
    Init_CAN1_VMC_ACCCtrlAvail: value-spec=0
    Init_CAN1_VMC_AEBCtrlAvail: value-spec=0
    Init_CAN1_VMC_CCCtrlAvail: value-spec=0
    Init_CAN1_VMC_MSACtrlAvail: value-spec=0
    Init_CAN1_VMC_VCU_ACC_CtrlAvail: value-spec=0
    Init_CAN1_VMC_VCU_APSCtrlAvail_flg: value-spec=0
    Init_CAN1_VMC_VCU_AccPedal_Override: value-spec=0
    Init_CAN1_VMC_VCU_CC_Crl_Sta: value-spec=0
    Init_CAN1_VMC_VCU_MSA_Crl_Sta: value-spec=0
    Init_CAN1_VehicleSpeed_kph: value-spec=0
    Init_CAN1_VehicleSpeed_mph: value-spec=0
    Init_CAN1_FDC_VMC_RWS_Actv_Sta: value-spec=0
    Init_CAN1_FDC_VMC_RWS_Dfctv_Sta: value-spec=0
    Init_CAN1_FDC_VMC_RWS_PositionReq_Cmd: value-spec=32767
    Init_CAN1_FDC_VMC_SteerFaultReq_Cmd: value-spec=0
    Init_CAN1_BMS_READY: value-spec=0
    Init_CAN1_Fr_TMSpd: value-spec=18000
    Init_CAN1_Rr_TMSpd: value-spec=18000
    Init_CAN1_ESC_SW_Cmd: value-spec=0
    Init_CAN1_Roll_Eng_Mode: value-spec=0
    Init_CAN1_Roll_Mode_SW_Cmd: value-spec=0
    Init_CAN1_TCS_SW_Cmd: value-spec=0
    Init_CAN1_FDC_VMC_AngCtrlTqWtGn: value-spec=0
    Init_CAN1_FDC_VMC_DMSMode_Cmd: value-spec=0
    Init_CAN1_FDC_VMC_DrInpTqBstAct: value-spec=0
    Init_CAN1_FDC_VMC_DrInpTqBstGn: value-spec=0
    Init_CAN1_FDC_VMC_MaxAngCtrlOutTqLim: value-spec=0
    Init_CAN1_VMC_ACC_ComfortBandLower: value-spec=0
    Init_CAN1_VMC_ACC_ComfortBandUpper: value-spec=0
    Init_CAN1_VMC_ACC_JerkLowerLInit: value-spec=0
    Init_CAN1_VMC_ACC_JerkUpperLInit: value-spec=0
    Init_CAN1_VMC_ACC_RequiredAccel: value-spec=0
    Init_CAN1_VMC_ACC_VehHoldReq: value-spec=0
    Init_CAN1_VMC_ADAS_ACC_Sta: value-spec=0
    Init_CAN1_VMC_ADAS_AEBReq: value-spec=0
    Init_CAN1_VMC_ADAS_AEB_Sta: value-spec=0
    Init_CAN1_VMC_ADAS_DBSReq: value-spec=0
    Init_CAN1_VMC_ADAS_FaultSta: value-spec=0
    Init_CAN1_VMC_AEB_VehHoldReq: value-spec=0
    Init_CAN1_VMC_FCM1_Checksum: value-spec=0
    Init_CAN1_VMC_FCM1_LifeCount: value-spec=0
    Init_CAN1_VMC_FCM_LDW_Fault: value-spec=0
    Init_CAN1_VMC_FCM_LDW_Request: value-spec=0
    Init_CAN1_VMC_FCM_LKA_StrToqReq: value-spec=0
    Init_CAN1_VMC_FCM_LKA_TOIAct: value-spec=0
    Init_CAN1_VMC_FCM_LKA_TOIFault: value-spec=0
    Init_CAN1_LowBrakeFluid_Sta: value-spec=0
    Init_CAN1_eBST_AmberWnlmpSta: value-spec=0
    Init_CAN1_eBST_BeepReq: value-spec=0
    Init_CAN1_eBST_RedWnlmpSta: value-spec=0
    Init_CAN1_SG_ABM1: value-spec=fields=[Init_CAN1_ABM_Passenger_ODS_Sta, Init_CAN1_ABM_RearPassengerCTR_ODS_Sta, Init_CAN1_ABM_RearPassengerLH_ODS_Sta, Init_CAN1_ABM_RearPassengerRH_ODS_Sta, Init_CAN1_AirBagFailCmd, Init_CAN1_Checksum_ABM1, Init_CAN1_CrashOutputSts, Init_CAN1_DriverSeatBeltCmd, Init_CAN1_LifeCount_ABM1, Init_CAN1_PABSwitchCmd, Init_CAN1_PsngrSeatBeltCmd, Init_CAN1_RCenterSeatBeltCmd, Init_CAN1_RDriverSeatBeltCmd, Init_CAN1_RPsngrSeatBeltCmd, Init_CAN1_TLHPsngrSeatBeltCmd, Init_CAN1_TRHPsngrSeatBeltCmd]
    Init_CAN1_SG_EPB1: value-spec=fields=[Init_CAN1_DOA_Sta, Init_CAN1_EPB1_CS, Init_CAN1_EPB1_RC, Init_CAN1_EPBCarWashMode, Init_CAN1_EPBErrSta, Init_CAN1_EPBExtApplyAvail, Init_CAN1_EPBExtReleaseAvail, Init_CAN1_EPBMsg, Init_CAN1_EPBRLampSta, Init_CAN1_EPBSta, Init_CAN1_EPBStaL, Init_CAN1_EPBStaR, Init_CAN1_TakeOverReq]
    Init_CAN1_SG_EPS1: value-spec=fields=[Init_CAN1_DriIntend, Init_CAN1_EPS_AOI_Control, Init_CAN1_EPS_AOI_Dis_R, Init_CAN1_EPS_CS, Init_CAN1_EPS_DMSMode_Sta, Init_CAN1_EPS_ESABoostOut_Trq, Init_CAN1_EPS_ESAInpBoost_Sta, Init_CAN1_EPS_LDW_Activation, Init_CAN1_EPS_LDW_Unavailable, Init_CAN1_EPS_Pwr_Consumpt, Init_CAN1_EPS_Pwr_Consumpt_V, Init_CAN1_EPS_Pwr_Limit, Init_CAN1_EPS_Pwr_Limit_V, Init_CAN1_EPS_RC, Init_CAN1_EPS_TOI_Activation, Init_CAN1_EPS_TOI_Dis_R, Init_CAN1_EPS_TOI_Fault, Init_CAN1_EPS_TOI_Unavailable, Init_CAN1_EPS_Temp, Init_CAN1_EPS_Temp_V, Init_CAN1_EPS_VOL, Init_CAN1_EPS_VOL_V, Init_CAN1_EpasFailed, Init_CAN1_SAS_Angle, Init_CAN1_SAS_CAL, Init_CAN1_SAS_Speed, Init_CAN1_SAS_Speed_Valid, Init_CAN1_SAS_V, Init_CAN1_Steering_Torque, Init_CAN1_Steering_Torque_V]
    Init_CAN1_SG_ESC1: value-spec=fields=[Init_CAN1_ABS_Active, Init_CAN1_ABS_Failed, Init_CAN1_ABS_WnlmpSta, Init_CAN1_AVH_Active, Init_CAN1_AVH_Failed, Init_CAN1_Amber_WnlmpSta, Init_CAN1_BTCS_Active, Init_CAN1_EBD_Active, Init_CAN1_EBD_Failed, Init_CAN1_ESC1_CS, Init_CAN1_ESC1_RC, Init_CAN1_ESC_Active, Init_CAN1_ESC_BeepReq, Init_CAN1_ESC_EstVehSpd, Init_CAN1_ESC_EstVehSpd_V, Init_CAN1_ESC_Failed, Init_CAN1_ESC_OFF_Status, Init_CAN1_ESC_Off_lmpSta, Init_CAN1_ESC_TSA_Active, Init_CAN1_ESC_WnlmpSta, Init_CAN1_ESS_Active, Init_CAN1_Fr_PTCS_Active, Init_CAN1_FrntAxlTrqReq_Drv, Init_CAN1_GRADE, Init_CAN1_HBB_Active, Init_CAN1_HBB_Failed, Init_CAN1_HDD_Active, Init_CAN1_HDD_Failed, Init_CAN1_HSA_Active, Init_CAN1_HSA_Failed, Init_CAN1_LF_PulseCount, Init_CAN1_LF_PulseCount_V, Init_CAN1_LF_RawWhlSpeed, Init_CAN1_LF_RawWhlSpeed_V, Init_CAN1_LF_WhlRotDir, Init_CAN1_LR_PulseCount, Init_CAN1_LR_PulseCount_V, Init_CAN1_LR_RawWhlSpeed, Init_CAN1_LR_RawWhlSpeed_V, Init_CAN1_LR_WhlRotDir, Init_CAN1_PBA_Active, Init_CAN1_PBA_Failed, Init_CAN1_RF_PulseCount, Init_CAN1_RF_PulseCount_V, Init_CAN1_RF_RawWhlSpeed, Init_CAN1_RF_RawWhlSpeed_V, Init_CAN1_RF_WhlRotDir, Init_CAN1_RR_PulseCount, Init_CAN1_RR_PulseCount_V, Init_CAN1_RR_RawWhlSpeed, Init_CAN1_RR_RawWhlSpeed_V, Init_CAN1_RR_WhlRotDir, Init_CAN1_RearAxlTrqReq_Drv, Init_CAN1_Red_WnlmpSta, Init_CAN1_Rr_PTCS_Active, Init_CAN1_SystemVoltage, Init_CAN1_TCS_Active, Init_CAN1_TCS_Failed, Init_CAN1_VehSpeed]
    Init_CAN1_SG_ESC5: value-spec=fields=[Init_CAN1_ACCAvail, Init_CAN1_AEBAvail, Init_CAN1_ActBrkLamp_Sta, Init_CAN1_BrkDiscTempSta, Init_CAN1_BrkPedalPos, Init_CAN1_BrkPedalPos_Sta, Init_CAN1_BrkSw_Sta, Init_CAN1_BrkSw_V, Init_CAN1_DecErrSta, Init_CAN1_ESC5_CS, Init_CAN1_ESC5_RC, Init_CAN1_ESC_ADAS_Sta, Init_CAN1_ESC_APS_Sta, Init_CAN1_ESC_DriverBrkOverride, Init_CAN1_ESC_Standstill, Init_CAN1_Fr_RBC_Active, Init_CAN1_FrntAxlTrqReq_Brk, Init_CAN1_LatAccel, Init_CAN1_LatAccel_V, Init_CAN1_LongAccel, Init_CAN1_LongAccel_V, Init_CAN1_MCPressure, Init_CAN1_MCPressure_V, Init_CAN1_Meter_Ind_VehSpeed, Init_CAN1_RDC_Active, Init_CAN1_RearAxlTrqReq_Brk, Init_CAN1_Rr_RBC_Active, Init_CAN1_YawRate, Init_CAN1_YawRate_V]
    Init_CAN1_SG_FD1_APS2: value-spec=fields=[Init_CAN1_APS_D_FLL, Init_CAN1_APS_D_FLR, Init_CAN1_APS_D_RLL, Init_CAN1_APS_D_RLR, Init_CAN1_APS_ExitCondition, Init_CAN1_APS_HW_Ver, Init_CAN1_APS_Progress_PCT, Init_CAN1_APS_RQ_Display, Init_CAN1_APS_SW_Ver, Init_CAN1_PAS_A_FCL, Init_CAN1_PAS_A_FCR, Init_CAN1_PAS_A_FML, Init_CAN1_PAS_A_FMR, Init_CAN1_PAS_A_RCL, Init_CAN1_PAS_A_RCR, Init_CAN1_PAS_A_RML, Init_CAN1_PAS_A_RMR, Init_CAN1_PAS_Chime, Init_CAN1_PAS_D_FCL, Init_CAN1_PAS_D_FCR, Init_CAN1_PAS_D_FML, Init_CAN1_PAS_D_FMR, Init_CAN1_PAS_D_RCL, Init_CAN1_PAS_D_RCR, Init_CAN1_PAS_D_RML, Init_CAN1_PAS_D_RMR, Init_CAN1_PAS_Mod_Operation, Init_CAN1_PAS_SNSR_Layout, Init_CAN1_PAS_Sta_F_Sys, Init_CAN1_USS_Sta_FCL, Init_CAN1_USS_Sta_FCR, Init_CAN1_USS_Sta_FLL, Init_CAN1_USS_Sta_FLR, Init_CAN1_USS_Sta_FML, Init_CAN1_USS_Sta_FMR, Init_CAN1_USS_Sta_RCL, Init_CAN1_USS_Sta_RCR, Init_CAN1_USS_Sta_RLL, Init_CAN1_USS_Sta_RLR, Init_CAN1_USS_Sta_RML, Init_CAN1_USS_Sta_RMR]
    Init_CAN1_SG_FD1_APS3: value-spec=fields=[Init_CAN1_APS3_LifeCount, Init_CAN1_APS3_checksum, Init_CAN1_APSOpenPTG, Init_CAN1_APS_DecReq, Init_CAN1_APS_DecReq_A, Init_CAN1_APS_Req, Init_CAN1_APS_Sta_System, Init_CAN1_CAAS_Sta, Init_CAN1_FDC_APS_Active_Sta, Init_CAN1_FDC_APS_CaasActive_Sta, Init_CAN1_FDC_APS_CaasCtrlAvail_Sta, Init_CAN1_FDC_APS_CaasVMCReqA_Cmd, Init_CAN1_FDC_APS_CtrlAvail_Sta, Init_CAN1_FDC_APS_ShftPosnReq_Cmd, Init_CAN1_FDC_APS_SpeedReq_Cmd, Init_CAN1_FDC_APS_VMCReqA_Cmd, Init_CAN1_FDC_RAPS_BCMLamp_Cmd, Init_CAN1_FDC_RAPS_BCMLockReq_Cmd, Init_CAN1_FDC_RAPS_ErrLv1_Flg, Init_CAN1_FDC_RAPS_PwrReqAvail_Sta, Init_CAN1_FDC_RAPS_PwrReq_Cmd, Init_CAN1_FDC_VCU_RAPSErrLv2_Flg, Init_CAN1_FDC_VCU_RAPSErrLv3_Flg, Init_CAN1_FDC_VMC_APS_Angle_Target, Init_CAN1_FDC_VMC_APS_Rq_EPS_Ctrl, Init_CAN1_FDC_VMC_APS_V_Rq_EPS_Ctrl, Init_CAN1_SPTGDet, Init_CAN1_SPTG_Sta]
    Init_CAN1_SG_FD1_BCM1: value-spec=fields=[Init_CAN1_AllDoorSW, Init_CAN1_AntiTheftSeatFold, Init_CAN1_AntitheftSta, Init_CAN1_BCM_Buzzer_Req, Init_CAN1_BCM_DoorLock_Sta, Init_CAN1_BrakeLamp, Init_CAN1_CTDCtrl, Init_CAN1_CTDLockSW, Init_CAN1_CTDUnlockSW, Init_CAN1_CrashDetd, Init_CAN1_Dimmer, Init_CAN1_DimmerEN, Init_CAN1_DoorLockIND, Init_CAN1_DrDoorSW, Init_CAN1_Fr_ChargingDoorCtrl, Init_CAN1_Fr_FogLamp, Init_CAN1_Fr_Wiper_H, Init_CAN1_Fr_Wiper_L, Init_CAN1_H_Beam, Init_CAN1_HazardSW, Init_CAN1_HoodSW, Init_CAN1_HornCtrl, Init_CAN1_LBSD, Init_CAN1_LDRL, Init_CAN1_LTurnLP, Init_CAN1_L_APM_WdwEnable, Init_CAN1_L_Beam, Init_CAN1_LockSetting, Init_CAN1_MirrorCtrl, Init_CAN1_MirrorDefog, Init_CAN1_PosLamp, Init_CAN1_PsDoorSW, Init_CAN1_RBSD, Init_CAN1_RDRL, Init_CAN1_RLDoorSW, Init_CAN1_RRDoorSW, Init_CAN1_RTurnLP, Init_CAN1_ReverseLamp, Init_CAN1_RoomLampH, Init_CAN1_RoomLampL, Init_CAN1_Rr_ChargingDoorCtrl, Init_CAN1_Rr_Defog, Init_CAN1_Rr_FogLamp, Init_CAN1_Rr_Wiper, Init_CAN1_TailgateHDSW, Init_CAN1_TailgateRemote, Init_CAN1_Tailgate_SW, Init_CAN1_TrunkRel, Init_CAN1_WasherCtrl, Init_CAN1_WiperFixMode]
    Init_CAN1_SG_FD1_THCM1: value-spec=fields=[Init_CAN1_BatteryMode, Init_CAN1_CCU_ACLampSts, Init_CAN1_CCU_ACMaxLampSts, Init_CAN1_CCU_AutoLampSts, Init_CAN1_CCU_AutoMidLampSts, Init_CAN1_CCU_Dispaly_Request, Init_CAN1_CCU_EcoSts, Init_CAN1_CCU_FrtOnOffLampSts, Init_CAN1_CCU_HEATMaxLampSts, Init_CAN1_CCU_RrOnOffLampSts, Init_CAN1_CCU_SyncLampSts, Init_CAN1_CabinMode, Init_CAN1_EDriveMode, Init_CAN1_FD_AGS_Cmd, Init_CAN1_FD_RecyAuto_Cmd, Init_CAN1_Fr_Coolantflow, Init_CAN1_Fr_Coolanttemp, Init_CAN1_HPThermalRecoveryReq, Init_CAN1_Rr_Coolantflow, Init_CAN1_Rr_Coolanttemp, Init_CAN1_sigAirIntenZon1St, Init_CAN1_sigAirIntenZon3St, Init_CAN1_sigAmbAirT, Init_CAN1_sigCbnAirT, Init_CAN1_sigCbnPTCPwrAct, Init_CAN1_sigCbnSolarLeft, Init_CAN1_sigCbnSolarRight, Init_CAN1_sigClmtCmprPwrAct, Init_CAN1_sigClntTHvBattOut, Init_CAN1_sigDfrstSt, Init_CAN1_sigHvacSt, Init_CAN1_sigRecircSt, Init_CAN1_sigSetTempZon1St, Init_CAN1_sigSetTempZon2St, Init_CAN1_sigSetTempZon3St, Init_CAN1_sigWindDirZon1St, Init_CAN1_sigWindDirZon3St]
    Init_CAN1_SG_FD1_VCU1: value-spec=fields=[Init_CAN1_CC_Crl_Sta, Init_CAN1_Eng_AGSCloseSta, Init_CAN1_Eng_ActvDmpDisabSta, Init_CAN1_Eng_CoastDwSta, Init_CAN1_Eng_PwrLockSta, Init_CAN1_HVPwrSta, Init_CAN1_LVPwrSta, Init_CAN1_MSA_Crl_Sta, Init_CAN1_P_Button_Sta, Init_CAN1_PrkReq, Init_CAN1_PrkReqValid, Init_CAN1_PwrSta, Init_CAN1_ShiftGearPosn, Init_CAN1_VehMalfunLevel, Init_CAN1_XWDMode]
    Init_CAN1_SG_FD1_VCU2: value-spec=fields=[Init_CAN1_ACC_CtrlAvail, Init_CAN1_AccPedal_Override, Init_CAN1_ActAPSPosn, Init_CAN1_CS_VCU2_CAN1, Init_CAN1_DriverTq, Init_CAN1_Fr_DriverTq, Init_CAN1_RC_VCU2_CAN1, Init_CAN1_Rr_DriverTq, Init_CAN1_VehActPwr]
    Init_CAN1_SG_FD1_VCU3: value-spec=fields=[Init_CAN1_CS_VCU3_CAN1, Init_CAN1_EquivAccPedalSWSta, Init_CAN1_Fr_EDUAvailBrkRgnTq, Init_CAN1_Fr_EDUAvailBrkRgnTqValid, Init_CAN1_Fr_EDURealARgnTq, Init_CAN1_Fr_EDURealDrvOrBRgnTq, Init_CAN1_Fr_EDUSpd, Init_CAN1_Fr_EDUSpdValid, Init_CAN1_Fr_RgnDecrSta, Init_CAN1_Fr_RgnPermSta, Init_CAN1_PTCS_PermSta, Init_CAN1_RC_VCU3_CAN1, Init_CAN1_RgnAbnorSta, Init_CAN1_Rr_EDUAvailBrkRgnTq, Init_CAN1_Rr_EDUAvailBrkRgnTqValid, Init_CAN1_Rr_EDURealARgnTq, Init_CAN1_Rr_EDURealDrvOrBRgnTq, Init_CAN1_Rr_EDUSpd, Init_CAN1_Rr_EDUSpdValid, Init_CAN1_Rr_RgnDecrSta, Init_CAN1_Rr_RgnPermSta]
    Init_CAN1_SG_FD1_VMC1: value-spec=fields=[Init_CAN1_AccCalcuPID, Init_CAN1_CCMSA_SpdWar, Init_CAN1_DISCReqAcc, Init_CAN1_DISC_ButtSta, Init_CAN1_DISC_DISCTargetSpd, Init_CAN1_DISC_DISCTurn, Init_CAN1_DISC_Sta, Init_CAN1_FeatArbitrFinal, Init_CAN1_FeatArbitrSta, Init_CAN1_FeatReqSpd, Init_CAN1_FeatSetSpdFinal_raw32, Init_CAN1_FrontRearSlipRatioCtrl, Init_CAN1_JerkPCT, Init_CAN1_LatAccCtrl, Init_CAN1_LateralCtrl, Init_CAN1_LimitPCT, Init_CAN1_MeterIndSpeed_raw32, Init_CAN1_RearWhlSlipRatioCtrl, Init_CAN1_SPD2ACCAct, Init_CAN1_SafetyCtrl, Init_CAN1_SingleWhlSlipRatioCtrl, Init_CAN1_TimeGapCalcu, Init_CAN1_VMC_ACCCtrlAvail, Init_CAN1_VMC_AEBCtrlAvail, Init_CAN1_VMC_CCCtrlAvail, Init_CAN1_VMC_MSACtrlAvail, Init_CAN1_VMC_VCU_ACC_CtrlAvail, Init_CAN1_VMC_VCU_APSCtrlAvail_flg, Init_CAN1_VMC_VCU_AccPedal_Override, Init_CAN1_VMC_VCU_CC_Crl_Sta, Init_CAN1_VMC_VCU_MSA_Crl_Sta, Init_CAN1_VehicleSpeed_kph, Init_CAN1_VehicleSpeed_mph]
    Init_CAN1_SG_FD1_VMC2: value-spec=fields=[Init_CAN1_FDC_VMC_RWS_Actv_Sta, Init_CAN1_FDC_VMC_RWS_Dfctv_Sta, Init_CAN1_FDC_VMC_RWS_PositionReq_Cmd, Init_CAN1_FDC_VMC_SteerFaultReq_Cmd]
    Init_CAN1_SG_GW1_CE100_0: value-spec=fields=[Init_CAN1_BMS_READY, Init_CAN1_Fr_TMSpd, Init_CAN1_Rr_TMSpd]
    Init_CAN1_SG_GW1_CE200_0: value-spec=fields=[Init_CAN1_ESC_SW_Cmd, Init_CAN1_Roll_Eng_Mode, Init_CAN1_Roll_Mode_SW_Cmd, Init_CAN1_TCS_SW_Cmd]
    Init_CAN1_SG_VMC_FCM1: value-spec=fields=[Init_CAN1_FDC_VMC_AngCtrlTqWtGn, Init_CAN1_FDC_VMC_DMSMode_Cmd, Init_CAN1_FDC_VMC_DrInpTqBstAct, Init_CAN1_FDC_VMC_DrInpTqBstGn, Init_CAN1_FDC_VMC_MaxAngCtrlOutTqLim, Init_CAN1_VMC_ACC_ComfortBandLower, Init_CAN1_VMC_ACC_ComfortBandUpper, Init_CAN1_VMC_ACC_JerkLowerLInit, Init_CAN1_VMC_ACC_JerkUpperLInit, Init_CAN1_VMC_ACC_RequiredAccel, Init_CAN1_VMC_ACC_VehHoldReq, Init_CAN1_VMC_ADAS_ACC_Sta, Init_CAN1_VMC_ADAS_AEBReq, Init_CAN1_VMC_ADAS_AEB_Sta, Init_CAN1_VMC_ADAS_DBSReq, Init_CAN1_VMC_ADAS_FaultSta, Init_CAN1_VMC_AEB_VehHoldReq, Init_CAN1_VMC_FCM1_Checksum, Init_CAN1_VMC_FCM1_LifeCount, Init_CAN1_VMC_FCM_LDW_Fault, Init_CAN1_VMC_FCM_LDW_Request, Init_CAN1_VMC_FCM_LKA_StrToqReq, Init_CAN1_VMC_FCM_LKA_TOIAct, Init_CAN1_VMC_FCM_LKA_TOIFault]
    Init_CAN1_SG_eBST1: value-spec=fields=[Init_CAN1_LowBrakeFluid_Sta, Init_CAN1_eBST_AmberWnlmpSta, Init_CAN1_eBST_BeepReq, Init_CAN1_eBST_RedWnlmpSta]
package /CAN1/ImplementationDataTypes
  18 x impl type, all with category=STRUCTURE:
    DT_CAN1_SG_ABM1
      16 x element, all with category=TYPE_REFERENCE, implementation-data-type=uint8:
        CAN1_ABM_Passenger_ODS_Sta
        CAN1_ABM_RearPassengerCTR_ODS_Sta
        CAN1_ABM_RearPassengerLH_ODS_Sta
        CAN1_ABM_RearPassengerRH_ODS_Sta
        CAN1_AirBagFailCmd
        CAN1_Checksum_ABM1
        CAN1_CrashOutputSts
        CAN1_DriverSeatBeltCmd
        CAN1_LifeCount_ABM1
        CAN1_PABSwitchCmd
        CAN1_PsngrSeatBeltCmd
        CAN1_RCenterSeatBeltCmd
        CAN1_RDriverSeatBeltCmd
        CAN1_RPsngrSeatBeltCmd
        CAN1_TLHPsngrSeatBeltCmd
        CAN1_TRHPsngrSeatBeltCmd
    DT_CAN1_SG_EPB1
      13 x element, all with category=TYPE_REFERENCE, implementation-data-type=uint8:
        CAN1_DOA_Sta
        CAN1_EPB1_CS
        CAN1_EPB1_RC
        CAN1_EPBCarWashMode
        CAN1_EPBErrSta
        CAN1_EPBExtApplyAvail
        CAN1_EPBExtReleaseAvail
        CAN1_EPBMsg
        CAN1_EPBRLampSta
        CAN1_EPBSta
        CAN1_EPBStaL
        CAN1_EPBStaR
        CAN1_TakeOverReq
    DT_CAN1_SG_EPS1
      30 x element, all with category=TYPE_REFERENCE:
        CAN1_DriIntend: implementation-data-type=uint8
        CAN1_EPS_AOI_Control: implementation-data-type=uint8
        CAN1_EPS_AOI_Dis_R: implementation-data-type=uint8
        CAN1_EPS_CS: implementation-data-type=uint8
        CAN1_EPS_DMSMode_Sta: implementation-data-type=uint8
        CAN1_EPS_ESABoostOut_Trq: implementation-data-type=uint8
        CAN1_EPS_ESAInpBoost_Sta: implementation-data-type=uint8
        CAN1_EPS_LDW_Activation: implementation-data-type=uint8
        CAN1_EPS_LDW_Unavailable: implementation-data-type=uint8
        CAN1_EPS_Pwr_Consumpt: implementation-data-type=uint16
        CAN1_EPS_Pwr_Consumpt_V: implementation-data-type=uint8
        CAN1_EPS_Pwr_Limit: implementation-data-type=uint16
        CAN1_EPS_Pwr_Limit_V: implementation-data-type=uint8
        CAN1_EPS_RC: implementation-data-type=uint8
        CAN1_EPS_TOI_Activation: implementation-data-type=uint8
        CAN1_EPS_TOI_Dis_R: implementation-data-type=uint8
        CAN1_EPS_TOI_Fault: implementation-data-type=uint8
        CAN1_EPS_TOI_Unavailable: implementation-data-type=uint8
        CAN1_EPS_Temp: implementation-data-type=uint8
        CAN1_EPS_Temp_V: implementation-data-type=uint8
        CAN1_EPS_VOL: implementation-data-type=uint8
        CAN1_EPS_VOL_V: implementation-data-type=uint8
        CAN1_EpasFailed: implementation-data-type=uint8
        CAN1_SAS_Angle: implementation-data-type=uint16
        CAN1_SAS_CAL: implementation-data-type=uint8
        CAN1_SAS_Speed: implementation-data-type=uint8
        CAN1_SAS_Speed_Valid: implementation-data-type=uint8
        CAN1_SAS_V: implementation-data-type=uint8
        CAN1_Steering_Torque: implementation-data-type=uint16
        CAN1_Steering_Torque_V: implementation-data-type=uint8
    DT_CAN1_SG_ESC1
      59 x element, all with category=TYPE_REFERENCE:
        CAN1_ABS_Active: implementation-data-type=uint8
        CAN1_ABS_Failed: implementation-data-type=uint8
        CAN1_ABS_WnlmpSta: implementation-data-type=uint8
        CAN1_AVH_Active: implementation-data-type=uint8
        CAN1_AVH_Failed: implementation-data-type=uint8
        CAN1_Amber_WnlmpSta: implementation-data-type=uint8
        CAN1_BTCS_Active: implementation-data-type=uint8
        CAN1_EBD_Active: implementation-data-type=uint8
        CAN1_EBD_Failed: implementation-data-type=uint8
        CAN1_ESC1_CS: implementation-data-type=uint8
        CAN1_ESC1_RC: implementation-data-type=uint8
        CAN1_ESC_Active: implementation-data-type=uint8
        CAN1_ESC_BeepReq: implementation-data-type=uint8
        CAN1_ESC_EstVehSpd: implementation-data-type=uint16
        CAN1_ESC_EstVehSpd_V: implementation-data-type=uint8
        CAN1_ESC_Failed: implementation-data-type=uint8
        CAN1_ESC_OFF_Status: implementation-data-type=uint8
        CAN1_ESC_Off_lmpSta: implementation-data-type=uint8
        CAN1_ESC_TSA_Active: implementation-data-type=uint8
        CAN1_ESC_WnlmpSta: implementation-data-type=uint8
        CAN1_ESS_Active: implementation-data-type=uint8
        CAN1_Fr_PTCS_Active: implementation-data-type=uint8
        CAN1_FrntAxlTrqReq_Drv: implementation-data-type=uint16
        CAN1_GRADE: implementation-data-type=uint8
        CAN1_HBB_Active: implementation-data-type=uint8
        CAN1_HBB_Failed: implementation-data-type=uint8
        CAN1_HDD_Active: implementation-data-type=uint8
        CAN1_HDD_Failed: implementation-data-type=uint8
        CAN1_HSA_Active: implementation-data-type=uint8
        CAN1_HSA_Failed: implementation-data-type=uint8
        CAN1_LF_PulseCount: implementation-data-type=uint8
        CAN1_LF_PulseCount_V: implementation-data-type=uint8
        CAN1_LF_RawWhlSpeed: implementation-data-type=uint16
        CAN1_LF_RawWhlSpeed_V: implementation-data-type=uint8
        CAN1_LF_WhlRotDir: implementation-data-type=uint8
        CAN1_LR_PulseCount: implementation-data-type=uint8
        CAN1_LR_PulseCount_V: implementation-data-type=uint8
        CAN1_LR_RawWhlSpeed: implementation-data-type=uint16
        CAN1_LR_RawWhlSpeed_V: implementation-data-type=uint8
        CAN1_LR_WhlRotDir: implementation-data-type=uint8
        CAN1_PBA_Active: implementation-data-type=uint8
        CAN1_PBA_Failed: implementation-data-type=uint8
        CAN1_RF_PulseCount: implementation-data-type=uint8
        CAN1_RF_PulseCount_V: implementation-data-type=uint8
        CAN1_RF_RawWhlSpeed: implementation-data-type=uint16
        CAN1_RF_RawWhlSpeed_V: implementation-data-type=uint8
        CAN1_RF_WhlRotDir: implementation-data-type=uint8
        CAN1_RR_PulseCount: implementation-data-type=uint8
        CAN1_RR_PulseCount_V: implementation-data-type=uint8
        CAN1_RR_RawWhlSpeed: implementation-data-type=uint16
        CAN1_RR_RawWhlSpeed_V: implementation-data-type=uint8
        CAN1_RR_WhlRotDir: implementation-data-type=uint8
        CAN1_RearAxlTrqReq_Drv: implementation-data-type=uint16
        CAN1_Red_WnlmpSta: implementation-data-type=uint8
        CAN1_Rr_PTCS_Active: implementation-data-type=uint8
        CAN1_SystemVoltage: implementation-data-type=uint8
        CAN1_TCS_Active: implementation-data-type=uint8
        CAN1_TCS_Failed: implementation-data-type=uint8
        CAN1_VehSpeed: implementation-data-type=uint16
    DT_CAN1_SG_ESC5
      29 x element, all with category=TYPE_REFERENCE:
        CAN1_ACCAvail: implementation-data-type=uint8
        CAN1_AEBAvail: implementation-data-type=uint8
        CAN1_ActBrkLamp_Sta: implementation-data-type=uint8
        CAN1_BrkDiscTempSta: implementation-data-type=uint8
        CAN1_BrkPedalPos: implementation-data-type=uint8
        CAN1_BrkPedalPos_Sta: implementation-data-type=uint8
        CAN1_BrkSw_Sta: implementation-data-type=uint8
        CAN1_BrkSw_V: implementation-data-type=uint8
        CAN1_DecErrSta: implementation-data-type=uint8
        CAN1_ESC5_CS: implementation-data-type=uint8
        CAN1_ESC5_RC: implementation-data-type=uint8
        CAN1_ESC_ADAS_Sta: implementation-data-type=uint8
        CAN1_ESC_APS_Sta: implementation-data-type=uint8
        CAN1_ESC_DriverBrkOverride: implementation-data-type=uint8
        CAN1_ESC_Standstill: implementation-data-type=uint8
        CAN1_Fr_RBC_Active: implementation-data-type=uint8
        CAN1_FrntAxlTrqReq_Brk: implementation-data-type=uint16
        CAN1_LatAccel: implementation-data-type=uint8
        CAN1_LatAccel_V: implementation-data-type=uint8
        CAN1_LongAccel: implementation-data-type=uint8
        CAN1_LongAccel_V: implementation-data-type=uint8
        CAN1_MCPressure: implementation-data-type=uint16
        CAN1_MCPressure_V: implementation-data-type=uint8
        CAN1_Meter_Ind_VehSpeed: implementation-data-type=uint16
        CAN1_RDC_Active: implementation-data-type=uint8
        CAN1_RearAxlTrqReq_Brk: implementation-data-type=uint16
        CAN1_Rr_RBC_Active: implementation-data-type=uint8
        CAN1_YawRate: implementation-data-type=uint16
        CAN1_YawRate_V: implementation-data-type=uint8
    DT_CAN1_SG_FD1_APS2
      41 x element, all with category=TYPE_REFERENCE:
        CAN1_APS_D_FLL: implementation-data-type=uint16
        CAN1_APS_D_FLR: implementation-data-type=uint16
        CAN1_APS_D_RLL: implementation-data-type=uint16
        CAN1_APS_D_RLR: implementation-data-type=uint16
        CAN1_APS_ExitCondition: implementation-data-type=uint8
        CAN1_APS_HW_Ver: implementation-data-type=uint8
        CAN1_APS_Progress_PCT: implementation-data-type=uint8
        CAN1_APS_RQ_Display: implementation-data-type=uint8
        CAN1_APS_SW_Ver: implementation-data-type=uint8
        CAN1_PAS_A_FCL: implementation-data-type=uint8
        CAN1_PAS_A_FCR: implementation-data-type=uint8
        CAN1_PAS_A_FML: implementation-data-type=uint8
        CAN1_PAS_A_FMR: implementation-data-type=uint8
        CAN1_PAS_A_RCL: implementation-data-type=uint8
        CAN1_PAS_A_RCR: implementation-data-type=uint8
        CAN1_PAS_A_RML: implementation-data-type=uint8
        CAN1_PAS_A_RMR: implementation-data-type=uint8
        CAN1_PAS_Chime: implementation-data-type=uint8
        CAN1_PAS_D_FCL: implementation-data-type=uint8
        CAN1_PAS_D_FCR: implementation-data-type=uint8
        CAN1_PAS_D_FML: implementation-data-type=uint8
        CAN1_PAS_D_FMR: implementation-data-type=uint8
        CAN1_PAS_D_RCL: implementation-data-type=uint8
        CAN1_PAS_D_RCR: implementation-data-type=uint8
        CAN1_PAS_D_RML: implementation-data-type=uint8
        CAN1_PAS_D_RMR: implementation-data-type=uint8
        CAN1_PAS_Mod_Operation: implementation-data-type=uint8
        CAN1_PAS_SNSR_Layout: implementation-data-type=uint8
        CAN1_PAS_Sta_F_Sys: implementation-data-type=uint8
        CAN1_USS_Sta_FCL: implementation-data-type=uint8
        CAN1_USS_Sta_FCR: implementation-data-type=uint8
        CAN1_USS_Sta_FLL: implementation-data-type=uint8
        CAN1_USS_Sta_FLR: implementation-data-type=uint8
        CAN1_USS_Sta_FML: implementation-data-type=uint8
        CAN1_USS_Sta_FMR: implementation-data-type=uint8
        CAN1_USS_Sta_RCL: implementation-data-type=uint8
        CAN1_USS_Sta_RCR: implementation-data-type=uint8
        CAN1_USS_Sta_RLL: implementation-data-type=uint8
        CAN1_USS_Sta_RLR: implementation-data-type=uint8
        CAN1_USS_Sta_RML: implementation-data-type=uint8
        CAN1_USS_Sta_RMR: implementation-data-type=uint8
    DT_CAN1_SG_FD1_APS3
      28 x element, all with category=TYPE_REFERENCE:
        CAN1_APS3_LifeCount: implementation-data-type=uint8
        CAN1_APS3_checksum: implementation-data-type=uint8
        CAN1_APSOpenPTG: implementation-data-type=uint8
        CAN1_APS_DecReq: implementation-data-type=uint8
        CAN1_APS_DecReq_A: implementation-data-type=uint8
        CAN1_APS_Req: implementation-data-type=uint8
        CAN1_APS_Sta_System: implementation-data-type=uint8
        CAN1_CAAS_Sta: implementation-data-type=uint8
        CAN1_FDC_APS_Active_Sta: implementation-data-type=uint8
        CAN1_FDC_APS_CaasActive_Sta: implementation-data-type=uint8
        CAN1_FDC_APS_CaasCtrlAvail_Sta: implementation-data-type=uint8
        CAN1_FDC_APS_CaasVMCReqA_Cmd: implementation-data-type=uint8
        CAN1_FDC_APS_CtrlAvail_Sta: implementation-data-type=uint8
        CAN1_FDC_APS_ShftPosnReq_Cmd: implementation-data-type=uint8
        CAN1_FDC_APS_SpeedReq_Cmd: implementation-data-type=uint16
        CAN1_FDC_APS_VMCReqA_Cmd: implementation-data-type=uint8
        CAN1_FDC_RAPS_BCMLamp_Cmd: implementation-data-type=uint8
        CAN1_FDC_RAPS_BCMLockReq_Cmd: implementation-data-type=uint8
        CAN1_FDC_RAPS_ErrLv1_Flg: implementation-data-type=uint8
        CAN1_FDC_RAPS_PwrReqAvail_Sta: implementation-data-type=uint8
        CAN1_FDC_RAPS_PwrReq_Cmd: implementation-data-type=uint8
        CAN1_FDC_VCU_RAPSErrLv2_Flg: implementation-data-type=uint8
        CAN1_FDC_VCU_RAPSErrLv3_Flg: implementation-data-type=uint8
        CAN1_FDC_VMC_APS_Angle_Target: implementation-data-type=uint16
        CAN1_FDC_VMC_APS_Rq_EPS_Ctrl: implementation-data-type=uint8
        CAN1_FDC_VMC_APS_V_Rq_EPS_Ctrl: implementation-data-type=uint8
        CAN1_SPTGDet: implementation-data-type=uint8
        CAN1_SPTG_Sta: implementation-data-type=uint8
    DT_CAN1_SG_FD1_BCM1
      50 x element, all with category=TYPE_REFERENCE, implementation-data-type=uint8:
        CAN1_AllDoorSW
        CAN1_AntiTheftSeatFold
        CAN1_AntitheftSta
        CAN1_BCM_Buzzer_Req
        CAN1_BCM_DoorLock_Sta
        CAN1_BrakeLamp
        CAN1_CTDCtrl
        CAN1_CTDLockSW
        CAN1_CTDUnlockSW
        CAN1_CrashDetd
        CAN1_Dimmer
        CAN1_DimmerEN
        CAN1_DoorLockIND
        CAN1_DrDoorSW
        CAN1_Fr_ChargingDoorCtrl
        CAN1_Fr_FogLamp
        CAN1_Fr_Wiper_H
        CAN1_Fr_Wiper_L
        CAN1_H_Beam
        CAN1_HazardSW
        CAN1_HoodSW
        CAN1_HornCtrl
        CAN1_LBSD
        CAN1_LDRL
        CAN1_LTurnLP
        CAN1_L_APM_WdwEnable
        CAN1_L_Beam
        CAN1_LockSetting
        CAN1_MirrorCtrl
        CAN1_MirrorDefog
        CAN1_PosLamp
        CAN1_PsDoorSW
        CAN1_RBSD
        CAN1_RDRL
        CAN1_RLDoorSW
        CAN1_RRDoorSW
        CAN1_RTurnLP
        CAN1_ReverseLamp
        CAN1_RoomLampH
        CAN1_RoomLampL
        CAN1_Rr_ChargingDoorCtrl
        CAN1_Rr_Defog
        CAN1_Rr_FogLamp
        CAN1_Rr_Wiper
        CAN1_TailgateHDSW
        CAN1_TailgateRemote
        CAN1_Tailgate_SW
        CAN1_TrunkRel
        CAN1_WasherCtrl
        CAN1_WiperFixMode
    DT_CAN1_SG_FD1_THCM1
      37 x element, all with category=TYPE_REFERENCE:
        CAN1_BatteryMode: implementation-data-type=uint8
        CAN1_CCU_ACLampSts: implementation-data-type=uint8
        CAN1_CCU_ACMaxLampSts: implementation-data-type=uint8
        CAN1_CCU_AutoLampSts: implementation-data-type=uint8
        CAN1_CCU_AutoMidLampSts: implementation-data-type=uint8
        CAN1_CCU_Dispaly_Request: implementation-data-type=uint8
        CAN1_CCU_EcoSts: implementation-data-type=uint8
        CAN1_CCU_FrtOnOffLampSts: implementation-data-type=uint8
        CAN1_CCU_HEATMaxLampSts: implementation-data-type=uint8
        CAN1_CCU_RrOnOffLampSts: implementation-data-type=uint8
        CAN1_CCU_SyncLampSts: implementation-data-type=uint8
        CAN1_CabinMode: implementation-data-type=uint8
        CAN1_EDriveMode: implementation-data-type=uint8
        CAN1_FD_AGS_Cmd: implementation-data-type=uint8
        CAN1_FD_RecyAuto_Cmd: implementation-data-type=uint8
        CAN1_Fr_Coolantflow: implementation-data-type=uint8
        CAN1_Fr_Coolanttemp: implementation-data-type=uint16
        CAN1_HPThermalRecoveryReq: implementation-data-type=uint8
        CAN1_Rr_Coolantflow: implementation-data-type=uint8
        CAN1_Rr_Coolanttemp: implementation-data-type=uint16
        CAN1_sigAirIntenZon1St: implementation-data-type=uint8
        CAN1_sigAirIntenZon3St: implementation-data-type=uint8
        CAN1_sigAmbAirT: implementation-data-type=uint8
        CAN1_sigCbnAirT: implementation-data-type=uint8
        CAN1_sigCbnPTCPwrAct: implementation-data-type=uint8
        CAN1_sigCbnSolarLeft: implementation-data-type=uint8
        CAN1_sigCbnSolarRight: implementation-data-type=uint8
        CAN1_sigClmtCmprPwrAct: implementation-data-type=uint8
        CAN1_sigClntTHvBattOut: implementation-data-type=uint8
        CAN1_sigDfrstSt: implementation-data-type=uint8
        CAN1_sigHvacSt: implementation-data-type=uint8
        CAN1_sigRecircSt: implementation-data-type=uint8
        CAN1_sigSetTempZon{1..3}St: implementation-data-type=uint8
        CAN1_sigWindDirZon1St: implementation-data-type=uint8
        CAN1_sigWindDirZon3St: implementation-data-type=uint8
    DT_CAN1_SG_FD1_VCU1
      15 x element, all with category=TYPE_REFERENCE, implementation-data-type=uint8:
        CAN1_CC_Crl_Sta
        CAN1_Eng_AGSCloseSta
        CAN1_Eng_ActvDmpDisabSta
        CAN1_Eng_CoastDwSta
        CAN1_Eng_PwrLockSta
        CAN1_HVPwrSta
        CAN1_LVPwrSta
        CAN1_MSA_Crl_Sta
        CAN1_P_Button_Sta
        CAN1_PrkReq
        CAN1_PrkReqValid
        CAN1_PwrSta
        CAN1_ShiftGearPosn
        CAN1_VehMalfunLevel
        CAN1_XWDMode
    DT_CAN1_SG_FD1_VCU2
      9 x element, all with category=TYPE_REFERENCE:
        CAN1_ACC_CtrlAvail: implementation-data-type=uint8
        CAN1_AccPedal_Override: implementation-data-type=uint8
        CAN1_ActAPSPosn: implementation-data-type=uint8
        CAN1_CS_VCU2_CAN1: implementation-data-type=uint8
        CAN1_DriverTq: implementation-data-type=uint16
        CAN1_Fr_DriverTq: implementation-data-type=uint16
        CAN1_RC_VCU2_CAN1: implementation-data-type=uint8
        CAN1_Rr_DriverTq: implementation-data-type=uint16
        CAN1_VehActPwr: implementation-data-type=uint32
    DT_CAN1_SG_FD1_VCU3
      21 x element, all with category=TYPE_REFERENCE:
        CAN1_CS_VCU3_CAN1: implementation-data-type=uint8
        CAN1_EquivAccPedalSWSta: implementation-data-type=uint8
        CAN1_Fr_EDUAvailBrkRgnTq: implementation-data-type=uint16
        CAN1_Fr_EDUAvailBrkRgnTqValid: implementation-data-type=uint8
        CAN1_Fr_EDURealARgnTq: implementation-data-type=uint16
        CAN1_Fr_EDURealDrvOrBRgnTq: implementation-data-type=uint16
        CAN1_Fr_EDUSpd: implementation-data-type=uint16
        CAN1_Fr_EDUSpdValid: implementation-data-type=uint8
        CAN1_Fr_RgnDecrSta: implementation-data-type=uint8
        CAN1_Fr_RgnPermSta: implementation-data-type=uint8
        CAN1_PTCS_PermSta: implementation-data-type=uint8
        CAN1_RC_VCU3_CAN1: implementation-data-type=uint8
        CAN1_RgnAbnorSta: implementation-data-type=uint8
        CAN1_Rr_EDUAvailBrkRgnTq: implementation-data-type=uint16
        CAN1_Rr_EDUAvailBrkRgnTqValid: implementation-data-type=uint8
        CAN1_Rr_EDURealARgnTq: implementation-data-type=uint16
        CAN1_Rr_EDURealDrvOrBRgnTq: implementation-data-type=uint16
        CAN1_Rr_EDUSpd: implementation-data-type=uint16
        CAN1_Rr_EDUSpdValid: implementation-data-type=uint8
        CAN1_Rr_RgnDecrSta: implementation-data-type=uint8
        CAN1_Rr_RgnPermSta: implementation-data-type=uint8
    DT_CAN1_SG_FD1_VMC1
      33 x element, all with category=TYPE_REFERENCE:
        CAN1_AccCalcuPID: implementation-data-type=uint16
        CAN1_CCMSA_SpdWar: implementation-data-type=uint8
        CAN1_DISCReqAcc: implementation-data-type=uint16
        CAN1_DISC_ButtSta: implementation-data-type=uint8
        CAN1_DISC_DISCTargetSpd: implementation-data-type=uint16
        CAN1_DISC_DISCTurn: implementation-data-type=uint8
        CAN1_DISC_Sta: implementation-data-type=uint8
        CAN1_FeatArbitrFinal: implementation-data-type=uint8
        CAN1_FeatArbitrSta: implementation-data-type=uint8
        CAN1_FeatReqSpd: implementation-data-type=uint16
        CAN1_FeatSetSpdFinal_raw32: implementation-data-type=uint8
        CAN1_FrontRearSlipRatioCtrl: implementation-data-type=uint8
        CAN1_JerkPCT: implementation-data-type=uint8
        CAN1_LatAccCtrl: implementation-data-type=uint8
        CAN1_LateralCtrl: implementation-data-type=uint8
        CAN1_LimitPCT: implementation-data-type=uint8
        CAN1_MeterIndSpeed_raw32: implementation-data-type=uint8
        CAN1_RearWhlSlipRatioCtrl: implementation-data-type=uint8
        CAN1_SPD2ACCAct: implementation-data-type=uint8
        CAN1_SafetyCtrl: implementation-data-type=uint8
        CAN1_SingleWhlSlipRatioCtrl: implementation-data-type=uint8
        CAN1_TimeGapCalcu: implementation-data-type=uint8
        CAN1_VMC_ACCCtrlAvail: implementation-data-type=uint8
        CAN1_VMC_AEBCtrlAvail: implementation-data-type=uint8
        CAN1_VMC_CCCtrlAvail: implementation-data-type=uint8
        CAN1_VMC_MSACtrlAvail: implementation-data-type=uint8
        CAN1_VMC_VCU_ACC_CtrlAvail: implementation-data-type=uint8
        CAN1_VMC_VCU_APSCtrlAvail_flg: implementation-data-type=uint8
        CAN1_VMC_VCU_AccPedal_Override: implementation-data-type=uint8
        CAN1_VMC_VCU_CC_Crl_Sta: implementation-data-type=uint8
        CAN1_VMC_VCU_MSA_Crl_Sta: implementation-data-type=uint8
        CAN1_VehicleSpeed_kph: implementation-data-type=uint16
        CAN1_VehicleSpeed_mph: implementation-data-type=uint16
    DT_CAN1_SG_FD1_VMC2
      4 x element, all with category=TYPE_REFERENCE:
        CAN1_FDC_VMC_RWS_Actv_Sta: implementation-data-type=uint8
        CAN1_FDC_VMC_RWS_Dfctv_Sta: implementation-data-type=uint8
        CAN1_FDC_VMC_RWS_PositionReq_Cmd: implementation-data-type=uint16
        CAN1_FDC_VMC_SteerFaultReq_Cmd: implementation-data-type=uint8
    DT_CAN1_SG_GW1_CE100_0
      element CAN1_BMS_READY: implementation-data-type=uint8
      element CAN1_Fr_TMSpd: implementation-data-type=uint16
      element CAN1_Rr_TMSpd: implementation-data-type=uint16
    DT_CAN1_SG_GW1_CE200_0
      4 x element, all with category=TYPE_REFERENCE, implementation-data-type=uint8:
        CAN1_ESC_SW_Cmd
        CAN1_Roll_Eng_Mode
        CAN1_Roll_Mode_SW_Cmd
        CAN1_TCS_SW_Cmd
    DT_CAN1_SG_VMC_FCM1
      24 x element, all with category=TYPE_REFERENCE:
        CAN1_FDC_VMC_AngCtrlTqWtGn: implementation-data-type=uint8
        CAN1_FDC_VMC_DMSMode_Cmd: implementation-data-type=uint8
        CAN1_FDC_VMC_DrInpTqBstAct: implementation-data-type=uint8
        CAN1_FDC_VMC_DrInpTqBstGn: implementation-data-type=uint8
        CAN1_FDC_VMC_MaxAngCtrlOutTqLim: implementation-data-type=uint16
        CAN1_VMC_ACC_ComfortBandLower: implementation-data-type=uint16
        CAN1_VMC_ACC_ComfortBandUpper: implementation-data-type=uint16
        CAN1_VMC_ACC_JerkLowerLInit: implementation-data-type=uint8
        CAN1_VMC_ACC_JerkUpperLInit: implementation-data-type=uint8
        CAN1_VMC_ACC_RequiredAccel: implementation-data-type=uint16
        CAN1_VMC_ACC_VehHoldReq: implementation-data-type=uint8
        CAN1_VMC_ADAS_ACC_Sta: implementation-data-type=uint8
        CAN1_VMC_ADAS_AEBReq: implementation-data-type=uint8
        CAN1_VMC_ADAS_AEB_Sta: implementation-data-type=uint8
        CAN1_VMC_ADAS_DBSReq: implementation-data-type=uint8
        CAN1_VMC_ADAS_FaultSta: implementation-data-type=uint8
        CAN1_VMC_AEB_VehHoldReq: implementation-data-type=uint8
        CAN1_VMC_FCM1_Checksum: implementation-data-type=uint8
        CAN1_VMC_FCM1_LifeCount: implementation-data-type=uint8
        CAN1_VMC_FCM_LDW_Fault: implementation-data-type=uint8
        CAN1_VMC_FCM_LDW_Request: implementation-data-type=uint8
        CAN1_VMC_FCM_LKA_StrToqReq: implementation-data-type=uint16
        CAN1_VMC_FCM_LKA_TOIAct: implementation-data-type=uint8
        CAN1_VMC_FCM_LKA_TOIFault: implementation-data-type=uint8
    DT_CAN1_SG_eBST1
      4 x element, all with category=TYPE_REFERENCE, implementation-data-type=uint8:
        CAN1_LowBrakeFluid_Sta
        CAN1_eBST_AmberWnlmpSta
        CAN1_eBST_BeepReq
        CAN1_eBST_RedWnlmpSta
